VERSION "HNNBNNNYNNNNNNNNNNNNNNNNNNNNNNNNNNNNNNNNNN/4/%%%/4/'%**4NNN///"

NS_ :

BS_:

BU_: AEM BAP_Tester E_Sound FBK FLA Gateway Gateway_PAG ISE MRR_HL MRR_HR NightVision RDK SAK SAK2 SCR STH_MLBevo TopView

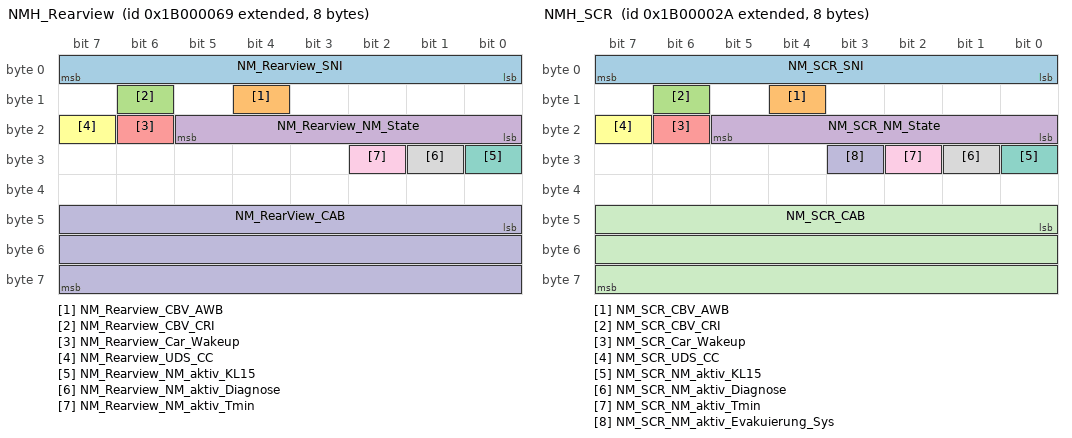
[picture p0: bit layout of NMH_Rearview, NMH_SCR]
BO_ 2600468585 NMH_Rearview: 8 TopView
 SG_ NM_Rearview_SNI : 0|8@1+ (1.0,0.0) [0.0|255] ""  Gateway,Gateway_PAG,MRR_HL,MRR_HR,NightVision,RDK,SCR,STH_MLBevo
 SG_ NM_Rearview_CBV_AWB : 12|1@1+ (1.0,0.0) [0.0|1] ""  Gateway,Gateway_PAG
 SG_ NM_Rearview_CBV_CRI : 14|1@1+ (1.0,0.0) [0.0|1] ""  Gateway,Gateway_PAG,MRR_HL,MRR_HR,NightVision,RDK,SCR,STH_MLBevo
 SG_ NM_Rearview_NM_State : 16|6@1+ (1.0,0.0) [0.0|63] ""  Vector__XXX
 SG_ NM_Rearview_Car_Wakeup : 22|1@1+ (1.0,0.0) [0.0|1] ""  Gateway
 SG_ NM_Rearview_UDS_CC : 23|1@1+ (1.0,0.0) [0.0|1] ""  Vector__XXX
 SG_ NM_Rearview_NM_aktiv_KL15 : 24|1@1+ (1.0,0.0) [0.0|1] ""  Vector__XXX
 SG_ NM_Rearview_NM_aktiv_Diagnose : 25|1@1+ (1.0,0.0) [0.0|1] ""  Vector__XXX
 SG_ NM_Rearview_NM_aktiv_Tmin : 26|1@1+ (1.0,0.0) [0.0|1] ""  Vector__XXX
 SG_ NM_RearView_CAB : 40|24@1+ (1.0,0.0) [0.0|16777215] ""  Gateway,Gateway_PAG,MRR_HL,MRR_HR,NightVision,RDK,SCR,STH_MLBevo

BO_ 2600468522 NMH_SCR: 8 SCR
 SG_ NM_SCR_SNI : 0|8@1+ (1.0,0.0) [0.0|255] ""  Gateway,Gateway_PAG,MRR_HL,MRR_HR,NightVision,RDK,STH_MLBevo,TopView
 SG_ NM_SCR_CBV_AWB : 12|1@1+ (1.0,0.0) [0.0|1] ""  Gateway,Gateway_PAG
 SG_ NM_SCR_CBV_CRI : 14|1@1+ (1.0,0.0) [0.0|1] ""  Gateway,Gateway_PAG,MRR_HL,MRR_HR,NightVision,RDK,STH_MLBevo,TopView
 SG_ NM_SCR_NM_State : 16|6@1+ (1.0,0.0) [0.0|63] ""  Vector__XXX
 SG_ NM_SCR_Car_Wakeup : 22|1@1+ (1.0,0.0) [0.0|1] ""  Gateway,Gateway_PAG
 SG_ NM_SCR_UDS_CC : 23|1@1+ (1.0,0.0) [0.0|1] ""  Vector__XXX
 SG_ NM_SCR_NM_aktiv_KL15 : 24|1@1+ (1.0,0.0) [0.0|1] ""  Vector__XXX
 SG_ NM_SCR_NM_aktiv_Diagnose : 25|1@1+ (1.0,0.0) [0.0|1] ""  Vector__XXX
 SG_ NM_SCR_NM_aktiv_Tmin : 26|1@1+ (1.0,0.0) [0.0|1] ""  Vector__XXX
 SG_ NM_SCR_NM_aktiv_Evakuierung_Sys : 27|1@1+ (1.0,0.0) [0.0|1] ""  Vector__XXX
 SG_ NM_SCR_CAB : 40|24@1+ (1.0,0.0) [0.0|16777215] ""  Gateway,Gateway_PAG,MRR_HL,MRR_HR,NightVision,RDK,STH_MLBevo,TopView

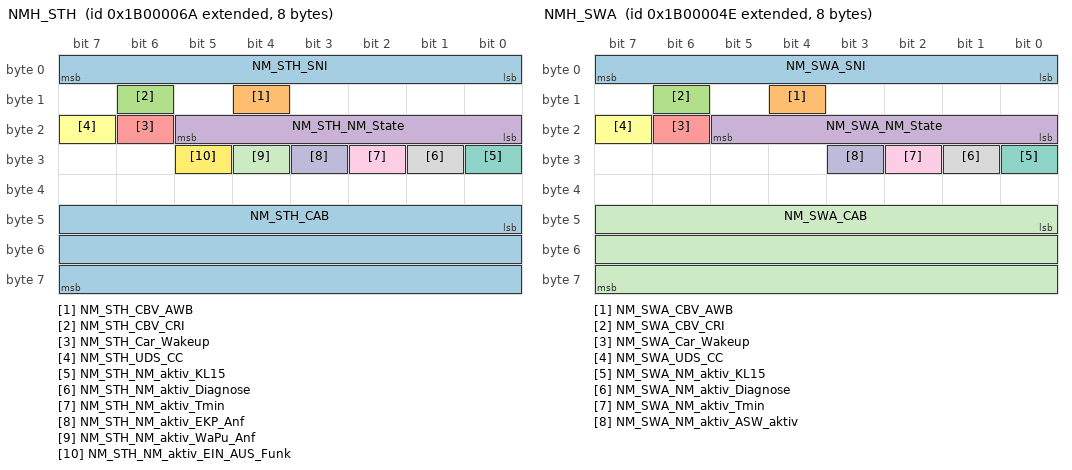
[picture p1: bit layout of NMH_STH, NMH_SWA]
BO_ 2600468586 NMH_STH: 8 STH_MLBevo
 SG_ NM_STH_SNI : 0|8@1+ (1.0,0.0) [0.0|255] ""  Gateway,Gateway_PAG,MRR_HL,MRR_HR,NightVision,RDK,SCR,TopView
 SG_ NM_STH_CBV_AWB : 12|1@1+ (1.0,0.0) [0.0|1] ""  Gateway,Gateway_PAG
 SG_ NM_STH_CBV_CRI : 14|1@1+ (1.0,0.0) [0.0|1] ""  Gateway,Gateway_PAG,MRR_HL,MRR_HR,NightVision,RDK,SCR,TopView
 SG_ NM_STH_NM_State : 16|6@1+ (1.0,0.0) [0.0|63] ""  Vector__XXX
 SG_ NM_STH_Car_Wakeup : 22|1@1+ (1.0,0.0) [0.0|1] ""  Gateway,Gateway_PAG
 SG_ NM_STH_UDS_CC : 23|1@1+ (1.0,0.0) [0.0|1] ""  Vector__XXX
 SG_ NM_STH_NM_aktiv_KL15 : 24|1@1+ (1.0,0.0) [0.0|1] ""  Vector__XXX
 SG_ NM_STH_NM_aktiv_Diagnose : 25|1@1+ (1.0,0.0) [0.0|1] ""  Vector__XXX
 SG_ NM_STH_NM_aktiv_Tmin : 26|1@1+ (1.0,0.0) [0.0|1] ""  Vector__XXX
 SG_ NM_STH_NM_aktiv_EKP_Anf : 27|1@1+ (1.0,0.0) [0.0|1] ""  Vector__XXX
 SG_ NM_STH_NM_aktiv_WaPu_Anf : 28|1@1+ (1.0,0.0) [0.0|1] ""  Vector__XXX
 SG_ NM_STH_NM_aktiv_EIN_AUS_Funk : 29|1@1+ (1.0,0.0) [0.0|1] ""  Vector__XXX
 SG_ NM_STH_CAB : 40|24@1+ (1.0,0.0) [0.0|16777215] ""  Gateway,Gateway_PAG,MRR_HL,MRR_HR,NightVision,RDK,SCR,TopView

BO_ 2600468558 NMH_SWA: 8 MRR_HR
 SG_ NM_SWA_SNI : 0|8@1+ (1.0,0.0) [0.0|255] ""  Gateway,Gateway_PAG,MRR_HL,NightVision,RDK,SCR,STH_MLBevo,TopView
 SG_ NM_SWA_CBV_AWB : 12|1@1+ (1.0,0.0) [0.0|1] ""  Gateway,Gateway_PAG
 SG_ NM_SWA_CBV_CRI : 14|1@1+ (1.0,0.0) [0.0|1] ""  Gateway,Gateway_PAG,MRR_HL,NightVision,RDK,SCR,STH_MLBevo,TopView
 SG_ NM_SWA_NM_State : 16|6@1+ (1.0,0.0) [0.0|63] ""  Vector__XXX
 SG_ NM_SWA_Car_Wakeup : 22|1@1+ (1.0,0.0) [0.0|1] ""  Gateway,Gateway_PAG
 SG_ NM_SWA_UDS_CC : 23|1@1+ (1.0,0.0) [0.0|1] ""  Vector__XXX
 SG_ NM_SWA_NM_aktiv_KL15 : 24|1@1+ (1.0,0.0) [0.0|1] ""  Vector__XXX
 SG_ NM_SWA_NM_aktiv_Diagnose : 25|1@1+ (1.0,0.0) [0.0|1] ""  Vector__XXX
 SG_ NM_SWA_NM_aktiv_Tmin : 26|1@1+ (1.0,0.0) [0.0|1] ""  Vector__XXX
 SG_ NM_SWA_NM_aktiv_ASW_aktiv : 27|1@1+ (1.0,0.0) [0.0|1] ""  Vector__XXX
 SG_ NM_SWA_CAB : 40|24@1+ (1.0,0.0) [0.0|16777215] ""  Gateway,Gateway_PAG,MRR_HL,NightVision,RDK,SCR,STH_MLBevo,TopView

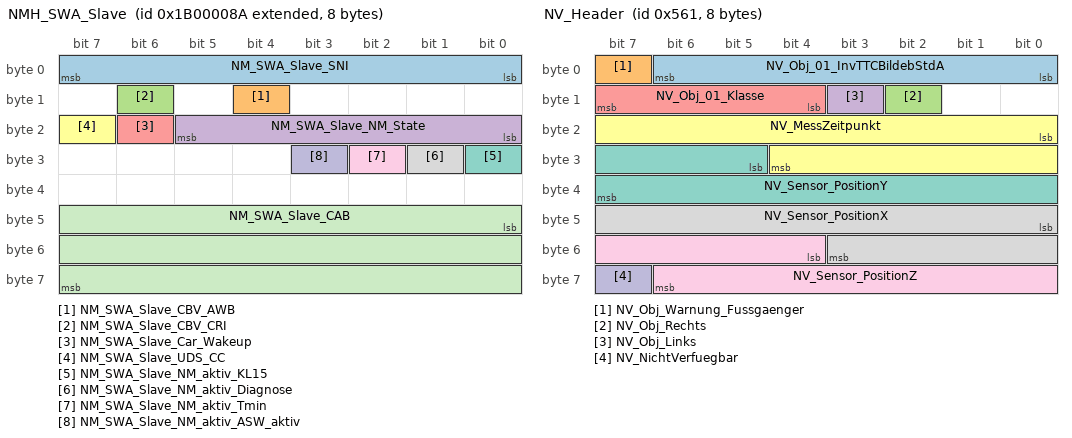
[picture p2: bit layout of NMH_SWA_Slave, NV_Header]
BO_ 2600468618 NMH_SWA_Slave: 8 MRR_HL
 SG_ NM_SWA_Slave_SNI : 0|8@1+ (1.0,0.0) [0.0|255] ""  Gateway,Gateway_PAG,MRR_HR,NightVision,RDK,SCR,STH_MLBevo,TopView
 SG_ NM_SWA_Slave_CBV_AWB : 12|1@1+ (1.0,0.0) [0.0|1] ""  Gateway,Gateway_PAG
 SG_ NM_SWA_Slave_CBV_CRI : 14|1@1+ (1.0,0.0) [0.0|1] ""  Gateway,Gateway_PAG,MRR_HR,NightVision,RDK,SCR,STH_MLBevo,TopView
 SG_ NM_SWA_Slave_NM_State : 16|6@1+ (1.0,0.0) [0.0|63] ""  Vector__XXX
 SG_ NM_SWA_Slave_Car_Wakeup : 22|1@1+ (1.0,0.0) [0.0|1] ""  Gateway
 SG_ NM_SWA_Slave_UDS_CC : 23|1@1+ (1.0,0.0) [0.0|1] ""  Vector__XXX
 SG_ NM_SWA_Slave_NM_aktiv_KL15 : 24|1@1+ (1.0,0.0) [0.0|1] ""  Vector__XXX
 SG_ NM_SWA_Slave_NM_aktiv_Diagnose : 25|1@1+ (1.0,0.0) [0.0|1] ""  Vector__XXX
 SG_ NM_SWA_Slave_NM_aktiv_Tmin : 26|1@1+ (1.0,0.0) [0.0|1] ""  Vector__XXX
 SG_ NM_SWA_Slave_NM_aktiv_ASW_aktiv : 27|1@1+ (1.0,0.0) [0.0|1] ""  Vector__XXX
 SG_ NM_SWA_Slave_CAB : 40|24@1+ (1.0,0.0) [0.0|16777215] ""  Gateway,Gateway_PAG,MRR_HR,NightVision,RDK,SCR,STH_MLBevo,TopView

BO_ 1377 NV_Header: 8 NightVision
 SG_ NV_Obj_01_InvTTCBildebStdA : 0|7@1+ (0.0625,0) [0.0000|7.8750] "Unit_Hertz"  Gateway,Gateway_PAG
 SG_ NV_Obj_Warnung_Fussgaenger : 7|1@1+ (1.0,0.0) [0.0|1] ""  Gateway,Gateway_PAG
 SG_ NV_Obj_Rechts : 10|1@1+ (1.0,0.0) [0.0|1] ""  Gateway,Gateway_PAG
 SG_ NV_Obj_Links : 11|1@1+ (1.0,0.0) [0.0|1] ""  Gateway,Gateway_PAG
 SG_ NV_Obj_01_Klasse : 12|4@1+ (1.0,0.0) [0.0|15] ""  Gateway,Gateway_PAG
 SG_ NV_MessZeitpunkt : 16|13@1+ (0.001,0) [0.000|8.190] "Unit_Secon"  Gateway,Gateway_PAG
 SG_ NV_Sensor_PositionY : 29|11@1+ (0.001,-1) [-1.000|1.046] "Unit_Meter"  Gateway,Gateway_PAG
 SG_ NV_Sensor_PositionX : 40|12@1+ (0.001,1) [1.000|5.094] "Unit_Meter"  Gateway,Gateway_PAG
 SG_ NV_Sensor_PositionZ : 52|11@1+ (0.001,0) [0.000|2.046] "Unit_Meter"  Gateway,Gateway_PAG
 SG_ NV_NichtVerfuegbar : 63|1@1+ (1.0,0.0) [0.0|1] ""  Gateway,Gateway_PAG

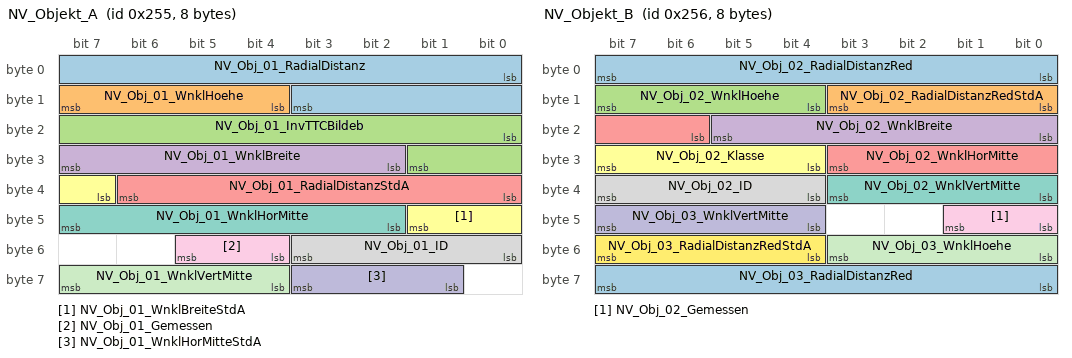
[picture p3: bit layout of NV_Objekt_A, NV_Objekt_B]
BO_ 597 NV_Objekt_A: 8 NightVision
 SG_ NV_Obj_01_RadialDistanz : 0|12@1+ (0.0625,0) [0.0000|255.8750] "Unit_Meter"  Gateway,Gateway_PAG
 SG_ NV_Obj_01_WnklHoehe : 12|4@1+ (0.03125,0) [0.00000|0.43750] "Unit_Radia"  Gateway,Gateway_PAG
 SG_ NV_Obj_01_InvTTCBildeb : 16|10@1+ (0.015625,-8) [-8.000000|7.968750] "Unit_Hertz"  Gateway,Gateway_PAG
 SG_ NV_Obj_01_WnklBreite : 26|6@1+ (0.0078125,0) [0E-7|0.4843750] "Unit_Radia"  Gateway,Gateway_PAG
 SG_ NV_Obj_01_RadialDistanzStdA : 32|7@1+ (0.25,0) [0.00|31.50] "Unit_Meter"  Gateway,Gateway_PAG
 SG_ NV_Obj_01_WnklBreiteStdA : 39|3@1+ (0.015625,0) [0.000000|0.093750] "Unit_Radia"  Gateway,Gateway_PAG
 SG_ NV_Obj_01_WnklHorMitte : 42|6@1+ (0.0078125,-0.2421875) [-0.2421875|0.2421875] "Unit_Radia"  Gateway,Gateway_PAG
 SG_ NV_Obj_01_ID : 48|4@1+ (1.0,0.0) [0.0|15] ""  Gateway,Gateway_PAG
 SG_ NV_Obj_01_Gemessen : 52|2@1+ (1.0,0.0) [0.0|3] ""  Gateway,Gateway_PAG
 SG_ NV_Obj_01_WnklHorMitteStdA : 57|3@1+ (0.015625,0) [0.000000|0.093750] "Unit_Radia"  Gateway,Gateway_PAG
 SG_ NV_Obj_01_WnklVertMitte : 60|4@1+ (0.03125,-0.21875) [-0.21875|0.21875] "Unit_Radia"  Gateway,Gateway_PAG

BO_ 598 NV_Objekt_B: 8 NightVision
 SG_ NV_Obj_02_RadialDistanzRed : 0|8@1+ (0.5,3) [3.0|130.0] "Unit_Meter"  Gateway,Gateway_PAG
 SG_ NV_Obj_02_RadialDistanzRedStdA : 8|4@1+ (1,0) [0|14] "Unit_Meter"  Gateway,Gateway_PAG
 SG_ NV_Obj_02_WnklHoehe : 12|4@1+ (0.03125,0) [0.00000|0.43750] "Unit_Radia"  Gateway,Gateway_PAG
 SG_ NV_Obj_02_WnklBreite : 16|6@1+ (0.0078125,0) [0E-7|0.4843750] "Unit_Radia"  Gateway,Gateway_PAG
 SG_ NV_Obj_02_WnklHorMitte : 22|6@1+ (0.0078125,-0.2421875) [-0.2421875|0.2421875] "Unit_Radia"  Gateway,Gateway_PAG
 SG_ NV_Obj_02_Klasse : 28|4@1+ (1.0,0.0) [0.0|15] ""  Gateway,Gateway_PAG
 SG_ NV_Obj_02_WnklVertMitte : 32|4@1+ (0.03125,-0.21875) [-0.21875|0.21875] "Unit_Radia"  Gateway,Gateway_PAG
 SG_ NV_Obj_02_ID : 36|4@1+ (1.0,0.0) [0.0|15] ""  Gateway,Gateway_PAG
 SG_ NV_Obj_02_Gemessen : 40|2@1+ (1.0,0.0) [0.0|3] ""  Gateway,Gateway_PAG
 SG_ NV_Obj_03_WnklVertMitte : 44|4@1+ (0.03125,-0.21875) [-0.21875|0.21875] "Unit_Radia"  Gateway,Gateway_PAG
 SG_ NV_Obj_03_WnklHoehe : 48|4@1+ (0.03125,0) [0.00000|0.43750] "Unit_Radia"  Gateway,Gateway_PAG
 SG_ NV_Obj_03_RadialDistanzRedStdA : 52|4@1+ (1,0) [0|14] "Unit_Meter"  Gateway,Gateway_PAG
 SG_ NV_Obj_03_RadialDistanzRed : 56|8@1+ (0.5,3) [3.0|130.0] "Unit_Meter"  Gateway,Gateway_PAG

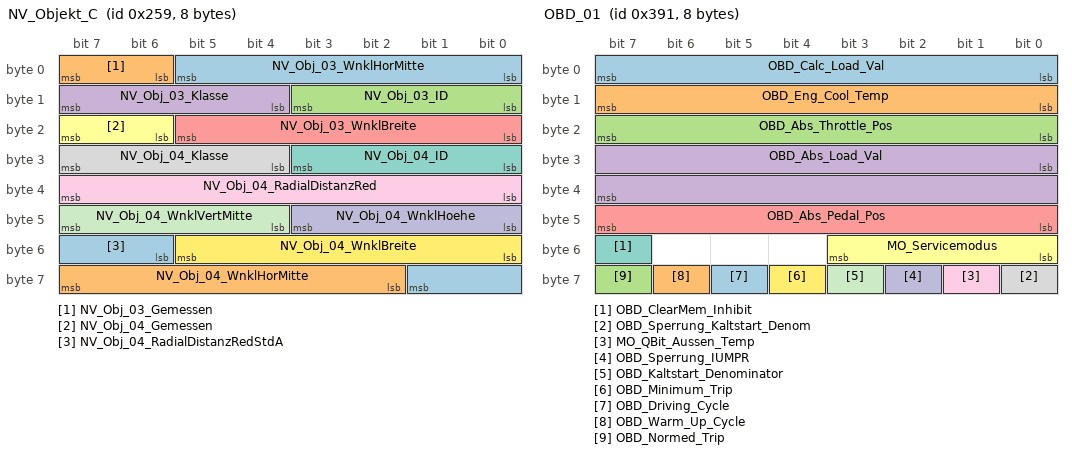
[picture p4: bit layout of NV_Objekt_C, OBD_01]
BO_ 601 NV_Objekt_C: 8 NightVision
 SG_ NV_Obj_03_WnklHorMitte : 0|6@1+ (0.0078125,-0.2421875) [-0.2421875|0.2421875] "Unit_Radia"  Gateway,Gateway_PAG
 SG_ NV_Obj_03_Gemessen : 6|2@1+ (1.0,0.0) [0.0|3] ""  Gateway,Gateway_PAG
 SG_ NV_Obj_03_ID : 8|4@1+ (1.0,0.0) [0.0|15] ""  Gateway,Gateway_PAG
 SG_ NV_Obj_03_Klasse : 12|4@1+ (1.0,0.0) [0.0|15] ""  Gateway,Gateway_PAG
 SG_ NV_Obj_03_WnklBreite : 16|6@1+ (0.0078125,0) [0E-7|0.4843750] "Unit_Radia"  Gateway,Gateway_PAG
 SG_ NV_Obj_04_Gemessen : 22|2@1+ (1.0,0.0) [0.0|3] ""  Gateway,Gateway_PAG
 SG_ NV_Obj_04_ID : 24|4@1+ (1.0,0.0) [0.0|15] ""  Gateway,Gateway_PAG
 SG_ NV_Obj_04_Klasse : 28|4@1+ (1.0,0.0) [0.0|15] ""  Gateway,Gateway_PAG
 SG_ NV_Obj_04_RadialDistanzRed : 32|8@1+ (0.5,3) [3.0|130.0] "Unit_Meter"  Gateway,Gateway_PAG
 SG_ NV_Obj_04_WnklHoehe : 40|4@1+ (0.03125,0) [0.00000|0.43750] "Unit_Radia"  Gateway,Gateway_PAG
 SG_ NV_Obj_04_WnklVertMitte : 44|4@1+ (0.03125,-0.21875) [-0.21875|0.21875] "Unit_Radia"  Gateway,Gateway_PAG
 SG_ NV_Obj_04_WnklBreite : 48|6@1+ (0.0078125,0) [0E-7|0.4843750] "Unit_Radia"  Gateway,Gateway_PAG
 SG_ NV_Obj_04_RadialDistanzRedStdA : 54|4@1+ (1,0) [0|14] "Unit_Meter"  Gateway,Gateway_PAG
 SG_ NV_Obj_04_WnklHorMitte : 58|6@1+ (0.0078125,-0.2421875) [-0.2421875|0.2421875] "Unit_Radia"  Gateway,Gateway_PAG

BO_ 1635 NVEM_02: 8 Gateway
 SG_ BEM_02_Abschaltstufen : 0|3@1+ (1.0,0.0) [0.0|7] ""  MRR_HL,MRR_HR,STH_MLBevo
 SG_ BEM_STH_Zielzeit : 3|4@1+ (5,0) [0|60] "Unit_Minut"  Vector__XXX
 SG_ BEM_MMI_Vorwarnung : 7|1@1+ (1.0,0.0) [0.0|1] ""  Vector__XXX
 SG_ NVEM_Anf_SD_schalten : 15|1@1+ (1.0,0.0) [0.0|1] ""  Vector__XXX
 SG_ BEM_Generatordiagnose : 16|2@1+ (1.0,0.0) [0.0|3] ""  Vector__XXX
 SG_ BEM_Red_Innengeblaese : 18|2@1+ (1.0,0.0) [0.0|3] ""  Vector__XXX
 SG_ BEM_STH_Einschaltverbot : 20|1@1+ (1.0,0.0) [0.0|1] ""  STH_MLBevo
 SG_ BEM_HL_Regelung_Status : 21|3@1+ (1.0,0.0) [0.0|7] ""  STH_MLBevo
 SG_ BEM_Ladezustand : 24|4@1+ (10,0) [0|100] "Unit_PerCent"  Vector__XXX
 SG_ BEM_Batteriediagnose : 28|3@1+ (1.0,0.0) [0.0|7] ""  Vector__XXX
 SG_ MIB_Stromsparmodus : 31|1@1+ (1.0,0.0) [0.0|1] ""  Vector__XXX
 SG_ BEM_REK_aktiv : 37|1@1+ (1.0,0.0) [0.0|1] ""  Vector__XXX
 SG_ NVEM_Last_Anf : 38|2@1+ (1.0,0.0) [0.0|3] ""  Vector__XXX
 SG_ BEM_UBDM : 40|8@1+ (0.05,5) [5.05|17.70] "Unit_Volt"  Vector__XXX
 SG_ BEM_UGenSoll : 48|6@1+ (0.1,10.6) [10.6|16.0] "Unit_Volt"  Vector__XXX
 SG_ BEM_Anf_KL15_schalten : 54|2@1+ (1.0,0.0) [0.0|3] ""  MRR_HL,MRR_HR
 SG_ NVEM_Batterie_Service : 56|2@1+ (1.0,0.0) [0.0|3] ""  Vector__XXX
 SG_ NVEM_Freigabe_OnlineUpdate : 58|1@1+ (1.0,0.0) [0.0|1] ""  Vector__XXX
 SG_ NVEM_Freigabe_ORU4 : 59|2@1+ (1.0,0.0) [0.0|3] ""  Vector__XXX

BO_ 913 OBD_01: 8 Gateway
 SG_ OBD_Calc_Load_Val : 0|8@1+ (0.39215686274509803,0) [0E-17|99.99999999999999765] "Unit_PerCent"  SCR
 SG_ OBD_Eng_Cool_Temp : 8|8@1+ (1,-40) [-40|215] "Unit_DegreCelsi"  SCR
 SG_ OBD_Abs_Throttle_Pos : 16|8@1+ (0.39215686274509803,0) [0E-17|99.99999999999999765] "Unit_PerCent"  SCR
 SG_ OBD_Abs_Load_Val : 24|16@1+ (0.39215686274509803,0) [0E-17|25699.99999999999939605] "Unit_PerCent"  SCR
 SG_ OBD_Abs_Pedal_Pos : 40|8@1+ (0.39215686274509803,0) [0E-17|99.99999999999999765] "Unit_PerCent"  SCR
 SG_ MO_Servicemodus : 48|4@1+ (1.0,0.0) [0.0|15] ""  Vector__XXX
 SG_ OBD_ClearMem_Inhibit : 55|1@1+ (1.0,0.0) [0.0|1] ""  Vector__XXX
 SG_ OBD_Sperrung_Kaltstart_Denom : 56|1@1+ (1.0,0.0) [0.0|1] ""  Vector__XXX
 SG_ MO_QBit_Aussen_Temp : 57|1@1+ (1.0,0.0) [0.0|1] ""  SCR
 SG_ OBD_Sperrung_IUMPR : 58|1@1+ (1.0,0.0) [0.0|1] ""  SCR
 SG_ OBD_Kaltstart_Denominator : 59|1@1+ (1.0,0.0) [0.0|1] ""  SCR
 SG_ OBD_Minimum_Trip : 60|1@1+ (1.0,0.0) [0.0|1] ""  SCR
 SG_ OBD_Driving_Cycle : 61|1@1+ (1.0,0.0) [0.0|1] ""  SCR
 SG_ OBD_Warm_Up_Cycle : 62|1@1+ (1.0,0.0) [0.0|1] ""  SCR
 SG_ OBD_Normed_Trip : 63|1@1+ (1.0,0.0) [0.0|1] ""  SCR

BO_ 2589283478 OBD_02: 8 Gateway
 SG_ OBD_Aussen_Temp_gef : 56|8@1+ (1,-40) [-40|213] "Unit_DegreCelsi"  SCR

BO_ 2549875246 OBDC_AEM_Req: 8 Gateway
 SG_ OBDC_AEM_Req_Data : 0|64@1+ (1.0,0.0) [0.0|18446744073709551615] ""  AEM

BO_ 2550006318 OBDC_AEM_Resp: 8 AEM
 SG_ OBDC_AEM_Resp_Data : 0|64@1+ (1.0,0.0) [0.0|18446744073709551615] ""  Gateway,Gateway_PAG

BO_ 2549875248 OBDC_FLA_Req: 8 Gateway
 SG_ OBDC_FLA_Req_Data : 0|64@1+ (1.0,0.0) [0.0|18446744073709551615] ""  FLA

BO_ 2550006320 OBDC_FLA_Resp: 8 FLA
 SG_ OBDC_FLA_Resp_Data : 0|64@1+ (1.0,0.0) [0.0|18446744073709551615] ""  Gateway,Gateway_PAG

BO_ 2549940736 OBDC_Funktionaler_Req_All: 8 Gateway
 SG_ OBDC_Funktionaler_Req_All_Data : 0|64@1+ (1.0,0.0) [0.0|18446744073709551615] ""  AEM,E_Sound,FLA,ISE,MRR_HL,MRR_HR,NightVision,RDK,SAK,SAK2,SCR,STH_MLBevo,TopView

BO_ 2549875239 OBDC_Nightvision_Req: 8 Gateway
 SG_ OBDC_Nightvision_Req_Data : 0|64@1+ (1.0,0.0) [0.0|18446744073709551615] ""  NightVision

BO_ 2550006311 OBDC_Nightvision_Resp: 8 NightVision
 SG_ OBDC_Nightvision_Resp_Data : 0|64@1+ (1.0,0.0) [0.0|18446744073709551615] ""  Gateway,Gateway_PAG

BO_ 2549875211 OBDC_RDK_Req: 8 Gateway
 SG_ OBDC_RDK_Req_Data : 0|64@1+ (1.0,0.0) [0.0|18446744073709551615] ""  RDK

BO_ 2550006283 OBDC_RDK_Resp: 8 RDK
 SG_ OBDC_RDK_Resp_Data : 0|64@1+ (1.0,0.0) [0.0|18446744073709551615] ""  Gateway,Gateway_PAG

BO_ 2549875305 OBDC_Rearview_Req: 8 Gateway
 SG_ OBDC_Rearview_Req_Data : 0|64@1+ (1.0,0.0) [0.0|18446744073709551615] ""  TopView

BO_ 2550006377 OBDC_Rearview_Resp: 8 TopView
 SG_ OBDC_Rearview_Resp_Data : 0|64@1+ (1.0,0.0) [0.0|18446744073709551615] ""  Gateway,Gateway_PAG

BO_ 2549875242 OBDC_SCR_Req: 8 Gateway
 SG_ OBDC_SCR_Req_Data : 0|64@1+ (1.0,0.0) [0.0|18446744073709551615] ""  SCR

BO_ 2550006314 OBDC_SCR_Resp: 8 SCR
 SG_ OBDC_SCR_Resp_Data : 0|64@1+ (1.0,0.0) [0.0|18446744073709551615] ""  Gateway,Gateway_PAG

BO_ 2549875300 OBDC_Soundaktor2_Req: 8 Gateway
 SG_ OBDC_Soundaktor2_Req_Data : 0|64@1+ (1.0,0.0) [0.0|18446744073709551615] ""  E_Sound,SAK2

BO_ 2550006372 OBDC_Soundaktor2_Resp: 8 E_Sound
 SG_ OBDC_Soundaktor2_Resp_Data : 0|64@1+ (1.0,0.0) [0.0|18446744073709551615] ""  Gateway,Gateway_PAG

BO_ 2549875228 OBDC_Soundaktor_Req: 8 Gateway
 SG_ OBDC_Soundaktor_Req_Data : 0|64@1+ (1.0,0.0) [0.0|18446744073709551615] ""  ISE,SAK

BO_ 2550006300 OBDC_Soundaktor_Resp: 8 ISE
 SG_ OBDC_Soundaktor_Resp_Data : 0|64@1+ (1.0,0.0) [0.0|18446744073709551615] ""  Gateway,Gateway_PAG

BO_ 2549875306 OBDC_STH_Req: 8 Gateway
 SG_ OBDC_STH_Req_Data : 0|64@1+ (1.0,0.0) [0.0|18446744073709551615] ""  STH_MLBevo

BO_ 2550006378 OBDC_STH_Resp: 8 STH_MLBevo
 SG_ OBDC_STH_Resp_Data : 0|64@1+ (1.0,0.0) [0.0|18446744073709551615] ""  Gateway,Gateway_PAG

BO_ 2549875338 OBDC_SWA_2_Req: 8 Gateway
 SG_ OBDC_SWA_2_Req_Data : 0|64@1+ (1.0,0.0) [0.0|18446744073709551615] ""  MRR_HL

BO_ 2550006410 OBDC_SWA_2_Resp: 8 MRR_HL
 SG_ OBDC_SWA_2_Resp_Data : 0|64@1+ (1.0,0.0) [0.0|18446744073709551615] ""  Gateway,Gateway_PAG

BO_ 2549875278 OBDC_SWA_Req: 8 Gateway
 SG_ OBDC_SWA_Req_Data : 0|64@1+ (1.0,0.0) [0.0|18446744073709551615] ""  MRR_HR

BO_ 2550006350 OBDC_SWA_Resp: 8 MRR_HR
 SG_ OBDC_SWA_Resp_Data : 0|64@1+ (1.0,0.0) [0.0|18446744073709551615] ""  Gateway,Gateway_PAG

BO_ 2589283656 ORU_01: 8 Gateway
 SG_ ORU_Warnung : 58|2@1+ (1.0,0.0) [0.0|3] ""  Vector__XXX
 SG_ ORU_Status : 61|3@1+ (1.0,0.0) [0.0|7] ""  E_Sound,ISE,RDK

BO_ 1175 Parkhilfe_01: 8 Gateway
 SG_ PH_Visualisierung : 0|3@1+ (1.0,0.0) [0.0|7] ""  TopView
 SG_ PDC_Tonausgabe_Front : 4|4@1+ (1.0,0.0) [0.0|15] ""  Vector__XXX
 SG_ PDC_Tonausgabe_Heck : 8|4@1+ (1.0,0.0) [0.0|15] ""  Vector__XXX
 SG_ PH_nachtr_Stopp_Anf : 12|1@1+ (1.0,0.0) [0.0|1] ""  Vector__XXX
 SG_ PH_Abschaltursache : 13|3@1+ (1.0,0.0) [0.0|7] ""  Vector__XXX
 SG_ PH_Opt_Anzeige_V_ein : 16|1@1+ (1.0,0.0) [0.0|1] ""  Vector__XXX
 SG_ PH_Opt_Anzeige_H_ein : 17|1@1+ (1.0,0.0) [0.0|1] ""  Vector__XXX
 SG_ PH_Opt_Anz_V_Hindernis : 18|1@1+ (1.0,0.0) [0.0|1] ""  Vector__XXX
 SG_ PH_Opt_Anz_H_Hindernis : 19|1@1+ (1.0,0.0) [0.0|1] ""  Vector__XXX
 SG_ PH_Tongeber_V_aktiv : 20|1@1+ (1.0,0.0) [0.0|1] ""  Vector__XXX
 SG_ PH_Tongeber_H_aktiv : 21|1@1+ (1.0,0.0) [0.0|1] ""  Vector__XXX
 SG_ PH_Tongeber_mute : 22|1@1+ (1.0,0.0) [0.0|1] ""  Vector__XXX
 SG_ PH_Anf_Audioabsenkung : 23|1@1+ (1.0,0.0) [0.0|1] ""  Vector__XXX
 SG_ PH_Tongeber_H_verfuegbar : 24|1@1+ (1.0,0.0) [0.0|1] ""  Vector__XXX
 SG_ PLA_Anf_Aufschaltung_RVC : 25|1@1+ (1.0,0.0) [0.0|1] ""  TopView
 SG_ PH_Taster : 28|2@1+ (1.0,0.0) [0.0|3] ""  TopView
 SG_ PH_Anf_Verdeck : 30|2@1+ (1.0,0.0) [0.0|3] ""  Vector__XXX
 SG_ PH_Frequenz_hinten : 32|4@1+ (1,0) [0|15] ""  Vector__XXX
 SG_ PH_Lautstaerke_hinten : 36|4@1+ (1,0) [0|15] ""  Vector__XXX
 SG_ PH_Frequenz_vorn : 40|4@1+ (1,0) [0|15] ""  Vector__XXX
 SG_ PH_Lautstaerke_vorn : 44|4@1+ (1,0) [0|15] ""  Vector__XXX
 SG_ PH_StartStopp_Info : 49|2@1+ (1.0,0.0) [0.0|3] ""  Vector__XXX
 SG_ PH_Stoermeldung : 52|4@1+ (1.0,0.0) [0.0|15] ""  Vector__XXX
 SG_ PH_defekt : 56|1@1+ (1.0,0.0) [0.0|1] ""  Vector__XXX
 SG_ PH_gestoert : 57|1@1+ (1.0,0.0) [0.0|1] ""  Vector__XXX
 SG_ PH_Systemzustand : 58|3@1+ (1.0,0.0) [0.0|7] ""  TopView
 SG_ PH_Display_Kundenwunsch : 61|2@1+ (1.0,0.0) [0.0|3] ""  Vector__XXX

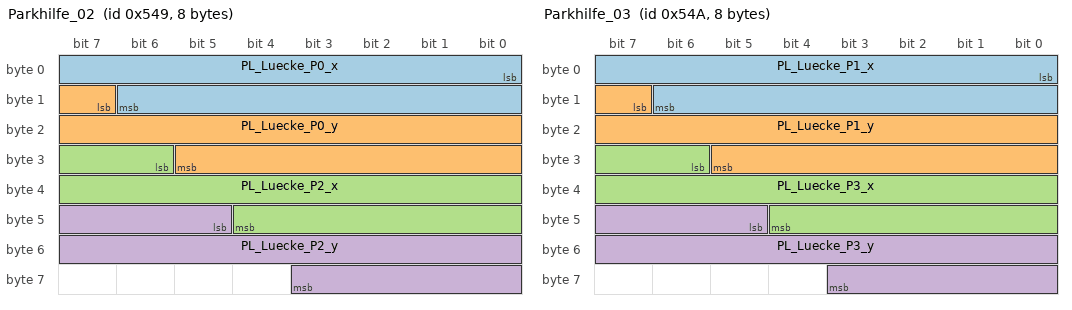
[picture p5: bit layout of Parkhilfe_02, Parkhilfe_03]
BO_ 1353 Parkhilfe_02: 8 Gateway
 SG_ PL_Luecke_P0_x : 0|15@1+ (2,-32767) [-32767|32767] "Unit_Centimeter"  TopView
 SG_ PL_Luecke_P0_y : 15|15@1+ (2,-32767) [-32767|32767] "Unit_Centimeter"  TopView
 SG_ PL_Luecke_P2_x : 30|15@1+ (2,-32767) [-32767|32767] "Unit_Centimeter"  TopView
 SG_ PL_Luecke_P2_y : 45|15@1+ (2,-32767) [-32767|32767] "Unit_Centimeter"  TopView

BO_ 1354 Parkhilfe_03: 8 Gateway
 SG_ PL_Luecke_P1_x : 0|15@1+ (2,-32767) [-32767|32767] "Unit_Centimeter"  TopView
 SG_ PL_Luecke_P1_y : 15|15@1+ (2,-32767) [-32767|32767] "Unit_Centimeter"  TopView
 SG_ PL_Luecke_P3_x : 30|15@1+ (2,-32767) [-32767|32767] "Unit_Centimeter"  TopView
 SG_ PL_Luecke_P3_y : 45|15@1+ (2,-32767) [-32767|32767] "Unit_Centimeter"  TopView

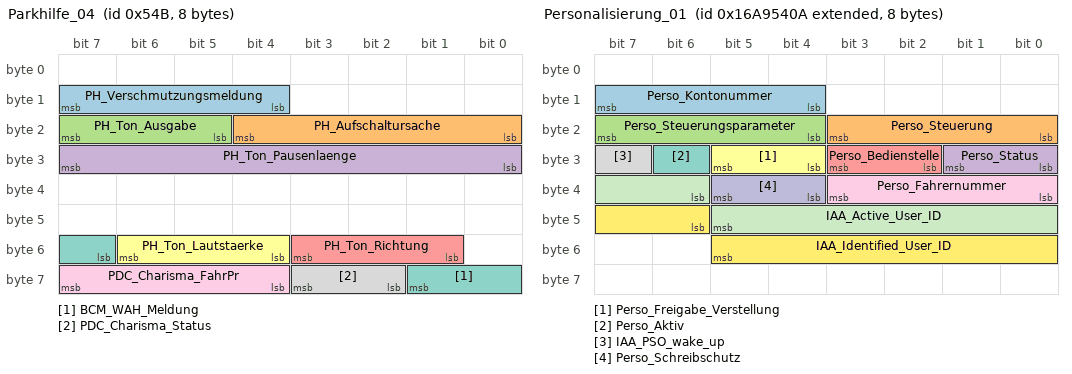
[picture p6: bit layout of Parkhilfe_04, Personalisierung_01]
BO_ 1355 Parkhilfe_04: 8 Gateway
 SG_ PH_Verschmutzungsmeldung : 12|4@1+ (1.0,0.0) [0.0|15] ""  Vector__XXX
 SG_ PH_Aufschaltursache : 16|5@1+ (1.0,0.0) [0.0|31] ""  TopView
 SG_ PH_Ton_Ausgabe : 21|3@1+ (1.0,0.0) [0.0|7] ""  Vector__XXX
 SG_ PH_Ton_Pausenlaenge : 24|8@1+ (1.0,0.0) [0.0|255] ""  Vector__XXX
 SG_ PH_Ton_Richtung : 49|3@1+ (1.0,0.0) [0.0|7] ""  Vector__XXX
 SG_ PH_Ton_Lautstaerke : 52|3@1+ (1.0,0.0) [0.0|7] ""  Vector__XXX
 SG_ BCM_WAH_Meldung : 55|3@1+ (1.0,0.0) [0.0|7] ""  Vector__XXX
 SG_ PDC_Charisma_Status : 58|2@1+ (1.0,0.0) [0.0|3] ""  Vector__XXX
 SG_ PDC_Charisma_FahrPr : 60|4@1+ (1.0,0.0) [0.0|15] ""  Vector__XXX

BO_ 2527679498 Personalisierung_01: 8 Gateway
 SG_ Perso_Kontonummer : 12|4@1+ (1.0,0.0) [0.0|15] ""  MRR_HR,NightVision
 SG_ Perso_Steuerung : 16|4@1+ (1.0,0.0) [0.0|15] ""  MRR_HR,NightVision
 SG_ Perso_Steuerungsparameter : 20|4@1+ (1.0,0.0) [0.0|15] ""  MRR_HR,NightVision
 SG_ Perso_Status : 24|2@1+ (1.0,0.0) [0.0|3] ""  MRR_HR,NightVision
 SG_ Perso_Bedienstelle : 26|2@1+ (1.0,0.0) [0.0|3] ""  Vector__XXX
 SG_ Perso_Freigabe_Verstellung : 28|2@1+ (1.0,0.0) [0.0|3] ""  Vector__XXX
 SG_ Perso_Aktiv : 30|1@1+ (1.0,0.0) [0.0|1] ""  Vector__XXX
 SG_ IAA_PSO_wake_up : 31|1@1+ (1.0,0.0) [0.0|1] ""  Vector__XXX
 SG_ Perso_Fahrernummer : 32|4@1+ (1.0,0.0) [0.0|15] ""  Vector__XXX
 SG_ Perso_Schreibschutz : 36|2@1+ (1.0,0.0) [0.0|3] ""  Vector__XXX
 SG_ IAA_Active_User_ID : 38|8@1+ (1,0) [0|255] "Unit_None"  Vector__XXX
 SG_ IAA_Identified_User_ID : 46|8@1+ (1,0) [0|255] "Unit_None"  Vector__XXX

BO_ 319 PreCrash_02: 8 Gateway
 SG_ PreCrash_02_CRC : 0|8@1+ (1,0) [0|255] ""  Vector__XXX
 SG_ PreCrash_02_BZ : 8|4@1+ (1,0) [0|15] ""  Vector__XXX
 SG_ PreCrash_Charisma_FahrPr : 12|4@1+ (1.0,0.0) [0.0|15] ""  Vector__XXX
 SG_ PreCrash_Charisma_Status : 16|2@1+ (1.0,0.0) [0.0|3] ""  Vector__XXX
 SG_ PreCrash_Schiebedach_schliessen : 18|1@1+ (1.0,0.0) [0.0|1] ""  Vector__XXX
 SG_ PreCrash_Fenster_schliessen : 19|1@1+ (1.0,0.0) [0.0|1] ""  Vector__XXX
 SG_ PreCrash_Blinken : 20|3@1+ (1.0,0.0) [0.0|7] ""  Vector__XXX
 SG_ SC_PreSense_FCWP : 23|1@1+ (1.0,0.0) [0.0|1] ""  NightVision
 SG_ PreCrash_Tueren_Verriegeln : 24|1@1+ (1.0,0.0) [0.0|1] ""  Vector__XXX
 SG_ PreCrash_Anforderung_AFR : 26|3@1+ (1.0,0.0) [0.0|7] ""  Vector__XXX
 SG_ SC_PreCrash_LED : 29|2@1+ (1.0,0.0) [0.0|3] ""  Vector__XXX
 SG_ PreCrash_FS_Pneumatik_ansteuern : 31|1@1+ (1.0,0.0) [0.0|1] ""  Vector__XXX
 SG_ PreCrash_BFS_Pneumatik_ansteuern : 32|1@1+ (1.0,0.0) [0.0|1] ""  Vector__XXX
 SG_ PreCrash_Fo_Pneumatik_ansteuern : 33|1@1+ (1.0,0.0) [0.0|1] ""  Vector__XXX
 SG_ PreCrash_FS_Sitzlehne_verfahren : 34|3@1+ (1.0,0.0) [0.0|7] ""  Vector__XXX
 SG_ PreCrash_BFS_Sitzlehne_verfahren : 37|3@1+ (1.0,0.0) [0.0|7] ""  Vector__XXX
 SG_ PreCrash_Fo_Sitzlehne_verfahren : 40|3@1+ (1.0,0.0) [0.0|7] ""  Vector__XXX
 SG_ PreCrash_FS_KSV_verfahren : 43|4@1+ (1.0,0.0) [0.0|15] ""  Vector__XXX
 SG_ PreCrash_BFS_KSV_verfahren : 47|4@1+ (1.0,0.0) [0.0|15] ""  Vector__XXX
 SG_ PreCrash_Fo_KSV_verfahren : 51|4@1+ (1.0,0.0) [0.0|15] ""  Vector__XXX
 SG_ SC_PreCrash_Warnung : 56|4@1+ (1.0,0.0) [0.0|15] ""  NightVision
 SG_ SC_PreCrash_Texte : 60|4@1+ (1.0,0.0) [0.0|15] ""  Vector__XXX

BO_ 1122 PSD_04: 8 Gateway
 SG_ PSD_Segment_ID : 0|6@1+ (1,0) [2|63] ""  FLA,NightVision
 SG_ PSD_Vorgaenger_Segment_ID : 6|6@1+ (1,0) [2|63] ""  FLA,NightVision
 SG_ PSD_Segmentlaenge : 12|7@1+ (2,0) [0|254] "Unit_Meter"  FLA,NightVision
 SG_ PSD_Strassenkategorie : 19|3@1+ (1.0,0.0) [0.0|7] ""  FLA,NightVision
 SG_ PSD_Endkruemmung : 22|8@1+ (1,0) [0|254] "Unit_None"  FLA,NightVision
 SG_ PSD_Endkruemmung_Vorz : 30|1@1+ (1.0,0.0) [0.0|1] ""  FLA,NightVision
 SG_ PSD_Idenditaets_ID : 31|6@1+ (1,0) [2|63] ""  FLA,NightVision
 SG_ PSD_ADAS_Qualitaet : 37|1@1+ (1.0,0.0) [0.0|1] ""  FLA,NightVision
 SG_ PSD_wahrscheinlichster_Pfad : 38|1@1+ (1.0,0.0) [0.0|1] ""  FLA,NightVision
 SG_ PSD_Geradester_Pfad : 39|1@1+ (1.0,0.0) [0.0|1] ""  FLA,NightVision
 SG_ PSD_Fahrspuren_Anzahl : 40|3@1+ (1.0,0.0) [0.0|7] ""  FLA,NightVision
 SG_ PSD_Bebauung : 43|1@1+ (1.0,0.0) [0.0|1] ""  FLA,NightVision
 SG_ PSD_Segment_Komplett : 44|1@1+ (1.0,0.0) [0.0|1] ""  FLA,NightVision
 SG_ PSD_Rampe : 45|2@1+ (1.0,0.0) [0.0|3] ""  FLA,NightVision
 SG_ PSD_Anfangskruemmung : 47|8@1+ (1,0) [0|254] ""  FLA,NightVision
 SG_ PSD_Anfangskruemmung_Vorz : 55|1@1+ (1.0,0.0) [0.0|1] ""  FLA,NightVision
 SG_ PSD_Abzweigerichtung : 56|1@1+ (1.0,0.0) [0.0|1] ""  FLA,NightVision
 SG_ PSD_Abzweigewinkel : 57|7@1+ (1.417323,0) [0.000000|180.000021] ""  FLA,NightVision

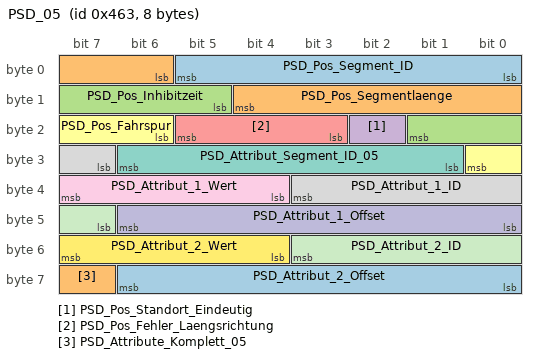
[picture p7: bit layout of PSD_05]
BO_ 1123 PSD_05: 8 Gateway
 SG_ PSD_Pos_Segment_ID : 0|6@1+ (1,0) [2|63] ""  FLA,NightVision
 SG_ PSD_Pos_Segmentlaenge : 6|7@1+ (2,0) [0|254] "Unit_Meter"  FLA,NightVision
 SG_ PSD_Pos_Inhibitzeit : 13|5@1+ (10,0) [0|310] "Unit_MilliSecon"  FLA,NightVision
 SG_ PSD_Pos_Standort_Eindeutig : 18|1@1+ (1.0,0.0) [0.0|1] ""  FLA,NightVision
 SG_ PSD_Pos_Fehler_Laengsrichtung : 19|3@1+ (1.0,0.0) [0.0|7] ""  FLA,NightVision
 SG_ PSD_Pos_Fahrspur : 22|3@1+ (1.0,0.0) [0.0|7] ""  FLA,NightVision
 SG_ PSD_Attribut_Segment_ID_05 : 25|6@1+ (1,0) [2|63] ""  FLA,NightVision
 SG_ PSD_Attribut_1_ID : 31|5@1+ (1,0) [1|31] ""  FLA,NightVision
 SG_ PSD_Attribut_1_Wert : 36|4@1+ (1.0,0.0) [0.0|15] ""  FLA,NightVision
 SG_ PSD_Attribut_1_Offset : 40|7@1+ (2,0) [0|254] "Unit_Meter"  FLA,NightVision
 SG_ PSD_Attribut_2_ID : 47|5@1+ (1,0) [1|31] ""  FLA,NightVision
 SG_ PSD_Attribut_2_Wert : 52|4@1+ (1.0,0.0) [0.0|15] ""  FLA,NightVision
 SG_ PSD_Attribut_2_Offset : 56|7@1+ (2,0) [0|254] "Unit_Meter"  FLA,NightVision
 SG_ PSD_Attribute_Komplett_05 : 63|1@1+ (1.0,0.0) [0.0|1] ""  FLA,NightVision

BO_ 1124 PSD_06: 8 Gateway
 SG_ PSD_06_Mux M  : 0|3@1+ (1.0,0.0) [0.0|7] ""  FLA,NightVision
 SG_ PSD_Sys_Segment_ID m0  : 3|6@1+ (1,0) [2|63] ""  FLA,NightVision
 SG_ PSD_Attribut_Segment_ID m1  : 3|6@1+ (1,0) [2|63] ""  FLA,NightVision
 SG_ PSD_Ges_Segment_ID m2  : 3|6@1+ (1,0) [2|63] ""  FLA,NightVision
 SG_ PSD_Baum_Laenge_VZ m3  : 3|1@1+ (1.0,0.0) [0.0|1] ""  FLA,NightVision
 SG_ PSD_Steigung_1_Segment_ID m4  : 3|6@1+ (1,0) [2|63] ""  FLA,NightVision
 SG_ PSD_Baum_Laenge m3  : 4|25@1+ (0.00001,0) [0.00000|180.00000] "Unit_DegreOfArc"  FLA,NightVision
 SG_ PSD_Sys_Laendercode m0  : 9|8@1+ (1.0,0.0) [0.0|255] ""  FLA,NightVision
 SG_ PSD_Attribut_3_ID m1  : 9|5@1+ (1,0) [1|31] ""  FLA,NightVision
 SG_ PSD_Ges_Offset m2  : 9|7@1+ (2,0) [0|254] "Unit_Meter"  FLA,NightVision
 SG_ PSD_Steigung_1_A_Steigung m4  : 9|7@1+ (0.12,0) [0.00|15.00] "Unit_PerCent"  FLA,NightVision
 SG_ PSD_Attribut_3_Offset m1  : 14|7@1+ (2,0) [0|254] "Unit_Meter"  FLA,NightVision
 SG_ PSD_Ges_Geschwindigkeit m2  : 16|5@1+ (1.0,0.0) [0.0|31] ""  FLA,NightVision
 SG_ PSD_Steigung_1_A_Vorz m4  : 16|1@1+ (1.0,0.0) [0.0|1] ""  FLA,NightVision
 SG_ PSD_Sys_Geschwindigkeit_Einheit m0  : 17|1@1+ (1.0,0.0) [0.0|1] ""  FLA,NightVision
 SG_ PSD_Steigung_1_A_Offset m4  : 17|7@1+ (2,0) [0|254] "Unit_Meter"  FLA,NightVision
 SG_ PSD_Sys_Verkehrsrichtung m0  : 18|1@1+ (1.0,0.0) [0.0|1] ""  FLA,NightVision
 SG_ PSD_Sys_Geometrieguete m0  : 19|2@1+ (1.0,0.0) [0.0|3] ""  FLA,NightVision
 SG_ PSD_Sys_Mapmatchingguete m0  : 21|2@1+ (1.0,0.0) [0.0|3] ""  FLA,NightVision
 SG_ PSD_Attribut_3_Wert m1  : 21|4@1+ (1.0,0.0) [0.0|15] ""  FLA,NightVision
 SG_ PSD_Ges_Typ m2  : 21|2@1+ (1.0,0.0) [0.0|3] ""  FLA,NightVision
 SG_ PSD_Sys_Alter_Karte m0  : 23|3@1+ (1.0,0.0) [0.0|7] ""  FLA,NightVision
 SG_ PSD_Ges_Spur_Geschw_Begrenzung m2  : 23|6@1+ (1.0,0.0) [0.0|63] ""  FLA,NightVision
 SG_ PSD_Steigung_1_B_Steigung m4  : 24|7@1+ (0.12,0) [0.00|15.00] "Unit_PerCent"  FLA,NightVision
 SG_ PSD_Attribut_4_ID m1  : 25|5@1+ (1,0) [1|31] ""  FLA,NightVision
 SG_ PSD_Sys_Zielfuehrung m0  : 26|1@1+ (1.0,0.0) [0.0|1] ""  FLA,NightVision
 SG_ PSD_Sys_US_State m0  : 27|6@1+ (1.0,0.0) [0.0|63] ""  FLA,NightVision
 SG_ PSD_Ges_Geschwindigkeit_Gespann m2  : 29|2@1+ (1.0,0.0) [0.0|3] ""  FLA,NightVision
 SG_ PSD_Baum_Breite_VZ m3  : 29|1@1+ (1.0,0.0) [0.0|1] ""  FLA,NightVision
 SG_ PSD_Attribut_4_Wert m1  : 30|4@1+ (1,0) [0|15] ""  FLA,NightVision
 SG_ PSD_Baum_Breite m3  : 30|24@1+ (0.00001,0) [0.00000|90.00000] "Unit_DegreOfArc"  FLA,NightVision
 SG_ PSD_Ges_Geschwindigkeit_Witter m2  : 31|2@1+ (1.0,0.0) [0.0|3] ""  FLA,NightVision
 SG_ PSD_Steigung_1_B_Vorz m4  : 31|1@1+ (1.0,0.0) [0.0|1] ""  FLA,NightVision
 SG_ PSD_Steigung_1_B_Offset m4  : 32|7@1+ (2,0) [0|254] "Unit_Meter"  FLA,NightVision
 SG_ PSD_Sys_Quali_Geometrien m0  : 33|3@1+ (1,0) [0|7] "Unit_None"  FLA,NightVision
 SG_ PSD_Ges_Geschwindigkeit_Tag_Anf m2  : 33|3@1+ (1.0,0.0) [0.0|7] ""  FLA,NightVision
 SG_ PSD_Attribut_4_Offset m1  : 34|7@1+ (2,0) [0|254] "Unit_Meter"  FLA,NightVision
 SG_ PSD_Sys_Quali_Ortsinfo m0  : 36|2@1+ (1,0) [0|3] "Unit_None"  FLA,NightVision
 SG_ PSD_Ges_Geschwindigkeit_Tag_Ende m2  : 36|3@1+ (1.0,0.0) [0.0|7] ""  FLA,NightVision
 SG_ PSD_Sys_Quali_verfuegbar m0  : 38|1@1+ (1.0,0.0) [0.0|1] ""  FLA,NightVision
 SG_ PSD_Sys_Zielfuehrung_geaendert m0  : 39|1@1+ (1.0,0.0) [0.0|1] ""  FLA,NightVision
 SG_ PSD_Ges_Geschwindigkeit_Std_Anf m2  : 39|5@1+ (1,0) [0|24] "Unit_Hours"  FLA,NightVision
 SG_ PSD_Steigung_1_Attribute_kompl m4  : 39|1@1+ (1.0,0.0) [0.0|1] ""  FLA,NightVision
 SG_ PSD_Sys_Geometrieguete_erweitert m0  : 40|8@1+ (1.0,0.0) [0.0|255] ""  FLA,NightVision
 SG_ PSD_Steigung_2_Segment_ID m4  : 40|6@1+ (1,0) [2|63] ""  FLA,NightVision
 SG_ PSD_Attribut_5_ID m1  : 41|5@1+ (1,0) [1|31] ""  FLA,NightVision
 SG_ PSD_Ges_Geschwindigkeit_Std_Ende m2  : 44|5@1+ (1,0) [0|24] "Unit_Hours"  FLA,NightVision
 SG_ PSD_Attribut_5_Offset m1  : 46|7@1+ (2,0) [0|254] "Unit_Meter"  FLA,NightVision
 SG_ PSD_Steigung_2_Steigung m4  : 46|7@1+ (0.12,0) [0.00|15.00] "Unit_PerCent"  FLA,NightVision
 SG_ PSD_Sys_Quali_sonstige_Attribute m0  : 48|3@1+ (1,0) [0|7] "Unit_None"  FLA,NightVision
 SG_ PSD_Ges_Ueberholverbot m2  : 49|2@1+ (1.0,0.0) [0.0|3] ""  FLA,NightVision
 SG_ PSD_Sys_Quali_Steigungen m0  : 51|3@1+ (1,0) [0|7] ""  FLA,NightVision
 SG_ PSD_Ges_Wechselverkehrszeichen m2  : 51|3@1+ (1.0,0.0) [0.0|7] ""  FLA,NightVision
 SG_ PSD_Attribut_5_Wert m1  : 53|4@1+ (1,0) [0|15] ""  FLA,NightVision
 SG_ PSD_Steigung_2_Vorz m4  : 53|1@1+ (1.0,0.0) [0.0|1] ""  FLA,NightVision
 SG_ PSD_Sys_Quali_Strassenkennz m0  : 54|3@1+ (1,0) [0|7] "Unit_None"  FLA,NightVision
 SG_ PSD_Wechselverkehrszeichen_Typ m2  : 54|2@1+ (1.0,0.0) [0.0|3] ""  FLA,NightVision
 SG_ PSD_Baum_Ausrichtung m3  : 54|10@1+ (0.3515625,0) [0E-7|359.6484375] "Unit_DegreOfArc"  FLA,NightVision
 SG_ PSD_Steigung_2_Offset m4  : 54|7@1+ (2,0) [0|254] "Unit_Meter"  FLA,NightVision
 SG_ PSD_Ges_Gesetzlich_Kategorie m2  : 56|3@1+ (1.0,0.0) [0.0|7] ""  FLA,NightVision
 SG_ PSD_Sys_Quali_Tempolimits m0  : 57|3@1+ (1,0) [0|7] "Unit_None"  FLA,NightVision
 SG_ PSD_Attribute_Komplett_06 m1  : 57|1@1+ (1.0,0.0) [0.0|1] ""  FLA,NightVision
 SG_ PSD_Ges_Gesetzlich_Zusatz m2  : 59|2@1+ (1.0,0.0) [0.0|3] ""  FLA,NightVision
 SG_ PSD_Sys_Quali_Vorfahrtsregelung m0  : 60|3@1+ (1,0) [0|7] "Unit_None"  FLA,NightVision
 SG_ PSD_Ges_Verkehrszeichen_Quelle m2  : 61|2@1+ (1.0,0.0) [0.0|3] ""  FLA,NightVision
 SG_ PSD_Steigung_2_Attribute_kompl m4  : 61|1@1+ (1.0,0.0) [0.0|1] ""  FLA,NightVision
 SG_ PSD_Ges_Attribute_Komplett m2  : 63|1@1+ (1.0,0.0) [0.0|1] ""  FLA,NightVision

BO_TX_BU_ 1635 :Gateway,Gateway_PAG;
BO_TX_BU_ 913 :Gateway,Gateway_PAG;
BO_TX_BU_ 2589283478 :Gateway,Gateway_PAG;
BO_TX_BU_ 2549875246 :Gateway,Gateway_PAG;
BO_TX_BU_ 2549875248 :Gateway,Gateway_PAG;
BO_TX_BU_ 2549940736 :Gateway,Gateway_PAG;
BO_TX_BU_ 2549875239 :Gateway,Gateway_PAG;
BO_TX_BU_ 2549875211 :Gateway,Gateway_PAG;
BO_TX_BU_ 2549875305 :Gateway,Gateway_PAG;
BO_TX_BU_ 2549875242 :Gateway,Gateway_PAG;
BO_TX_BU_ 2549875300 :Gateway,Gateway_PAG;
BO_TX_BU_ 2550006372 :E_Sound,SAK2;
BO_TX_BU_ 2549875228 :Gateway,Gateway_PAG;
BO_TX_BU_ 2550006300 :ISE,SAK;
BO_TX_BU_ 2549875306 :Gateway,Gateway_PAG;
BO_TX_BU_ 2549875338 :Gateway,Gateway_PAG;
BO_TX_BU_ 2549875278 :Gateway,Gateway_PAG;
BO_TX_BU_ 2589283656 :Gateway,Gateway_PAG;
BO_TX_BU_ 1175 :Gateway,Gateway_PAG;
BO_TX_BU_ 1353 :Gateway,Gateway_PAG;
BO_TX_BU_ 1354 :Gateway,Gateway_PAG;
BO_TX_BU_ 1355 :Gateway,Gateway_PAG;
BO_TX_BU_ 2527679498 :Gateway,Gateway_PAG;
BO_TX_BU_ 319 :Gateway,Gateway_PAG;
BO_TX_BU_ 1122 :Gateway,Gateway_PAG;
BO_TX_BU_ 1123 :Gateway,Gateway_PAG;
BO_TX_BU_ 1124 :Gateway,Gateway_PAG;
CM_ BO_ 2600468522 "CAN_NM_PDU MLBevo";
CM_ BO_ 2600468558 "CAN_NM_PDU MLBevo";
CM_ BO_ 1635 "DLC=8 ab D4 gültig";
CM_ BO_ 2549940736 "VDC funktionaler Request auf CANHS";
CM_ BO_ 1175 "neue Struktur ab MQB ohne KD-Fehler";
CM_ BO_ 1355 "neue Struktur ab MQB ohne KD-Fehler";

CM_ SG_ 2600468585 NM_RearView_CAB "CAB = Clusteraktivbits";
CM_ SG_ 2600468585 NM_Rearview_Car_Wakeup "Car Wakeup (Gateway wertet aus)
";
CM_ SG_ 2600468585 NM_Rearview_CBV_AWB "Das Signal ist zu setzen, wenn das SG aktiv den Bus geweckt hat
0 = Passiver_WakeUp = SG hat das Netzwerk nicht aktiv geweckt
1 = Akitiver_WakeUp = SG hat das Netzwerk aktiv geweckt";
CM_ SG_ 2600468585 NM_Rearview_CBV_CRI "Das Signal ist dauerhaft gesetzt, wenn das NM-Layout Cluster- Anforderungen enthält";
CM_ SG_ 2600468585 NM_Rearview_NM_aktiv_Diagnose "Diagnose befindet sich nach VW80124 in einer NonDefaultDiagnostic-Session, z.B. ExtendedDiagnostic-Session";
CM_ SG_ 2600468585 NM_Rearview_NM_aktiv_KL15 "Steuergerät hat KL15-EIN erkannt";
CM_ SG_ 2600468585 NM_Rearview_NM_aktiv_Tmin "Mindestaktivzeit ist noch nicht abgelaufen (bei jedem Weckereignis wird die Mindestaktivzeit neu gestartet)";
CM_ SG_ 2600468585 NM_Rearview_NM_State "1 = Zustand Repeat Message (<-- Bus-Sleep Mode)
2 = Zustand Repeat Message (<-- Prepare Bus-Sleep Mode)
4 = Zustand Normal Operation (<-- Repeat Message)
8 = Zustand Normal Operation (<-- Ready Sleep)";
CM_ SG_ 2600468585 NM_Rearview_SNI "Source Node-Identifier (SNI) identifiziert den Sender der NM-Botschaft (Knotenadresse) eindeutig im Fahrzeug";
CM_ SG_ 2600468585 NM_Rearview_UDS_CC "Funktionseinschränkung aufgrund aktivem UDS-Communication Control, siehe VW80124";

CM_ SG_ 2600468522 NM_SCR_CAB "CAB = Clusteraktivbits";
CM_ SG_ 2600468522 NM_SCR_Car_Wakeup "Car Wakeup (Gateway wertet aus)

MLBevo: Fehler bei Evakuierung des Systems";
CM_ SG_ 2600468522 NM_SCR_CBV_AWB "Das Signal ist zu setzen, wenn das SG aktiv den Bus geweckt hat
0 = Passiver_WakeUp = SG hat das Netzwerk nicht aktiv geweckt
1 = Akitiver_WakeUp = SG hat das Netzwerk aktiv geweckt";
CM_ SG_ 2600468522 NM_SCR_CBV_CRI "Das Signal ist dauerhaft gesetzt, wenn das NM-Layout Cluster- Anforderungen enthält";
CM_ SG_ 2600468522 NM_SCR_NM_aktiv_Diagnose "Diagnose befindet sich nach VW80124 in einer NonDefaultDiagnostic-Session, z.B. ExtendedDiagnostic-Session";
CM_ SG_ 2600468522 NM_SCR_NM_aktiv_KL15 "Steuergerät hat KL15-EIN erkannt";
CM_ SG_ 2600468522 NM_SCR_NM_aktiv_Tmin "Mindestaktivzeit ist noch nicht abgelaufen (bei jedem Weckereignis wird die Mindestaktivzeit neu gestartet)";
CM_ SG_ 2600468522 NM_SCR_NM_State "1 = Zustand Repeat Message (<-- Bus-Sleep Mode)
2 = Zustand Repeat Message (<-- Prepare Bus-Sleep Mode)
4 = Zustand Normal Operation (<-- Repeat Message)
8 = Zustand Normal Operation (<-- Ready Sleep)";
CM_ SG_ 2600468522 NM_SCR_SNI "Source Node-Identifier (SNI) identifiziert den Sender der NM-Botschaft (Knotenadresse) eindeutig im Fahrzeug";
CM_ SG_ 2600468522 NM_SCR_UDS_CC "Funktionseinschränkung aufgrund aktivem UDS-Communication Control, siehe VW80124";

CM_ SG_ 2600468586 NM_STH_CAB "CAB = Clusteraktivbits";
CM_ SG_ 2600468586 NM_STH_Car_Wakeup "Car Wakeup (Gateway wertet aus)

MQB: 
-Standheizung wurde per Funk ein oder ausgeschaltet
-Schwalltopf muß nachgefüllt werden
-Gebläse muß ein- oder ausgeschaltet werden
-neue Programmierung der Funkfernbedienung empfangen
-Standheizung abschalten";
CM_ SG_ 2600468586 NM_STH_CBV_AWB "Das Signal ist zu setzen, wenn das SG aktiv den Bus geweckt hat
0 = Passiver_WakeUp = SG hat das Netzwerk nicht aktiv geweckt
1 = Akitiver_WakeUp = SG hat das Netzwerk aktiv geweckt";
CM_ SG_ 2600468586 NM_STH_CBV_CRI "Das Signal ist dauerhaft gesetzt, wenn das NM-Layout Cluster- Anforderungen enthält";
CM_ SG_ 2600468586 NM_STH_NM_aktiv_Diagnose "Diagnose befindet sich nach VW80124 in einer NonDefaultDiagnostic-Session, z.B. ExtendedDiagnostic-Session";
CM_ SG_ 2600468586 NM_STH_NM_aktiv_EIN_AUS_Funk "Funkbefehl STH einschalten/ausschalten aktiv";
CM_ SG_ 2600468586 NM_STH_NM_aktiv_EKP_Anf "EKP-Anforderung (Schwalltopf füllen) setzen/zurücknehmen";
CM_ SG_ 2600468586 NM_STH_NM_aktiv_KL15 "Steuergerät hat KL15-EIN erkannt";
CM_ SG_ 2600468586 NM_STH_NM_aktiv_Tmin "Mindestaktivzeit ist noch nicht abgelaufen (bei jedem Weckereignis wird die Mindestaktivzeit neu gestartet)";
CM_ SG_ 2600468586 NM_STH_NM_aktiv_WaPu_Anf "Wasserpumpe-Anforderung  setzen/zurücknehmen";
CM_ SG_ 2600468586 NM_STH_NM_State "1 = Zustand Repeat Message (<-- Bus-Sleep Mode)
2 = Zustand Repeat Message (<-- Prepare Bus-Sleep Mode)
4 = Zustand Normal Operation (<-- Repeat Message)
8 = Zustand Normal Operation (<-- Ready Sleep)";
CM_ SG_ 2600468586 NM_STH_SNI "Source Node-Identifier (SNI) identifiziert den Sender der NM-Botschaft (Knotenadresse) eindeutig im Fahrzeug";
CM_ SG_ 2600468586 NM_STH_UDS_CC "Funktionseinschränkung aufgrund aktivem UDS-Communication Control, siehe VW80124";

CM_ SG_ 2600468558 NM_SWA_CAB "CAB = Clusteraktivbits";
CM_ SG_ 2600468558 NM_SWA_Car_Wakeup "Car Wakeup (Gateway wertet aus)

MQB:
ASW Kombimeldung";
CM_ SG_ 2600468558 NM_SWA_CBV_AWB "Das Signal ist zu setzen, wenn das SG aktiv den Bus geweckt hat";
CM_ SG_ 2600468558 NM_SWA_CBV_CRI "Das Signal ist dauerhaft gesetzt, wenn das NM-Layout dem neuen NM-Layout für Teilnetzbetrieb entspricht";
CM_ SG_ 2600468558 NM_SWA_NM_aktiv_ASW_aktiv "Austiegswarner aktiviert";
CM_ SG_ 2600468558 NM_SWA_NM_aktiv_Diagnose "Diagnose befindet sich nach VW80124 in einer NonDefaultDiagnostic-Session, z.B. ExtendedDiagnostic-Session";
CM_ SG_ 2600468558 NM_SWA_NM_aktiv_KL15 "Steuergerät hat KL15-EIN erkannt";
CM_ SG_ 2600468558 NM_SWA_NM_aktiv_Tmin "Mindestaktivzeit ist noch nicht abgelaufen (bei jedem Weckereignis wird die Mindestaktivzeit neu gestartet)";
CM_ SG_ 2600468558 NM_SWA_NM_State "1 = Zustand Repeat Message (<-- Bus-Sleep Mode)
2 = Zustand Repeat Message (<-- Prepare Bus-Sleep Mode)
4 = Zustand Normal Operation (<-- Repeat Message)
8 = Zustand Normal Operation (<-- Ready Sleep)
16 = Zustand Repeat Message (<-- Ready Sleep)
32 ";
CM_ SG_ 2600468558 NM_SWA_SNI "Source Node-Identifier (SNI) identifiziert den Sender der NM-Botschaft (Knotenadresse) eindeutig im Fahrzeug";
CM_ SG_ 2600468558 NM_SWA_UDS_CC "Funktionseinschränkung aufgrund aktivem UDS-Communication Control; siehe VW80124";

CM_ SG_ 2600468618 NM_SWA_Slave_CAB "CAB = Clusteraktivbits";
CM_ SG_ 2600468618 NM_SWA_Slave_Car_Wakeup "Car Wakeup (Gateway wertet aus)";
CM_ SG_ 2600468618 NM_SWA_Slave_CBV_AWB "Das Signal ist zu setzen, wenn das SG aktiv den Bus geweckt hat";
CM_ SG_ 2600468618 NM_SWA_Slave_CBV_CRI "Das Signal ist dauerhaft gesetzt, wenn das NM-Layout dem neuen NM-Layout für Teilnetzbetrieb entspricht";
CM_ SG_ 2600468618 NM_SWA_Slave_NM_aktiv_ASW_aktiv "Austiegswarner aktiviert";
CM_ SG_ 2600468618 NM_SWA_Slave_NM_aktiv_Diagnose "Diagnose befindet sich nach VW80124 in einer NonDefaultDiagnostic-Session, z.B. ExtendedDiagnostic-Session";
CM_ SG_ 2600468618 NM_SWA_Slave_NM_aktiv_KL15 "Steuergerät hat KL15-EIN erkannt";
CM_ SG_ 2600468618 NM_SWA_Slave_NM_aktiv_Tmin "Mindestaktivzeit ist noch nicht abgelaufen (bei jedem Weckereignis wird die Mindestaktivzeit neu gestartet)";
CM_ SG_ 2600468618 NM_SWA_Slave_NM_State "1 = Zustand Repeat Message (<-- Bus-Sleep Mode)
2 = Zustand Repeat Message (<-- Prepare Bus-Sleep Mode)
4 = Zustand Normal Operation (<-- Repeat Message)
8 = Zustand Normal Operation (<-- Ready Sleep)
16 = Zustand Repeat Message (<-- Ready Sleep)
32 ";
CM_ SG_ 2600468618 NM_SWA_Slave_SNI "Source Node-Identifier (SNI) identifiziert den Sender der NM-Botschaft (Knotenadresse) eindeutig im Fahrzeug";
CM_ SG_ 2600468618 NM_SWA_Slave_UDS_CC "Funktionseinschränkung aufgrund aktivem UDS-Communication Control; siehe VW80124";

CM_ SG_ 1377 NV_MessZeitpunkt "Messzeitpunkt der Objekte und der Ergebnisse anderer Wahrnehmungsmodule
Bei Nightvision: Aufnahmezeitpunkt des zugehörigen Bildes";
CM_ SG_ 1377 NV_NichtVerfuegbar "Verfuegbarkeit Nightvision";
CM_ SG_ 1377 NV_Obj_01_InvTTCBildebStdA "Standardabweichung zu NV_Obj_01_InvTTCBildeb";
CM_ SG_ 1377 NV_Obj_01_Klasse "Klasse des Objekts";
CM_ SG_ 1377 NV_Obj_Links "Objekt für Markierungslicht in Fahrtrichtung links";
CM_ SG_ 1377 NV_Obj_Rechts "Objekt für Markierungslicht in Fahrtrichtung rechts";
CM_ SG_ 1377 NV_Obj_Warnung_Fussgaenger "Warnung auf NV_Obj_01 im Fahrzeug signalisiert";
CM_ SG_ 1377 NV_Sensor_PositionX "Position der Kamera in USK-Koordinaten
x-Koordinate des Fokussierpunktes der Kamera-Optik";
CM_ SG_ 1377 NV_Sensor_PositionY "Position der Kamera in USK-Koordinaten
y-Koordinate des Fokussierpunktes der Kamera-Optik";
CM_ SG_ 1377 NV_Sensor_PositionZ "Position der Kamera in USK-Koordinaten
z-Koordinate des Fokussierpunktes der Kamera-Optik";

CM_ SG_ 597 NV_Obj_01_Gemessen "Status Objekt gemessen/getrackt

0 = Objekt nicht gemessen, nur per 3D Modell praediziert (auch BVS)
1 = Objekt wurde im aktuellen Zyklus gemessen
2 = Nur für Video: Objekt wurde nicht gemessen, sondern per Feature-Tracking wiedergefunden (Optischer F";
CM_ SG_ 597 NV_Obj_01_ID "ID des Objektes";
CM_ SG_ 597 NV_Obj_01_InvTTCBildeb "Kehrwert der Time-to-collision mit der Bildebene";
CM_ SG_ 597 NV_Obj_01_RadialDistanz "Radiale Distanz des Zielobjektes zum messenden Sensor
Koordinatensystem: verschobenes USK mit Ursprung im messenden Sensor";
CM_ SG_ 597 NV_Obj_01_RadialDistanzStdA "Standardabweichung zu NV_Obj_01_RadialDistanz";
CM_ SG_ 597 NV_Obj_01_WnklBreite "Horizontale Breite des Objektes

Wertebereich in Grad: 
0 bis 27,8
Auflösung in Grad: 0,45

Koordinatensystem: korrigiertes Kamerakoordinatensystem (kKKS): verschobenes USK mit Ursprung in der Kamera. Beachte NV_Sensor_Position_X,Y,Z ";
CM_ SG_ 597 NV_Obj_01_WnklBreiteStdA "Standardabweichung zur horizontalen Breite des Objektes

Wertebereich in Grad: 
0 bis 5
Auflösung in Grad: 0,9

Koordinatensystem: korrigiertes Kamerakoordinatensystem (kKKS): verschobenes USK mit Ursprung in der Kamera. Beachte NV_Sensor_Position_X";
CM_ SG_ 597 NV_Obj_01_WnklHoehe "Hoehe des Objektes

Wertebereich in Grad: 
0 bis 25
Auflösung in Grad: 1,79

Koordinatensystem: korrigiertes Kamerakoordinatensystem (kKKS): verschobenes USK mit Ursprung in der Kamera. Beachte NV_Sensor_Position_X,Y,Z ";
CM_ SG_ 597 NV_Obj_01_WnklHorMitte "Horizontaler Mittelpunkt des Objektes

Wertebereich in Grad: 
-13,9 bis 13,9
Auflösung in Grad: 0,45

Koordinatensystem: korrigiertes Kamerakoordinatensystem (kKKS): verschobenes USK mit Ursprung in der Kamera. Beachte NV_Sensor_Position_X,Y,Z ";
CM_ SG_ 597 NV_Obj_01_WnklHorMitteStdA "Standardabweichung zum horizontalen Mittelpunkt des Objektes

Wertebereich in Grad: 
0 bis 5
Auflösung in Grad: 0,9

Koordinatensystem: korrigiertes Kamerakoordinatensystem (kKKS): verschobenes USK mit Ursprung in der Kamera. Beachte NV_Sensor_Posit";
CM_ SG_ 597 NV_Obj_01_WnklVertMitte "Vertikaler Mittelpunkt des Objektes

Wertebereich in Grad: 
-12,5 bis 12,5
Auflösung in Grad: 1,79

Koordinatensystem: korrigiertes Kamerakoordinatensystem (kKKS): verschobenes USK mit Ursprung in der Kamera. Beachte NV_Sensor_Position_X,Y,Z  ";

CM_ SG_ 598 NV_Obj_02_Gemessen "Status Objekt gemessen/getrackt

0 = Objekt nicht gemessen, nur per 3D Modell praediziert (auch BVS)
1 = Objekt wurde im aktuellen Zyklus gemessen
2 = Nur für Video: Objekt wurde nicht gemessen, sondern per Feature-Tracking wiedergefunden (Optischer F";
CM_ SG_ 598 NV_Obj_02_ID "ID des Objektes";
CM_ SG_ 598 NV_Obj_02_Klasse "Klasse des Objekts";
CM_ SG_ 598 NV_Obj_02_RadialDistanzRed "Radiale Distanz des Zielobjektes 

Koordinatensystem: korrigiertes Kamerakoordinatensystem (kKKS): verschobenes USK mit Ursprung in der Kamera. Beachte NV_Sensor_Position_X,Y,Z";
CM_ SG_ 598 NV_Obj_02_RadialDistanzRedStdA "Standardabweichung zur radialen Distanz des Zielobjektes 

Koordinatensystem: korrigiertes Kamerakoordinatensystem (kKKS): verschobenes USK mit Ursprung in der Kamera. Beachte NV_Sensor_Position_X,Y,Z ";
CM_ SG_ 598 NV_Obj_02_WnklBreite "Horizontale Breite des Objektes

Wertebereich in Grad: 
0 bis 27,8
Auflösung in Grad: 0,45

Koordinatensystem: korrigiertes Kamerakoordinatensystem (kKKS): verschobenes USK mit Ursprung in der Kamera. Beachte NV_Sensor_Position_X,Y,Z ";
CM_ SG_ 598 NV_Obj_02_WnklHoehe "Hoehe des Objektes

Wertebereich in Grad: 
0 bis 25
Auflösung in Grad: 1,79

Koordinatensystem: korrigiertes Kamerakoordinatensystem (kKKS): verschobenes USK mit Ursprung in der Kamera. Beachte NV_Sensor_Position_X,Y,Z ";
CM_ SG_ 598 NV_Obj_02_WnklHorMitte "Horizontaler Mittelpunkt des Objektes

Wertebereich in Grad: 
-13,9 bis 13,9
Auflösung in Grad: 0,45

Koordinatensystem: korrigiertes Kamerakoordinatensystem (kKKS): verschobenes USK mit Ursprung in der Kamera. Beachte NV_Sensor_Position_X,Y,Z ";
CM_ SG_ 598 NV_Obj_02_WnklVertMitte "Vertikaler Mittelpunkt des Objektes

Wertebereich in Grad: 
-12,5 bis 12,5
Auflösung in Grad: 1,79

Koordinatensystem: korrigiertes Kamerakoordinatensystem (kKKS): verschobenes USK mit Ursprung in der Kamera. Beachte NV_Sensor_Position_X,Y,Z  ";
CM_ SG_ 598 NV_Obj_03_RadialDistanzRed "Radiale Distanz des Zielobjektes 

Koordinatensystem: korrigiertes Kamerakoordinatensystem (kKKS): verschobenes USK mit Ursprung in der Kamera. Beachte NV_Sensor_Position_X,Y,Z";
CM_ SG_ 598 NV_Obj_03_RadialDistanzRedStdA "Standardabweichung zur radialen Distanz des Zielobjektes 

Koordinatensystem: korrigiertes Kamerakoordinatensystem (kKKS): verschobenes USK mit Ursprung in der Kamera. Beachte NV_Sensor_Position_X,Y,Z ";
CM_ SG_ 598 NV_Obj_03_WnklHoehe "Hoehe des Objektes

Wertebereich in Grad: 
0 bis 25
Auflösung in Grad: 1,79

Koordinatensystem: korrigiertes Kamerakoordinatensystem (kKKS): verschobenes USK mit Ursprung in der Kamera. Beachte NV_Sensor_Position_X,Y,Z ";
CM_ SG_ 598 NV_Obj_03_WnklVertMitte "Vertikaler Mittelpunkt des Objektes

Wertebereich in Grad: 
-12,5 bis 12,5
Auflösung in Grad: 1,79

Koordinatensystem: korrigiertes Kamerakoordinatensystem (kKKS): verschobenes USK mit Ursprung in der Kamera. Beachte NV_Sensor_Position_X,Y,Z  ";

CM_ SG_ 601 NV_Obj_03_Gemessen "Status Objekt gemessen/getrackt

0 = Objekt nicht gemessen, nur per 3D Modell praediziert (auch BVS)
1 = Objekt wurde im aktuellen Zyklus gemessen
2 = Nur für Video: Objekt wurde nicht gemessen, sondern per Feature-Tracking wiedergefunden (Optischer F";
CM_ SG_ 601 NV_Obj_03_ID "ID des Objektes";
CM_ SG_ 601 NV_Obj_03_Klasse "Klasse des Objekts";
CM_ SG_ 601 NV_Obj_03_WnklBreite "Horizontale Breite des Objektes

Wertebereich in Grad: 
0 bis 27,8
Auflösung in Grad: 0,45

Koordinatensystem: korrigiertes Kamerakoordinatensystem (kKKS): verschobenes USK mit Ursprung in der Kamera. Beachte NV_Sensor_Position_X,Y,Z ";
CM_ SG_ 601 NV_Obj_03_WnklHorMitte "Horizontaler Mittelpunkt des Objektes

Wertebereich in Grad: 
-13,9 bis 13,9
Auflösung in Grad: 0,45

Koordinatensystem: korrigiertes Kamerakoordinatensystem (kKKS): verschobenes USK mit Ursprung in der Kamera. Beachte NV_Sensor_Position_X,Y,Z ";
CM_ SG_ 601 NV_Obj_04_Gemessen "Status Objekt gemessen/getrackt

0 = Objekt nicht gemessen, nur per 3D Modell praediziert (auch BVS)
1 = Objekt wurde im aktuellen Zyklus gemessen
2 = Nur für Video: Objekt wurde nicht gemessen, sondern per Feature-Tracking wiedergefunden (Optischer F";
CM_ SG_ 601 NV_Obj_04_ID "ID des Objektes";
CM_ SG_ 601 NV_Obj_04_Klasse "Klasse des Objekts";
CM_ SG_ 601 NV_Obj_04_RadialDistanzRed "Radiale Distanz des Zielobjektes 

Koordinatensystem: korrigiertes Kamerakoordinatensystem (kKKS): verschobenes USK mit Ursprung in der Kamera. Beachte NV_Sensor_Position_X,Y,Z";
CM_ SG_ 601 NV_Obj_04_RadialDistanzRedStdA "Standardabweichung zur radialen Distanz des Zielobjektes 

Koordinatensystem: korrigiertes Kamerakoordinatensystem (kKKS): verschobenes USK mit Ursprung in der Kamera. Beachte NV_Sensor_Position_X,Y,Z ";
CM_ SG_ 601 NV_Obj_04_WnklBreite "Horizontale Breite des Objektes

Wertebereich in Grad: 
0 bis 27,8
Auflösung in Grad: 0,45

Koordinatensystem: korrigiertes Kamerakoordinatensystem (kKKS): verschobenes USK mit Ursprung in der Kamera. Beachte NV_Sensor_Position_X,Y,Z ";
CM_ SG_ 601 NV_Obj_04_WnklHoehe "Hoehe des Objektes

Wertebereich in Grad: 
0 bis 25
Auflösung in Grad: 1,79

Koordinatensystem: korrigiertes Kamerakoordinatensystem (kKKS): verschobenes USK mit Ursprung in der Kamera. Beachte NV_Sensor_Position_X,Y,Z ";
CM_ SG_ 601 NV_Obj_04_WnklHorMitte "Horizontaler Mittelpunkt des Objektes

Wertebereich in Grad: 
-13,9 bis 13,9
Auflösung in Grad: 0,45

Koordinatensystem: korrigiertes Kamerakoordinatensystem (kKKS): verschobenes USK mit Ursprung in der Kamera. Beachte NV_Sensor_Position_X,Y,Z ";
CM_ SG_ 601 NV_Obj_04_WnklVertMitte "Vertikaler Mittelpunkt des Objektes

Wertebereich in Grad: 
-12,5 bis 12,5
Auflösung in Grad: 1,79

Koordinatensystem: korrigiertes Kamerakoordinatensystem (kKKS): verschobenes USK mit Ursprung in der Kamera. Beachte NV_Sensor_Position_X,Y,Z  ";

CM_ SG_ 1635 BEM_02_Abschaltstufen "Abschaltstufen des Ruhestrommanagements (Initialisierungswert aus EEprom)

Stufe 0 (keine Einschraenkungen)
Stufe 1 (Abschaltung Hochstromverbraucher)
Stufe 2 (Infotainmentabschaltung)
Stufe 3 (Wake-Up-Sperre)

Für den Transport- und Ruhestrommessm";
CM_ SG_ 1635 BEM_Anf_KL15_schalten "Abschaltempfehlung bzw. Verhinderung der automatischen Abschaltung Kl15 durch das BCM";
CM_ SG_ 1635 BEM_Batteriediagnose "Anzeige von Textwarnungen";
CM_ SG_ 1635 BEM_Generatordiagnose "Ansteuerung Generatorwarnleuchte im Kombi
";
CM_ SG_ 1635 BEM_HL_Regelung_Status "Status Regelung Heizleistung
";
CM_ SG_ 1635 BEM_Ladezustand "Ladezustand der Niedervoltbatterie
";
CM_ SG_ 1635 BEM_MMI_Vorwarnung "Anzeige Vorwarnung MMI-Abschaltung (Initialisierungswert aus EEprom)
";
CM_ SG_ 1635 BEM_Red_Innengeblaese "Reduzierung Innengebläse
";
CM_ SG_ 1635 BEM_REK_aktiv "Rekuperationsfreigabe vom Energiemanagement
0x0 = keine Rekuperationsfreigabe
0x1 = Rekuperationsfreigabe";
CM_ SG_ 1635 BEM_STH_Einschaltverbot "Einschränkung Standheizung/-lüftung durch BEM: Setzt der BEM das Bit, dann darf die Standheizung nicht mehr einschalten
(Die Standheizung muss aber nicht abschalten, sondern darf weiterbrennen)
(Initialisierungswert aus EEprom)
";
CM_ SG_ 1635 BEM_STH_Zielzeit "Maximal mögliche Zeit für den Standheizungsbetrieb, um die Startfähigkeit nicht zu gefährden";
CM_ SG_ 1635 BEM_UBDM "Batteriespannung, gemessen vom Batteriedatenmodul";
CM_ SG_ 1635 BEM_UGenSoll "Sollspannungsvorgabe an den Generator, beinhaltet temperaturoptimierte Batterieladung und Rekuperation";
CM_ SG_ 1635 MIB_Stromsparmodus "Signal beschreibt die Aktivierung für den Stromsparmodus beim MIB.
Bei AUS (= 0) gibt es keine weitere Anforderung an die MIB-Komponenten.
Bei EIN (= 1) werden alle MIB Komponenten in einen Stromsparmodus versetzt.";
CM_ SG_ 1635 NVEM_Anf_SD_schalten "Anforderung Nachlauf für den Steckdosenbetrieb
Initialisierungswert aus EEprom";
CM_ SG_ 1635 NVEM_Batterie_Service "Anforderung einer Batterie-Service - Anzeige / Anforderung an die Werkstatt über MOD";
CM_ SG_ 1635 NVEM_Freigabe_OnlineUpdate "Freigabe für Online-Update durch Energiemanagement";
CM_ SG_ 1635 NVEM_Freigabe_ORU4 "Bestätigung oder Ablehnung eines konkreten, angefragten Online Updates durch das Energiemanagements";
CM_ SG_ 1635 NVEM_Last_Anf "Das NVEM fordert für die Batteriediagnose einen Lastimpuls vom Fahrzeug an, der durch kontrollierte Verbraucherzuschaltungen (z. B. Aktivierung Heckscheibenheizung) generiert wird";

CM_ SG_ 913 MO_QBit_Aussen_Temp "QBit der Aussentemperatur. Gesetzt bei Ersatzwert, Init oder Fehler.";
CM_ SG_ 913 MO_Servicemodus "Ausgabe aktiver Service-Mode";
CM_ SG_ 913 OBD_Abs_Load_Val "Absolute Load Value

Übertragung von Meßgrößen an das Getriebesteuergerät für Freeze Frame Abspeicherung bei Getriebefehlern

PID $43 Absolute Load Value; 0 .. 25700%  mit 100/255 %/bit";
CM_ SG_ 913 OBD_Abs_Pedal_Pos "Absolute Pedal Position

Übertragung von Meßgrößen an das Getriebesteuergerät für Freeze Frame Abspeicherung bei Getriebefehlern

PID $49 Accelerator Pedal Position D; 0 .. 100% mit 100/255 %/bit";
CM_ SG_ 913 OBD_Abs_Throttle_Pos "Absolute Throttle Position

Übertragung von Meßgrößen an das Getriebesteuergerät für Freeze Frame Abspeicherung bei Getriebefehlern

PID $11 Absolute Throttle Position; 0 .. 100% mit 100/255 %/bit";
CM_ SG_ 913 OBD_Calc_Load_Val "Calculated Load Value

Übertragung von Meßgrößen an das Getriebesteuergerät für Freeze Frame Abspeicherung bei Getriebefehlern

PID $04 Calculated Load Value; 0 .. 100% mit 100/255 % per bit
";
CM_ SG_ 913 OBD_ClearMem_Inhibit "Bei FSP_Loeschen_zulässig müssen alle OBD-ECUs im Gesamtfahrzeug einen Service 04hex Request (Ereignisspeicher löschen) korrekt ausführen. 

In MLB-, MLBevo-, MQB-Fahrzeugkonzepten muss der MIL-Master/Motorsteuergerät bei Kl.15 ein, projektabhängig, kon";
CM_ SG_ 913 OBD_Driving_Cycle "Signalisierung Driving Cycle Qualifizierung - Trigger Ignition Cycle Counter";
CM_ SG_ 913 OBD_Eng_Cool_Temp "Engine Coolant Temperature

Übertragung von Meßgrößen an das Getriebesteuergerät für Freeze Frame Abspeicherung bei Getriebefehlern

PID $05 Engine Coolant Temperature; -40 .. +215°C mit 1°C/bit und 40°C Offset";
CM_ SG_ 913 OBD_Kaltstart_Denominator "Bestimmte Diagnosen werden nur unter Kaltstartbedingungen durchgeführt, der entsprechende Denominator bei IUMPR-pflichtigen Systemen wird anhand dieses vom MSG gebildeten Signals inkrementiert. (Entspricht EVAP-Denominator)";
CM_ SG_ 913 OBD_Minimum_Trip "Grundlage OBD-Gesetz CCR 1968.2 (d)(4.3) Denominator Specifications
Bildung des General Denominator 'Normed Trip':
 600 sec. (kumulativ) Zeit nach Motorstart
 300 sec. (kumulativ) mit Fahrzeuggeschwindigkeit > 25 mph (40 km/h)
 30 sec. (kontinuierlich";
CM_ SG_ 913 OBD_Normed_Trip "Gesetzlich definierte 'Normed Condition' erfüllt, 'General Denominator' darf erhöht werden";
CM_ SG_ 913 OBD_Sperrung_IUMPR "Wenn der General Denominator auf Grund eines Fehlers in den Eingangsgrößen gesperrt wird, wird diese Information über Bussystem als OBD-Statusinformation OBD_Sperrung_IUMPR für andere OBD-Steuergeräte bereitgestellt. 

Das MSG (MIL-Master) setzt dieses ";
CM_ SG_ 913 OBD_Sperrung_Kaltstart_Denom "Information vom MIL Master, dass die Bildung des EVAP Denominators  im Motor nicht möglich ist und damit der noECM-Denominator gesperrt werden darf.";
CM_ SG_ 913 OBD_Warm_Up_Cycle "Mit dem Warm-Up-Cycle wird der zentrale Verlernzähler vom Gateway inkrementiert";

CM_ SG_ 2589283478 OBD_Aussen_Temp_gef "Gefilterte Aussentemperatur vom Motor für OBD Funktionen.";

CM_ SG_ 2549940736 OBDC_Funktionaler_Req_All_Data "VDC funktionaler Request auf CANHS";

CM_ SG_ 2589283656 ORU_Status "Verteilung des internen ORU Zustandes";
CM_ SG_ 2589283656 ORU_Warnung "Wenn durch Störungen der Funktion Online Remote Update nicht sichergestellt ist, dass vor Kunde keine Funktionseinschränkungen auftreten, muss der Benutzer des Fahrzeugs entsprechend gewarnt werden.";

CM_ SG_ 1175 PDC_Tonausgabe_Front "In Abhängigkeit der Systemaktivitäten werden unterschiedliche Tonwarnungen ausgegeben. 
Kombi spielt entsprechende WAV.-Datei über internen Audiomaster ab.

0 = kein Ton
1 = Intervallton 1
2 = Intervallton 2
3 = Intervallton 3
4 = Intervallton 4
5";
CM_ SG_ 1175 PDC_Tonausgabe_Heck "In Abhängigkeit der Systemaktivitäten werden unterschiedliche Tonwarnungen ausgegeben. 
Kombi spielt entsprechende WAV.-Datei über internen Audiomaster ab.

0 = kein Ton
1 = Intervallton 1
2 = Intervallton 2
3 = Intervallton 3
4 = Intervallton 4
5";
CM_ SG_ 1175 PH_Abschaltursache "Abschaltursache bleibt bis zur nächsten Aktivierung bzw. bis KL15 aus gesetzt
Im Fehlerfall (blinkende LED) wird '7' gesendet obwohl das System noch aktiv ist, bei 'geheiltem' Fehler wird sofort wieder der Zustand '0' gesendet";
CM_ SG_ 1175 PH_Anf_Audioabsenkung "Es gibt zwei unterschiedliche Nachlauftimer für dieses Bit:
1. normale Funktion
2. Demotonausgabe";
CM_ SG_ 1175 PH_Anf_Verdeck "Anforderung an ein Verdeck-System, die vom Fahrer angeforderte Öffnung/Schließung zu verhindern";
CM_ SG_ 1175 PH_defekt "Zeigt an das sich die Parkhilfe im Fehlerzustand befindet. Signal bleibt bis zur nächsten 'Gut-Aktivierung' gesetzt.
Spezialfall: Sensordefekt hinten bei Anhängerbetrieb. Anhänger wird abgesteckt Fehler wird gesetzt. Fehlerfall bleibt bis Behebung des De";
CM_ SG_ 1175 PH_Display_Kundenwunsch "Anzeige der bei Aktivierung verwendeten Parameter bzgl. Kundenwunsch Displayanziege. Änderungen werden erst bei erneuter Aktivierung aktualisiert.";
CM_ SG_ 1175 PH_Frequenz_hinten "Uebertragung der aktuell im APS Steuergeraet gespeicherten Werte fuer Tongeber Frequenz hinten
Anzeige der aktuell verwendeten Parameter (nicht zwingend die abgespeicherten - da Werte erst 2s nach der letzten Änderung gespeichert werden!)";
CM_ SG_ 1175 PH_Frequenz_vorn "Uebertragung der aktuell im APS Steuergeraet gespeicherten Werte fuer Tongeber Frequenz vorne
Anzeige der aktuell verwendeten Parameter (nicht zwingend die abgespeicherten - da Werte erst 2s nach der letzten Änderung gespeichert werden!)";
CM_ SG_ 1175 PH_gestoert "Eine Störung ist aufgetreten, der die Parkhilfe in einen 'gestört-Zustand' versetzt, z.B. massiver Fremdultraschall, Vereisung, Schnee.Derzeit nur für Störschall benutzt, da keinerlei andere Erkennung implementiert.";
CM_ SG_ 1175 PH_Lautstaerke_hinten "Uebertragung der aktuell im APS Steuergeraet gespeicherten Werte fuer Tongeber Lautstaerke hinten
Anzeige der aktuell verwendeten Parameter (nicht zwingend die abgespeicherten - da Werte erst 2s nach der letzten Änderung gespeichert werden!)";
CM_ SG_ 1175 PH_Lautstaerke_vorn "Uebertragung der aktuell im APS Steuergeraet gespeicherten Werte fuer Tongeber Lautstaerke vorn.
Anzeige der aktuell verwendeten Parameter (nicht zwingend die abgespeicherten - da Werte erst 2s nach der letzten Änderung gespeichert werden!)";
CM_ SG_ 1175 PH_nachtr_Stopp_Anf "Dieses Signal dient dem Motor als Trigger, dass ein nachträglicher Motorstopp eingeleitet werden kann, wenn es die Bedingungen des StSt Koordinators dies zulassen. ";
CM_ SG_ 1175 PH_Opt_Anz_H_Hindernis "mindestens 1 Segment wird für den hinteren Detekionsbereich dargestellt, also ein Hindernis ist im Detektionsbereich. Funktion nur bei gesicherter Rückmeldung vom ASG gegeben.";
CM_ SG_ 1175 PH_Opt_Anz_V_Hindernis "mindestens 1 Segment wird für den vorderen Detekionsbereich dargestellt, also ein Hindernis ist im Detektionsbereich. Funktion nur bei gesicherter Rückmeldung vom ASG gegeben.";
CM_ SG_ 1175 PH_Opt_Anzeige_H_ein "OPS hinten ist im Display aktiv bzw. Anzeigemodule hinten sind eingeschaltet. Funktion nur bei gesicherter Rückmeldung vom ASG gegeben.";
CM_ SG_ 1175 PH_Opt_Anzeige_V_ein "OPS vorne ist im Display aktiv bzw. Anzeigemodule vorne sind eingeschaltet. Funktion nur bei gesicherter Rückmeldung vom ASG gegeben.";
CM_ SG_ 1175 PH_StartStopp_Info "Stopp-Freigabe und Start-Anforderung an den Start-Stopp-Koordinator";
CM_ SG_ 1175 PH_Stoermeldung "Meldung einer Störung der PDC an das Kombi";
CM_ SG_ 1175 PH_Systemzustand "Aktivierungsursache wird für die Dauer der Aktivierung gemeldet.
Im Fehlerfall bei atkviem System wechselt das Signal auf '7'
(siehe auch 'Abschaltursache')";
CM_ SG_ 1175 PH_Taster "Taster Status (für RVC/TopView)";
CM_ SG_ 1175 PH_Tongeber_H_aktiv "Rohsignal für 'Tongeber hinten wird angesteuert', verlängerbar mit Nachlauftimer.
Bit wird nicht während des Stellgliedtests angesteuert.";
CM_ SG_ 1175 PH_Tongeber_H_verfuegbar "Tongeber ist für die Tonausgabe für externe Funktionen verfügbar. PDC ist aktiv und Tongeber ist nicht gestört.";
CM_ SG_ 1175 PH_Tongeber_mute "Die Akustikausgabe des Systems wird unterdrückt, z.B. Wählhebel in 'P', Parlbremse geschlossen (8-Kanal-System)";
CM_ SG_ 1175 PH_Tongeber_V_aktiv "Rohsignal für 'Tongeber vorne wird angesteuert', verlängerbar mit Nachlauftimer.
Bit wird nicht während des Stellgliedtests angesteuert.";
CM_ SG_ 1175 PH_Visualisierung "Signal zeigt den Partnersteuergeräten RearView/TopView/ARA/... den aktuellen Status der Visualisierung des OPS. Die Partnersteuergeräte können dadurch auch ihre Aufschaltung an dieses Signal koppeln.";
CM_ SG_ 1175 PLA_Anf_Aufschaltung_RVC "Anforderung der Aufschaltung RVC durch PLA";

CM_ SG_ 1353 PL_Luecke_P0_x "x-Koordinate des Punktes P0
";
CM_ SG_ 1353 PL_Luecke_P0_y "y-Koordinate des Punktes P0";
CM_ SG_ 1353 PL_Luecke_P2_x "x-Koordinate des Punktes P2";
CM_ SG_ 1353 PL_Luecke_P2_y "y-Koordinate des Punktes P2";

CM_ SG_ 1354 PL_Luecke_P1_x "x-Koordinate des Punktes P1";
CM_ SG_ 1354 PL_Luecke_P1_y "y-Koordinate des Punktes P1";
CM_ SG_ 1354 PL_Luecke_P3_x "x-Koordinate des Punktes P3";
CM_ SG_ 1354 PL_Luecke_P3_y "y-Koordinate des Punktes P3";

CM_ SG_ 1355 BCM_WAH_Meldung "Steuert die HMI-Meldungen im Kombi für den Wiederanfahrhinweis";
CM_ SG_ 1355 PDC_Charisma_FahrPr "Istwert der Kennline (siehe System-LAH MQB FPA)";
CM_ SG_ 1355 PDC_Charisma_Status "Charisma Systemstatus des Charisma-Teilnehmers";
CM_ SG_ 1355 PH_Aufschaltursache "Der Grund für die Aufschaltung der Einparkhilfe wird angegeben, z.B. bei der Aktivierung der Einparkhilfe durch eine andere Funktion, wird diese Funktion als Aktivierungsursache für die Dauer der Aktivierung gemeldet.
Das Signal wird den PH_Systemzustand";
CM_ SG_ 1355 PH_Ton_Ausgabe "Anforderung einer Tonausgabe beim MIB3 durch die Parkhilfe";
CM_ SG_ 1355 PH_Ton_Lautstaerke "Wunschlautstärke der Tonanforderung beim MIB3 durch die Parkhilfe.";
CM_ SG_ 1355 PH_Ton_Pausenlaenge "Pause zwischen den angeforderten Tönen beim MIB3 durch die Parkhilfe. Nur für Intervalltöne, nicht relevant für Dauerton und Quittierungston.";
CM_ SG_ 1355 PH_Ton_Richtung "Abspielrichtung des angeforderten Ton beim MIB3 durch die Parkhilfe";
CM_ SG_ 1355 PH_Verschmutzungsmeldung "Meldung einer Verschmutzung/Vereisung der PDC an das Kombi";

CM_ SG_ 2527679498 IAA_Active_User_ID "Signal gibt die IAA Nutzer ID des aktiven IAA Nutzers an.";
CM_ SG_ 2527679498 IAA_Identified_User_ID "Signal gibt die IAA Nutzer ID des vom BCM identifizierten IAA Nutzers an";
CM_ SG_ 2527679498 IAA_PSO_wake_up "Signal zum Wake_up der IAA und PSO Komponenten im Kombi und in der OCU";
CM_ SG_ 2527679498 Perso_Aktiv "Status Personalisierung für den Fahrer aktiviert/ deaktiviert (via HMI)";
CM_ SG_ 2527679498 Perso_Bedienstelle "Signal zeigt an, über welche Bedienstelle die Umschaltung des Benutzerkontos gestartet wurden.";
CM_ SG_ 2527679498 Perso_Fahrernummer "Signal gibt die jewels aktuelle Nummer des Fahrers für die Personalisierung an.
Nicht für AU736 und AU48x.";
CM_ SG_ 2527679498 Perso_Freigabe_Verstellung "Signal zeigt an, ob die Ergonomiefunktionen nach Umschaltung des Benutzerkontos verfahren dürfen.";
CM_ SG_ 2527679498 Perso_Kontonummer "Signal gibt die jewels aktuelle Kontonummer für die Personalisierung an.
Nicht für AU736 und AU48x.";
CM_ SG_ 2527679498 Perso_Schreibschutz "Signal zeigt an, ob der Schreibschutz der Personalisierung aktiv ist.";
CM_ SG_ 2527679498 Perso_Status "Codierstatus der Personalisierung
Nicht für AU736 und AU49x.";
CM_ SG_ 2527679498 Perso_Steuerung "Signal gibt einen Steuerungsbefehl an die Funktionsteilnehmer der Personalisierung.
Nicht für AU736 und AU49x.";
CM_ SG_ 2527679498 Perso_Steuerungsparameter "Signal gibt einen Parameter zum Steuerungsbefehl (Signal Perso_Steuerung) für die Personalisierung an.
Nicht für AU736 und AU49x.";

CM_ SG_ 319 PreCrash_02_BZ "Botschaftszaehler
Botschaft asynchron geroutet. Zählerwert kann springen.";
CM_ SG_ 319 PreCrash_02_CRC "Ab MQB und MLBevo:
'Berechnung siehe Lastenheft 'End-to-End Kommunikationsabsicherung''

Endwerte siehe Begleitdokument 'S-PDU Kennungsfolgen'";
CM_ SG_ 319 PreCrash_Anforderung_AFR "Anforderungen der Funktion PrecrashSeite an Fahrwerksregelung";
CM_ SG_ 319 PreCrash_BFS_KSV_verfahren "Ansteuerung der Kopfstuetze Beifahrerseite durch die Funktion PreCrash

Signalwert 0x09 für vereinfachte Ansteuerung mit Logik im Sitz-SG (MQB37W)";
CM_ SG_ 319 PreCrash_BFS_Pneumatik_ansteuern "Ansteuerung des Beifahrersitzes durch die PreCrash-Funktionen";
CM_ SG_ 319 PreCrash_BFS_Sitzlehne_verfahren "Ansteuerung des Beifahrersitzes durch die PreCrash-Funktionen

Wert 0x06 und 0x07 für vereinfachte Ansteuerung Sitzlehne";
CM_ SG_ 319 PreCrash_Blinken "Safety Computer übermittelt Blinkverhalten bei einer PreCrash-Auslösung an den BCM2";
CM_ SG_ 319 PreCrash_Charisma_FahrPr "Aktuell eingestelltes Fahrprogramm der Funktion PreCrash";
CM_ SG_ 319 PreCrash_Charisma_Status "Verfügbarkeit der Funktion PreCrash für die Ansteuerung durch den Charisma_Koordinator";
CM_ SG_ 319 PreCrash_Fenster_schliessen "Anforderung Seitenscheiben schließen durch die Funktion PreCrash";
CM_ SG_ 319 PreCrash_Fo_KSV_verfahren "Ansteuerung der Kopfstuetzen im Fond durch die PreCrash-Funktionen";
CM_ SG_ 319 PreCrash_Fo_Pneumatik_ansteuern "Ansteuerung der Fondsitze durch die PreCrash-Funktionen";
CM_ SG_ 319 PreCrash_Fo_Sitzlehne_verfahren "Ansteuerung des Fondsitzes durch die PreCrash-Funktionen";
CM_ SG_ 319 PreCrash_FS_KSV_verfahren "Ansteuerung der Kopfstuetze Fahrerseite durch die PreCrash-Funktionen

Signalwert 0x09 für vereinfachte Ansteuerung mit Logik im Sitz-SG (MQB37W)";
CM_ SG_ 319 PreCrash_FS_Pneumatik_ansteuern "Ansteuerung des Fahrersitzes durch die PreCrash-Funktionen";
CM_ SG_ 319 PreCrash_FS_Sitzlehne_verfahren "Ansteuerung des Fahrersitzes durch die PreCrash-Funktionen

Wert 0x06 und 0x07 für vereinfachte Ansteuerung Sitzlehne";
CM_ SG_ 319 PreCrash_Schiebedach_schliessen "Anforderung Schiebedach schließen durch die Funktion PreCrash";
CM_ SG_ 319 PreCrash_Tueren_Verriegeln "Anforderung Türen Verriegeln durch die Funktion PreCrash";
CM_ SG_ 319 SC_PreCrash_LED "Ansteuerung LED-Leiste im Kombi durch SC";
CM_ SG_ 319 SC_PreCrash_Texte "Safety Computer übermittelt Systemstatus der PreCrash Funktionen an Kombi";
CM_ SG_ 319 SC_PreCrash_Warnung "Safety Computer übermittelt Warnung der PreCrash Funktionen an Kombi";
CM_ SG_ 319 SC_PreSense_FCWP "Mitteilung an das NightVision, auf welche Art von Objekt eine Warnung angefordert wird";

CM_ SG_ 1122 PSD_Abzweigerichtung "Richtung, in der die Abzweigung von der Hauptroute abzweigt
";
CM_ SG_ 1122 PSD_Abzweigewinkel "Winkel, unter dem die Abzweigung von der Hauptroute abzweigt.
";
CM_ SG_ 1122 PSD_ADAS_Qualitaet "ADAS Qualtität des Streckensegments.";
CM_ SG_ 1122 PSD_Anfangskruemmung "Startkrümmung der Klothoide des übermittelten abzweigenden Streckensegments. 
1/(1+0.155 * x^2) {1/m}'
";
CM_ SG_ 1122 PSD_Anfangskruemmung_Vorz "Vorzeichen für die Startkrümmung bei Abzweigungen
";
CM_ SG_ 1122 PSD_Bebauung "Segement befindet sich innerhalb bebauten Gebietes";
CM_ SG_ 1122 PSD_Endkruemmung "'Endkrümmung der Klotoide des übermittelten Streckensegments. Die Anfangskrümmung des folgenden Streckensegments entspricht der Endkrümmung dieses Segments. Krümmung = 1/(1+0.155 * x²) [1/m]

";
CM_ SG_ 1122 PSD_Fahrspuren_Anzahl "Anzahl der Fahrspuren in Fahrtrichtung
";
CM_ SG_ 1122 PSD_Geradester_Pfad "Segment ist Teil des geradesten Pfades";
CM_ SG_ 1122 PSD_Idenditaets_ID "Identifier auf ein Streckensegment, dass mit dem aktuell übertragenen geometrisch identisch ist.";
CM_ SG_ 1122 PSD_Segment_ID "Identifier des prädiktiven Streckensegments
";
CM_ SG_ 1122 PSD_Segment_Komplett "Zeigt, ob alle Attribute für das Segment übertragen worden sind
";
CM_ SG_ 1122 PSD_Segmentlaenge "Gesamtlänge des prädiktiven Streckensegments";
CM_ SG_ 1122 PSD_Strassenkategorie "Klassifizierung der Straße des beschriebenen Segments
";
CM_ SG_ 1122 PSD_Vorgaenger_Segment_ID "An dem Streckensegment mit diesem Identifier schließt sich das neue Segment mit der ID 'PSD_01_Segment_ID' an.
";
CM_ SG_ 1122 PSD_wahrscheinlichster_Pfad "Identifiziert den vom Navigationssystem berechneten wahrscheinlichsten Pfad des Fahrzeuges. ";

CM_ SG_ 1123 PSD_Attribut_1_ID "Identifier des ersten Attributes";
CM_ SG_ 1123 PSD_Attribut_1_Offset "Positionsoffset im Segment für die Position des Attributs";
CM_ SG_ 1123 PSD_Attribut_1_Wert "Wert des ersten Attributes";
CM_ SG_ 1123 PSD_Attribut_2_ID "Identifier des zweiten Attributes";
CM_ SG_ 1123 PSD_Attribut_2_Offset "Positionsoffset im Segment für die Position des Attributs";
CM_ SG_ 1123 PSD_Attribut_2_Wert "Wert des zweiten Attributes";
CM_ SG_ 1123 PSD_Attribut_Segment_ID_05 "Identifier des Streckensegments, für das die weiteren Attribute in der Botschaft gültig sind";
CM_ SG_ 1123 PSD_Attribute_Komplett_05 "Zeigt, ob alle Attribute für das Segment übertragen worden sind";
CM_ SG_ 1123 PSD_Pos_Fahrspur "Spur, auf der sich das Fahrzeug aktuell befindet";
CM_ SG_ 1123 PSD_Pos_Fehler_Laengsrichtung "Laengsfehler der Positionierung";
CM_ SG_ 1123 PSD_Pos_Inhibitzeit "Zeitspanne zwischen Generierung der PSD Daten im Navigationssystem und Versand der Daten auf den Most
";
CM_ SG_ 1123 PSD_Pos_Segment_ID "Identifier des Streckensegments, auf dem sich das Fahrzeug aktuell befindet
";
CM_ SG_ 1123 PSD_Pos_Segmentlaenge "Verbleibende Länge des Streckensegments, auf dem sich das Fahrzeug aktuell befindet
";
CM_ SG_ 1123 PSD_Pos_Standort_Eindeutig "Ist die Position des Fahrzeugs eindeutig dem aktuelle Segment zugeordnet, oder gibt es fahrbare alternative Segmente, die bei akteller GPS-Position ebenfalls als aktuelles Segment möglich wären.";

CM_ SG_ 1124 PSD_06_Mux "Multiplex Zähler für die PSD_06-Botschaft.
Die unterschiedlichen Muxe folgen keiner festen Reihenfolge. Je nach Inhalt des PSD-Protokolls an der aktuellen Position werden jeweils die notwendigen PSD6-Botschaften gesendet.";
CM_ SG_ 1124 PSD_Attribut_3_ID "Identifier des dritten Attributes";
CM_ SG_ 1124 PSD_Attribut_3_Offset "Positionsoffset im Segment für die Position des Attributs";
CM_ SG_ 1124 PSD_Attribut_3_Wert "Wert des dritten Attributes";
CM_ SG_ 1124 PSD_Attribut_4_ID "Typ von Attribut 4";
CM_ SG_ 1124 PSD_Attribut_4_Offset "Offset von Attribut 4";
CM_ SG_ 1124 PSD_Attribut_4_Wert "Wert von Attribut 4";
CM_ SG_ 1124 PSD_Attribut_5_ID "Typ von Attribut 5";
CM_ SG_ 1124 PSD_Attribut_5_Offset "Offset von Attribut 5";
CM_ SG_ 1124 PSD_Attribut_5_Wert "Wert von Attribut 5";
CM_ SG_ 1124 PSD_Attribut_Segment_ID "Identifier des Streckensegments,für das die weiteren Attribute in der Botschaft gültig sind";
CM_ SG_ 1124 PSD_Attribute_Komplett_06 "Zeigt, ob alle Attribute für das Segment übertragen worden sind
";
CM_ SG_ 1124 PSD_Baum_Ausrichtung "Ausrichtung des Fahrzeugsegments zu Nord";
CM_ SG_ 1124 PSD_Baum_Breite "WGS84 Breite des Fahrzeugsegments";
CM_ SG_ 1124 PSD_Baum_Breite_VZ "Vorzeichen WGS84 Breite des Fahrzeugsegments";
CM_ SG_ 1124 PSD_Baum_Laenge "WGS84 Laenge des Fahrzeugsegments";
CM_ SG_ 1124 PSD_Baum_Laenge_VZ "Vorzeichen WGS84 Laenge des Fahrzeugsegments";
CM_ SG_ 1124 PSD_Ges_Attribute_Komplett "Zeigt, ob alle Attribute für das Segment übertragen worden sind";
CM_ SG_ 1124 PSD_Ges_Geschwindigkeit_Gespann "Gilt diese Einschränkung der Geschwindigkeit für alle Fahrzeuge oder ausschließlich für PKW mit Gespann oder für LKW, Buss, etc.";
CM_ SG_ 1124 PSD_Ges_Geschwindigkeit_Std_Anf "Stunde, zu der die stündliche Geschwindigkeitsbegrenzung beginnt
0h.. 24h";
CM_ SG_ 1124 PSD_Ges_Geschwindigkeit_Std_Ende "Stunde, an der die stündliche Geschwindigkeitsbegrenzung endet
0h.. 24h";
CM_ SG_ 1124 PSD_Ges_Geschwindigkeit_Tag_Anf "Wochentag, an dem die tägliche Geschwindigkeitsbegrenzung beginnt";
CM_ SG_ 1124 PSD_Ges_Geschwindigkeit_Tag_Ende "Wochentag, an dem die tägliche Geschwindigkeitsbegrenzung endet";
CM_ SG_ 1124 PSD_Ges_Geschwindigkeit_Witter "Witterungsabhängigkeit der Geschwindigkeitsbegrenzung";
CM_ SG_ 1124 PSD_Ges_Gesetzlich_Kategorie "Kategorie für das legale Gebot";
CM_ SG_ 1124 PSD_Ges_Gesetzlich_Zusatz "Zusatz für das legale Gebot";
CM_ SG_ 1124 PSD_Ges_Offset "Positionsoffset im Segment für die Position des Attributs";
CM_ SG_ 1124 PSD_Ges_Segment_ID "Identifier des prädiktiven Streckensegments ab dem die Geschwindigkeitsbegrenzungen und mögliche Einschränkungen gelten.
";
CM_ SG_ 1124 PSD_Ges_Spur_Geschw_Begrenzung "Definition der Spuren, für die das übertragene Gebot gilt";
CM_ SG_ 1124 PSD_Ges_Typ "Typ der Geschwindigkeitsbegrenzung
";
CM_ SG_ 1124 PSD_Ges_Verkehrszeichen_Quelle "Quelle der Verkehrszeicheninformation";
CM_ SG_ 1124 PSD_Ges_Wechselverkehrszeichen "Am Beginn des Segments ist ein Wechselverkehrszeichen angebracht.";
CM_ SG_ 1124 PSD_Steigung_1_A_Offset "Positionsoffset im Segment für die Position der Steigung 1 A";
CM_ SG_ 1124 PSD_Steigung_1_A_Steigung "Steigung des Segments ab Offset 1A";
CM_ SG_ 1124 PSD_Steigung_1_A_Vorz "Vorzeichen für Steigung 1 A";
CM_ SG_ 1124 PSD_Steigung_1_Attribute_kompl "Alle Steigungsdaten für dieses Segment gesendet";
CM_ SG_ 1124 PSD_Steigung_1_B_Offset "Positionsoffset im Segment für die Position der Steigung 1 B";
CM_ SG_ 1124 PSD_Steigung_1_B_Steigung "Steigung des Segments ab Offset 1B";
CM_ SG_ 1124 PSD_Steigung_1_B_Vorz "Vorzeichen für Steigung 1 B";
CM_ SG_ 1124 PSD_Steigung_1_Segment_ID "Identifier des prädiktiven Streckensegments, zu dem die  ersten beiden Steigungswerte dieser Botschaft gehören";
CM_ SG_ 1124 PSD_Steigung_2_Attribute_kompl "Alle Steigungsdaten für dieses Segment gesendet";
CM_ SG_ 1124 PSD_Steigung_2_Offset "Positionsoffset im Segment für die Position der Steigung 2";
CM_ SG_ 1124 PSD_Steigung_2_Segment_ID "Identifier des prädiktiven Streckensegments, zu dem der dritte Steigungswert dieser Botschaft gehört";
CM_ SG_ 1124 PSD_Steigung_2_Steigung "Steigung des Segments ab Offset 2";
CM_ SG_ 1124 PSD_Steigung_2_Vorz "Vorzeichen für Steigung 2";
CM_ SG_ 1124 PSD_Sys_Alter_Karte "Alter der Karte";
CM_ SG_ 1124 PSD_Sys_Geometrieguete "Maß für die Güte der Klothoidengeometrie.";
CM_ SG_ 1124 PSD_Sys_Geometrieguete_erweitert "Güte der Kurvenrepräsentation der Klothoiden";
CM_ SG_ 1124 PSD_Sys_Geschwindigkeit_Einheit "Unterscheidung zwischen km/h und miles/h";
CM_ SG_ 1124 PSD_Sys_Laendercode "Ländercode
";
CM_ SG_ 1124 PSD_Sys_Mapmatchingguete "Güte des Mapmatchings";
CM_ SG_ 1124 PSD_Sys_Quali_Geometrien "Qualität der Geometrien in dieser Region";
CM_ SG_ 1124 PSD_Sys_Quali_Ortsinfo "Qualität Ortsinformationen (Bebauung, Ortsschild) dieser Region";
CM_ SG_ 1124 PSD_Sys_Quali_sonstige_Attribute "Qualität sonstiger Attribute dieser Region";
CM_ SG_ 1124 PSD_Sys_Quali_Steigungen "Qualität der Steigungen dieser Region";
CM_ SG_ 1124 PSD_Sys_Quali_Strassenkennz "Qualität Straßenkennzeichnungen dieser Region";
CM_ SG_ 1124 PSD_Sys_Quali_Tempolimits "Qualität Tempolimits dieser Region";
CM_ SG_ 1124 PSD_Sys_Quali_verfuegbar "Karte enthält gültige Qualitätskriterien";
CM_ SG_ 1124 PSD_Sys_Quali_Vorfahrtsregelung "Qualität Vorfahrtsregelungen dieser Region";
CM_ SG_ 1124 PSD_Sys_Segment_ID "Identifier des prädiktiven Streckensegments ab dem die Systeminformationen gültig sind.
";
CM_ SG_ 1124 PSD_Sys_US_State "Name des USA-State";
CM_ SG_ 1124 PSD_Sys_Verkehrsrichtung "Unterscheidung zwischen Linksverkehr und Rechtsverkehr";
CM_ SG_ 1124 PSD_Sys_Zielfuehrung "Zielfuehrung im Navigationssystem. Damit lässt sich der wahrscheinlichste Pfad des Fahrzeuges zuverlässig angeben.";
CM_ SG_ 1124 PSD_Sys_Zielfuehrung_geaendert "Die Zielführung (Route) hat sich geändert hat ohne dass der Fahrer eine neue Zielführung gestartet hat";
CM_ SG_ 1124 PSD_Wechselverkehrszeichen_Typ "Typ des Wechselverkehrszeichen";
BA_DEF_REL_ BU_SG_REL_  "GenSigTimeoutTime" INT 0 65535;
BA_DEF_ BO_  "DiagRequest" ENUM "No", "Yes";
BA_DEF_ BO_  "DiagResponse" ENUM "No", "Yes";
BA_DEF_ BO_  "DiagState" ENUM "No", "Yes";
BA_DEF_ BO_  "GenMsgChkConstant" HEX 0 4095;
BA_DEF_ BO_  "GenMsgCycleTime" INT 0 65535;
BA_DEF_ BO_  "GenMsgCycleTimeFast" INT 0 65535;
BA_DEF_ BO_  "GenMsgDelayTime" INT 0 100000;
BA_DEF_ BO_  "GenMsgILSupport" ENUM "No", "Yes";
BA_DEF_ BO_  "GenMsgNrOfRepetition" INT 0 100;
BA_DEF_ BO_  "GenMsgPDUConstants" STRING;
BA_DEF_ BO_  "GenMsgSendType" ENUM "Cyclic", "not_used", "not_used", "not_used", "not_used", "not_used", "not_used", "IfActive", "NoMsgSendType";
BA_DEF_ BO_  "GenMsgStartDelayTime" INT 0 100000;
BA_DEF_ BO_  "NmMessage" ENUM "No", "Yes";
BA_DEF_ BO_  "NmhMessage" ENUM "No", "Yes";
BA_DEF_ BO_  "MsgType" ENUM "Application", "NM ", "NMH", "TP2.0", "ISO-TP ", "BAP", "EID", "KS", "XCP_PRE_CONFIGURED", "XCP_RUNTIME_CONFIGURED";
BA_DEF_ BO_  "VAGTP20_API" HEX 0 255;
BA_DEF_ BO_  "VAGTP20_DynConnection" ENUM "No", "Yes";
BA_DEF_ BO_  "VAGTP20_DynSetup" ENUM "No", "Yes";
BA_DEF_ BO_  "VAGTP20_StatConnection" ENUM "No", "Yes";
BA_DEF_ SG_  "GenSigActiveRepetitions" INT -2147483648 2147483647;
BA_DEF_ SG_  "GenSigInactiveValue" INT -2147483648 2147483647;
BA_DEF_ SG_  "GenSigSendType" ENUM "Cyclic", "OnWrite", "OnWriteWithRepetition", "OnChange", "OnChangeWithRepetition", "IfActive", "IfActiveWithRepetition", "NoSigSendType", "OnChangeAndIfActive", "OnChangeAndIfActiveWithRepetition";
BA_DEF_ SG_  "GenSigStartValue" INT -2147483648 2147483647;
BA_DEF_ SG_  "NWM-WakeupAllowed" ENUM "No", "Yes";
BA_DEF_ SG_  "GenSigFuncType" ENUM "NoFunction", "MsgCounter", "CRC-8", "XOR", "XOR-2", "DatedBit", "SW-Kl15", "CHK", "Constant", "Protocol", "CRC-8-SAE_J1850", "CRC-32", "DataLength", "DataID", "MsgCounter16", "SOK-Signatur", "Cluster";
BA_DEF_ SG_  "GenSigSwitchedByIgnition" ENUM "No", "Yes";
BA_DEF_ SG_  "Fehlerwert" HEX 0 2147483647;
BA_DEF_ SG_  "GenSigMissingSourceValue" HEX 0 2147483647;
BA_DEF_DEF_REL_  "GenSigTimeoutTime" 0;
BA_DEF_DEF_  "DiagRequest" "No";
BA_DEF_DEF_  "DiagResponse" "No";
BA_DEF_DEF_  "DiagState" "No";
BA_DEF_DEF_  "GenMsgChkConstant" 0;
BA_DEF_DEF_  "GenMsgCycleTime" 0;
BA_DEF_DEF_  "GenMsgCycleTimeFast" 0;
BA_DEF_DEF_  "GenMsgDelayTime" 0;
BA_DEF_DEF_  "GenMsgILSupport" "No";
BA_DEF_DEF_  "GenMsgNrOfRepetition" 0;
BA_DEF_DEF_  "GenMsgPDUConstants" "";
BA_DEF_DEF_  "GenMsgSendType" "NoMsgSendType";
BA_DEF_DEF_  "GenMsgStartDelayTime" 0;
BA_DEF_DEF_  "NmMessage" "No";
BA_DEF_DEF_  "NmhMessage" "No";
BA_DEF_DEF_  "MsgType" "Application";
BA_DEF_DEF_  "VAGTP20_API" 0;
BA_DEF_DEF_  "VAGTP20_DynConnection" "No";
BA_DEF_DEF_  "VAGTP20_DynSetup" "No";
BA_DEF_DEF_  "VAGTP20_StatConnection" "No";
BA_DEF_DEF_  "GenSigActiveRepetitions" 0;
BA_DEF_DEF_  "GenSigInactiveValue" 0;
BA_DEF_DEF_  "GenSigSendType" "NoSigSendType";
BA_DEF_DEF_  "GenSigStartValue" 0;
BA_DEF_DEF_  "NWM-WakeupAllowed" "No";
BA_DEF_DEF_  "GenSigFuncType" "NoFunction";
BA_DEF_DEF_  "GenSigSwitchedByIgnition" "Yes";
BA_DEF_DEF_  "Fehlerwert" 0;
BA_DEF_DEF_  "GenSigMissingSourceValue" 0;
BA_ "GenMsgCycleTime" BO_ 2600468585 200;
BA_ "GenMsgCycleTimeFast" BO_ 2600468585 10;
BA_ "GenMsgNrOfRepetition" BO_ 2600468585 3;
BA_ "GenMsgSendType" BO_ 2600468585 7;
BA_ "NmhMessage" BO_ 2600468585 1;
BA_ "MsgType" BO_ 2600468585 2;
BA_ "GenMsgCycleTime" BO_ 2600468522 200;
BA_ "GenMsgCycleTimeFast" BO_ 2600468522 10;
BA_ "GenMsgNrOfRepetition" BO_ 2600468522 3;
BA_ "GenMsgSendType" BO_ 2600468522 7;
BA_ "NmhMessage" BO_ 2600468522 1;
BA_ "MsgType" BO_ 2600468522 2;
BA_ "GenMsgCycleTime" BO_ 2600468586 200;
BA_ "GenMsgCycleTimeFast" BO_ 2600468586 10;
BA_ "GenMsgNrOfRepetition" BO_ 2600468586 3;
BA_ "GenMsgSendType" BO_ 2600468586 7;
BA_ "NmhMessage" BO_ 2600468586 1;
BA_ "MsgType" BO_ 2600468586 2;
BA_ "GenMsgCycleTime" BO_ 2600468558 200;
BA_ "GenMsgCycleTimeFast" BO_ 2600468558 10;
BA_ "GenMsgNrOfRepetition" BO_ 2600468558 3;
BA_ "GenMsgSendType" BO_ 2600468558 7;
BA_ "NmhMessage" BO_ 2600468558 1;
BA_ "MsgType" BO_ 2600468558 2;
BA_ "GenMsgCycleTime" BO_ 2600468618 200;
BA_ "GenMsgCycleTimeFast" BO_ 2600468618 10;
BA_ "GenMsgNrOfRepetition" BO_ 2600468618 3;
BA_ "GenMsgSendType" BO_ 2600468618 7;
BA_ "NmhMessage" BO_ 2600468618 1;
BA_ "MsgType" BO_ 2600468618 2;
BA_ "GenMsgCycleTime" BO_ 1377 40;
BA_ "GenMsgILSupport" BO_ 1377 1;
BA_ "GenMsgSendType" BO_ 1377 0;
BA_ "GenMsgCycleTime" BO_ 597 40;
BA_ "GenMsgILSupport" BO_ 597 1;
BA_ "GenMsgSendType" BO_ 597 0;
BA_ "GenMsgCycleTime" BO_ 598 40;
BA_ "GenMsgILSupport" BO_ 598 1;
BA_ "GenMsgSendType" BO_ 598 0;
BA_ "GenMsgCycleTime" BO_ 601 40;
BA_ "GenMsgILSupport" BO_ 601 1;
BA_ "GenMsgSendType" BO_ 601 0;
BA_ "GenMsgCycleTime" BO_ 1635 100;
BA_ "GenMsgILSupport" BO_ 1635 1;
BA_ "GenMsgPDUConstants" BO_ 1635 "0x7d,0xba,0x97,0x94,0x5a,0x4a,0xeb,0xd4,0x6c,0x28,0x54,0x81,0xc7,0x1c,0x25,0x2a";
BA_ "GenMsgSendType" BO_ 1635 0;
BA_ "GenMsgStartDelayTime" BO_ 1635 10;
BA_ "GenMsgCycleTime" BO_ 913 200;
BA_ "GenMsgILSupport" BO_ 913 1;
BA_ "GenMsgSendType" BO_ 913 0;
BA_ "GenMsgCycleTime" BO_ 2589283478 320;
BA_ "GenMsgILSupport" BO_ 2589283478 1;
BA_ "GenMsgSendType" BO_ 2589283478 0;
BA_ "DiagRequest" BO_ 2549875246 1;
BA_ "MsgType" BO_ 2549875246 4;
BA_ "DiagResponse" BO_ 2550006318 1;
BA_ "MsgType" BO_ 2550006318 4;
BA_ "DiagRequest" BO_ 2549875248 1;
BA_ "MsgType" BO_ 2549875248 4;
BA_ "DiagResponse" BO_ 2550006320 1;
BA_ "MsgType" BO_ 2550006320 4;
BA_ "DiagState" BO_ 2549940736 1;
BA_ "MsgType" BO_ 2549940736 4;
BA_ "DiagRequest" BO_ 2549875239 1;
BA_ "MsgType" BO_ 2549875239 4;
BA_ "DiagResponse" BO_ 2550006311 1;
BA_ "MsgType" BO_ 2550006311 4;
BA_ "DiagRequest" BO_ 2549875211 1;
BA_ "MsgType" BO_ 2549875211 4;
BA_ "DiagResponse" BO_ 2550006283 1;
BA_ "MsgType" BO_ 2550006283 4;
BA_ "DiagRequest" BO_ 2549875305 1;
BA_ "MsgType" BO_ 2549875305 4;
BA_ "DiagResponse" BO_ 2550006377 1;
BA_ "MsgType" BO_ 2550006377 4;
BA_ "DiagRequest" BO_ 2549875242 1;
BA_ "MsgType" BO_ 2549875242 4;
BA_ "DiagResponse" BO_ 2550006314 1;
BA_ "MsgType" BO_ 2550006314 4;
BA_ "DiagRequest" BO_ 2549875300 1;
BA_ "MsgType" BO_ 2549875300 4;
BA_ "DiagResponse" BO_ 2550006372 1;
BA_ "MsgType" BO_ 2550006372 4;
BA_ "DiagRequest" BO_ 2549875228 1;
BA_ "MsgType" BO_ 2549875228 4;
BA_ "DiagResponse" BO_ 2550006300 1;
BA_ "MsgType" BO_ 2550006300 4;
BA_ "DiagRequest" BO_ 2549875306 1;
BA_ "MsgType" BO_ 2549875306 4;
BA_ "DiagResponse" BO_ 2550006378 1;
BA_ "MsgType" BO_ 2550006378 4;
BA_ "DiagRequest" BO_ 2549875338 1;
BA_ "MsgType" BO_ 2549875338 4;
BA_ "DiagResponse" BO_ 2550006410 1;
BA_ "MsgType" BO_ 2550006410 4;
BA_ "DiagRequest" BO_ 2549875278 1;
BA_ "MsgType" BO_ 2549875278 4;
BA_ "DiagResponse" BO_ 2550006350 1;
BA_ "MsgType" BO_ 2550006350 4;
BA_ "GenMsgCycleTime" BO_ 2589283656 960;
BA_ "GenMsgDelayTime" BO_ 2589283656 160;
BA_ "GenMsgILSupport" BO_ 2589283656 1;
BA_ "GenMsgPDUConstants" BO_ 2589283656 "0xee,0xcc,0x2f,0x27,0x93,0x0c,0x45,0x97,0x87,0x2e,0xec,0x3b,0xd3,0x35,0xcb,0x4a";
BA_ "GenMsgSendType" BO_ 2589283656 0;
BA_ "GenMsgStartDelayTime" BO_ 2589283656 160;
BA_ "GenMsgCycleTime" BO_ 1175 100;
BA_ "GenMsgDelayTime" BO_ 1175 50;
BA_ "GenMsgILSupport" BO_ 1175 1;
BA_ "GenMsgSendType" BO_ 1175 0;
BA_ "GenMsgCycleTimeFast" BO_ 1353 100;
BA_ "GenMsgILSupport" BO_ 1353 1;
BA_ "GenMsgSendType" BO_ 1353 7;
BA_ "GenMsgCycleTimeFast" BO_ 1354 100;
BA_ "GenMsgILSupport" BO_ 1354 1;
BA_ "GenMsgSendType" BO_ 1354 7;
BA_ "GenMsgCycleTime" BO_ 1355 500;
BA_ "GenMsgDelayTime" BO_ 1355 20;
BA_ "GenMsgILSupport" BO_ 1355 1;
BA_ "GenMsgSendType" BO_ 1355 0;
BA_ "GenMsgCycleTime" BO_ 2527679498 1000;
BA_ "GenMsgCycleTimeFast" BO_ 2527679498 200;
BA_ "GenMsgDelayTime" BO_ 2527679498 50;
BA_ "GenMsgILSupport" BO_ 2527679498 1;
BA_ "GenMsgNrOfRepetition" BO_ 2527679498 3;
BA_ "GenMsgSendType" BO_ 2527679498 0;
BA_ "GenMsgCycleTime" BO_ 319 200;
BA_ "GenMsgDelayTime" BO_ 319 20;
BA_ "GenMsgILSupport" BO_ 319 1;
BA_ "GenMsgPDUConstants" BO_ 319 "0x28,0x6e,0x5a,0xc6,0x52,0x65,0x85,0xa1,0xb8,0xe6,0x38,0x88,0xf8,0xb9,0x2b,0xb0";
BA_ "GenMsgSendType" BO_ 319 0;
BA_ "GenMsgCycleTime" BO_ 1122 150;
BA_ "GenMsgILSupport" BO_ 1122 1;
BA_ "GenMsgSendType" BO_ 1122 0;
BA_ "GenMsgCycleTime" BO_ 1123 150;
BA_ "GenMsgILSupport" BO_ 1123 1;
BA_ "GenMsgSendType" BO_ 1123 0;
BA_ "GenMsgCycleTime" BO_ 1124 150;
BA_ "GenMsgILSupport" BO_ 1124 1;
BA_ "GenMsgSendType" BO_ 1124 0;
BA_ "GenSigActiveRepetitions" SG_ 2600468585 NM_RearView_CAB 3;
BA_ "GenSigSendType" SG_ 2600468585 NM_RearView_CAB 4;
BA_ "GenSigSwitchedByIgnition" SG_ 2600468585 NM_RearView_CAB 0;
BA_ "GenSigSendType" SG_ 2600468585 NM_Rearview_Car_Wakeup 3;
BA_ "GenSigSwitchedByIgnition" SG_ 2600468585 NM_Rearview_Car_Wakeup 0;
BA_ "GenSigSwitchedByIgnition" SG_ 2600468585 NM_Rearview_CBV_AWB 0;
BA_ "GenSigSwitchedByIgnition" SG_ 2600468585 NM_Rearview_CBV_CRI 0;
BA_ "GenSigSwitchedByIgnition" SG_ 2600468585 NM_Rearview_NM_aktiv_Diagnose 0;
BA_ "GenSigSwitchedByIgnition" SG_ 2600468585 NM_Rearview_NM_aktiv_KL15 0;
BA_ "GenSigSwitchedByIgnition" SG_ 2600468585 NM_Rearview_NM_aktiv_Tmin 0;
BA_ "GenSigSwitchedByIgnition" SG_ 2600468585 NM_Rearview_NM_State 0;
BA_ "GenSigStartValue" SG_ 2600468585 NM_Rearview_SNI 105;
BA_ "GenSigSwitchedByIgnition" SG_ 2600468585 NM_Rearview_SNI 0;
BA_ "GenSigSwitchedByIgnition" SG_ 2600468585 NM_Rearview_UDS_CC 0;
BA_ "GenSigActiveRepetitions" SG_ 2600468522 NM_SCR_CAB 3;
BA_ "GenSigSendType" SG_ 2600468522 NM_SCR_CAB 4;
BA_ "GenSigSwitchedByIgnition" SG_ 2600468522 NM_SCR_CAB 0;
BA_ "GenSigSendType" SG_ 2600468522 NM_SCR_Car_Wakeup 3;
BA_ "GenSigSwitchedByIgnition" SG_ 2600468522 NM_SCR_Car_Wakeup 0;
BA_ "GenSigSwitchedByIgnition" SG_ 2600468522 NM_SCR_CBV_AWB 0;
BA_ "GenSigSwitchedByIgnition" SG_ 2600468522 NM_SCR_CBV_CRI 0;
BA_ "GenSigSwitchedByIgnition" SG_ 2600468522 NM_SCR_NM_aktiv_Diagnose 0;
BA_ "GenSigSwitchedByIgnition" SG_ 2600468522 NM_SCR_NM_aktiv_Evakuierung_Sys 0;
BA_ "GenSigSwitchedByIgnition" SG_ 2600468522 NM_SCR_NM_aktiv_KL15 0;
BA_ "GenSigSwitchedByIgnition" SG_ 2600468522 NM_SCR_NM_aktiv_Tmin 0;
BA_ "GenSigSwitchedByIgnition" SG_ 2600468522 NM_SCR_NM_State 0;
BA_ "GenSigStartValue" SG_ 2600468522 NM_SCR_SNI 42;
BA_ "GenSigSwitchedByIgnition" SG_ 2600468522 NM_SCR_SNI 0;
BA_ "GenSigSwitchedByIgnition" SG_ 2600468522 NM_SCR_UDS_CC 0;
BA_ "GenSigActiveRepetitions" SG_ 2600468586 NM_STH_CAB 3;
BA_ "GenSigSendType" SG_ 2600468586 NM_STH_CAB 4;
BA_ "GenSigSwitchedByIgnition" SG_ 2600468586 NM_STH_CAB 0;
BA_ "GenSigSendType" SG_ 2600468586 NM_STH_Car_Wakeup 3;
BA_ "GenSigSwitchedByIgnition" SG_ 2600468586 NM_STH_Car_Wakeup 0;
BA_ "GenSigSwitchedByIgnition" SG_ 2600468586 NM_STH_CBV_AWB 0;
BA_ "GenSigSwitchedByIgnition" SG_ 2600468586 NM_STH_CBV_CRI 0;
BA_ "GenSigSwitchedByIgnition" SG_ 2600468586 NM_STH_NM_aktiv_Diagnose 0;
BA_ "GenSigSwitchedByIgnition" SG_ 2600468586 NM_STH_NM_aktiv_EIN_AUS_Funk 0;
BA_ "GenSigSwitchedByIgnition" SG_ 2600468586 NM_STH_NM_aktiv_EKP_Anf 0;
BA_ "GenSigSwitchedByIgnition" SG_ 2600468586 NM_STH_NM_aktiv_KL15 0;
BA_ "GenSigSwitchedByIgnition" SG_ 2600468586 NM_STH_NM_aktiv_Tmin 0;
BA_ "GenSigSwitchedByIgnition" SG_ 2600468586 NM_STH_NM_aktiv_WaPu_Anf 0;
BA_ "GenSigSwitchedByIgnition" SG_ 2600468586 NM_STH_NM_State 0;
BA_ "GenSigStartValue" SG_ 2600468586 NM_STH_SNI 106;
BA_ "GenSigSwitchedByIgnition" SG_ 2600468586 NM_STH_SNI 0;
BA_ "GenSigSwitchedByIgnition" SG_ 2600468586 NM_STH_UDS_CC 0;
BA_ "GenSigActiveRepetitions" SG_ 2600468558 NM_SWA_CAB 3;
BA_ "GenSigSendType" SG_ 2600468558 NM_SWA_CAB 4;
BA_ "GenSigSwitchedByIgnition" SG_ 2600468558 NM_SWA_CAB 0;
BA_ "GenSigSendType" SG_ 2600468558 NM_SWA_Car_Wakeup 3;
BA_ "GenSigSwitchedByIgnition" SG_ 2600468558 NM_SWA_Car_Wakeup 0;
BA_ "GenSigSwitchedByIgnition" SG_ 2600468558 NM_SWA_CBV_AWB 0;
BA_ "GenSigFuncType" SG_ 2600468558 NM_SWA_CBV_CRI 8;
BA_ "GenSigSwitchedByIgnition" SG_ 2600468558 NM_SWA_CBV_CRI 0;
BA_ "GenSigSwitchedByIgnition" SG_ 2600468558 NM_SWA_NM_aktiv_ASW_aktiv 0;
BA_ "GenSigSwitchedByIgnition" SG_ 2600468558 NM_SWA_NM_aktiv_Diagnose 0;
BA_ "GenSigSwitchedByIgnition" SG_ 2600468558 NM_SWA_NM_aktiv_KL15 0;
BA_ "GenSigSwitchedByIgnition" SG_ 2600468558 NM_SWA_NM_aktiv_Tmin 0;
BA_ "GenSigSwitchedByIgnition" SG_ 2600468558 NM_SWA_NM_State 0;
BA_ "GenSigStartValue" SG_ 2600468558 NM_SWA_SNI 78;
BA_ "GenSigSwitchedByIgnition" SG_ 2600468558 NM_SWA_SNI 0;
BA_ "GenSigSwitchedByIgnition" SG_ 2600468558 NM_SWA_UDS_CC 0;
BA_ "GenSigActiveRepetitions" SG_ 2600468618 NM_SWA_Slave_CAB 3;
BA_ "GenSigSendType" SG_ 2600468618 NM_SWA_Slave_CAB 4;
BA_ "GenSigSwitchedByIgnition" SG_ 2600468618 NM_SWA_Slave_CAB 0;
BA_ "GenSigSendType" SG_ 2600468618 NM_SWA_Slave_Car_Wakeup 3;
BA_ "GenSigSwitchedByIgnition" SG_ 2600468618 NM_SWA_Slave_Car_Wakeup 0;
BA_ "GenSigSwitchedByIgnition" SG_ 2600468618 NM_SWA_Slave_CBV_AWB 0;
BA_ "GenSigFuncType" SG_ 2600468618 NM_SWA_Slave_CBV_CRI 8;
BA_ "GenSigSwitchedByIgnition" SG_ 2600468618 NM_SWA_Slave_CBV_CRI 0;
BA_ "GenSigSwitchedByIgnition" SG_ 2600468618 NM_SWA_Slave_NM_aktiv_ASW_aktiv 0;
BA_ "GenSigSwitchedByIgnition" SG_ 2600468618 NM_SWA_Slave_NM_aktiv_Diagnose 0;
BA_ "GenSigSwitchedByIgnition" SG_ 2600468618 NM_SWA_Slave_NM_aktiv_KL15 0;
BA_ "GenSigSwitchedByIgnition" SG_ 2600468618 NM_SWA_Slave_NM_aktiv_Tmin 0;
BA_ "GenSigSwitchedByIgnition" SG_ 2600468618 NM_SWA_Slave_NM_State 0;
BA_ "GenSigStartValue" SG_ 2600468618 NM_SWA_Slave_SNI 138;
BA_ "GenSigSwitchedByIgnition" SG_ 2600468618 NM_SWA_Slave_SNI 0;
BA_ "GenSigSwitchedByIgnition" SG_ 2600468618 NM_SWA_Slave_UDS_CC 0;
BA_ "GenSigSendType" SG_ 1377 NV_MessZeitpunkt 0;
BA_ "GenSigStartValue" SG_ 1377 NV_MessZeitpunkt 8191;
BA_ "GenSigSendType" SG_ 1377 NV_NichtVerfuegbar 0;
BA_ "GenSigStartValue" SG_ 1377 NV_NichtVerfuegbar 1;
BA_ "GenSigSendType" SG_ 1377 NV_Obj_01_InvTTCBildebStdA 0;
BA_ "GenSigStartValue" SG_ 1377 NV_Obj_01_InvTTCBildebStdA 127;
BA_ "GenSigSendType" SG_ 1377 NV_Obj_01_Klasse 0;
BA_ "GenSigStartValue" SG_ 1377 NV_Obj_01_Klasse 15;
BA_ "GenSigSendType" SG_ 1377 NV_Obj_Links 0;
BA_ "GenSigSendType" SG_ 1377 NV_Obj_Rechts 0;
BA_ "GenSigSendType" SG_ 1377 NV_Obj_Warnung_Fussgaenger 0;
BA_ "GenSigSendType" SG_ 1377 NV_Sensor_PositionX 0;
BA_ "GenSigStartValue" SG_ 1377 NV_Sensor_PositionX 4095;
BA_ "GenSigSendType" SG_ 1377 NV_Sensor_PositionY 0;
BA_ "GenSigStartValue" SG_ 1377 NV_Sensor_PositionY 2047;
BA_ "GenSigSendType" SG_ 1377 NV_Sensor_PositionZ 0;
BA_ "GenSigStartValue" SG_ 1377 NV_Sensor_PositionZ 2047;
BA_ "GenSigSendType" SG_ 597 NV_Obj_01_Gemessen 0;
BA_ "GenSigSendType" SG_ 597 NV_Obj_01_ID 0;
BA_ "GenSigStartValue" SG_ 597 NV_Obj_01_ID 15;
BA_ "GenSigSendType" SG_ 597 NV_Obj_01_InvTTCBildeb 0;
BA_ "GenSigStartValue" SG_ 597 NV_Obj_01_InvTTCBildeb 1023;
BA_ "GenSigSendType" SG_ 597 NV_Obj_01_RadialDistanz 0;
BA_ "GenSigStartValue" SG_ 597 NV_Obj_01_RadialDistanz 4095;
BA_ "GenSigSendType" SG_ 597 NV_Obj_01_RadialDistanzStdA 0;
BA_ "GenSigStartValue" SG_ 597 NV_Obj_01_RadialDistanzStdA 127;
BA_ "GenSigSendType" SG_ 597 NV_Obj_01_WnklBreite 0;
BA_ "GenSigStartValue" SG_ 597 NV_Obj_01_WnklBreite 63;
BA_ "GenSigSendType" SG_ 597 NV_Obj_01_WnklBreiteStdA 0;
BA_ "GenSigStartValue" SG_ 597 NV_Obj_01_WnklBreiteStdA 7;
BA_ "GenSigSendType" SG_ 597 NV_Obj_01_WnklHoehe 0;
BA_ "GenSigStartValue" SG_ 597 NV_Obj_01_WnklHoehe 15;
BA_ "GenSigSendType" SG_ 597 NV_Obj_01_WnklHorMitte 0;
BA_ "GenSigStartValue" SG_ 597 NV_Obj_01_WnklHorMitte 63;
BA_ "GenSigSendType" SG_ 597 NV_Obj_01_WnklHorMitteStdA 0;
BA_ "GenSigStartValue" SG_ 597 NV_Obj_01_WnklHorMitteStdA 7;
BA_ "GenSigSendType" SG_ 597 NV_Obj_01_WnklVertMitte 0;
BA_ "GenSigStartValue" SG_ 597 NV_Obj_01_WnklVertMitte 15;
BA_ "GenSigSendType" SG_ 598 NV_Obj_02_Gemessen 0;
BA_ "GenSigSendType" SG_ 598 NV_Obj_02_ID 0;
BA_ "GenSigStartValue" SG_ 598 NV_Obj_02_ID 15;
BA_ "GenSigSendType" SG_ 598 NV_Obj_02_Klasse 0;
BA_ "GenSigStartValue" SG_ 598 NV_Obj_02_Klasse 15;
BA_ "GenSigSendType" SG_ 598 NV_Obj_02_RadialDistanzRed 0;
BA_ "GenSigStartValue" SG_ 598 NV_Obj_02_RadialDistanzRed 255;
BA_ "GenSigSendType" SG_ 598 NV_Obj_02_RadialDistanzRedStdA 0;
BA_ "GenSigStartValue" SG_ 598 NV_Obj_02_RadialDistanzRedStdA 15;
BA_ "GenSigSendType" SG_ 598 NV_Obj_02_WnklBreite 0;
BA_ "GenSigStartValue" SG_ 598 NV_Obj_02_WnklBreite 63;
BA_ "GenSigSendType" SG_ 598 NV_Obj_02_WnklHoehe 0;
BA_ "GenSigStartValue" SG_ 598 NV_Obj_02_WnklHoehe 15;
BA_ "GenSigSendType" SG_ 598 NV_Obj_02_WnklHorMitte 0;
BA_ "GenSigStartValue" SG_ 598 NV_Obj_02_WnklHorMitte 63;
BA_ "GenSigSendType" SG_ 598 NV_Obj_02_WnklVertMitte 0;
BA_ "GenSigStartValue" SG_ 598 NV_Obj_02_WnklVertMitte 15;
BA_ "GenSigSendType" SG_ 598 NV_Obj_03_RadialDistanzRed 0;
BA_ "GenSigStartValue" SG_ 598 NV_Obj_03_RadialDistanzRed 255;
BA_ "GenSigSendType" SG_ 598 NV_Obj_03_RadialDistanzRedStdA 0;
BA_ "GenSigStartValue" SG_ 598 NV_Obj_03_RadialDistanzRedStdA 15;
BA_ "GenSigSendType" SG_ 598 NV_Obj_03_WnklHoehe 0;
BA_ "GenSigStartValue" SG_ 598 NV_Obj_03_WnklHoehe 15;
BA_ "GenSigSendType" SG_ 598 NV_Obj_03_WnklVertMitte 0;
BA_ "GenSigStartValue" SG_ 598 NV_Obj_03_WnklVertMitte 15;
BA_ "GenSigSendType" SG_ 601 NV_Obj_03_Gemessen 0;
BA_ "GenSigSendType" SG_ 601 NV_Obj_03_ID 0;
BA_ "GenSigStartValue" SG_ 601 NV_Obj_03_ID 15;
BA_ "GenSigSendType" SG_ 601 NV_Obj_03_Klasse 0;
BA_ "GenSigStartValue" SG_ 601 NV_Obj_03_Klasse 15;
BA_ "GenSigSendType" SG_ 601 NV_Obj_03_WnklBreite 0;
BA_ "GenSigStartValue" SG_ 601 NV_Obj_03_WnklBreite 63;
BA_ "GenSigSendType" SG_ 601 NV_Obj_03_WnklHorMitte 0;
BA_ "GenSigStartValue" SG_ 601 NV_Obj_03_WnklHorMitte 63;
BA_ "GenSigSendType" SG_ 601 NV_Obj_04_Gemessen 0;
BA_ "GenSigSendType" SG_ 601 NV_Obj_04_ID 0;
BA_ "GenSigStartValue" SG_ 601 NV_Obj_04_ID 15;
BA_ "GenSigSendType" SG_ 601 NV_Obj_04_Klasse 0;
BA_ "GenSigStartValue" SG_ 601 NV_Obj_04_Klasse 15;
BA_ "GenSigSendType" SG_ 601 NV_Obj_04_RadialDistanzRed 0;
BA_ "GenSigStartValue" SG_ 601 NV_Obj_04_RadialDistanzRed 255;
BA_ "GenSigSendType" SG_ 601 NV_Obj_04_RadialDistanzRedStdA 0;
BA_ "GenSigStartValue" SG_ 601 NV_Obj_04_RadialDistanzRedStdA 15;
BA_ "GenSigSendType" SG_ 601 NV_Obj_04_WnklBreite 0;
BA_ "GenSigStartValue" SG_ 601 NV_Obj_04_WnklBreite 63;
BA_ "GenSigSendType" SG_ 601 NV_Obj_04_WnklHoehe 0;
BA_ "GenSigStartValue" SG_ 601 NV_Obj_04_WnklHoehe 15;
BA_ "GenSigSendType" SG_ 601 NV_Obj_04_WnklHorMitte 0;
BA_ "GenSigStartValue" SG_ 601 NV_Obj_04_WnklHorMitte 63;
BA_ "GenSigSendType" SG_ 601 NV_Obj_04_WnklVertMitte 0;
BA_ "GenSigStartValue" SG_ 601 NV_Obj_04_WnklVertMitte 15;
BA_ "GenSigSendType" SG_ 1635 BEM_02_Abschaltstufen 0;
BA_ "GenSigSwitchedByIgnition" SG_ 1635 BEM_02_Abschaltstufen 0;
BA_ "GenSigSendType" SG_ 1635 BEM_Anf_KL15_schalten 0;
BA_ "GenSigSwitchedByIgnition" SG_ 1635 BEM_Anf_KL15_schalten 0;
BA_ "GenSigSendType" SG_ 1635 BEM_Batteriediagnose 0;
BA_ "GenSigSwitchedByIgnition" SG_ 1635 BEM_Batteriediagnose 0;
BA_ "Fehlerwert" SG_ 1635 BEM_Batteriediagnose 7;
BA_ "GenSigSendType" SG_ 1635 BEM_Generatordiagnose 0;
BA_ "GenSigSwitchedByIgnition" SG_ 1635 BEM_Generatordiagnose 0;
BA_ "GenSigSendType" SG_ 1635 BEM_HL_Regelung_Status 0;
BA_ "GenSigSwitchedByIgnition" SG_ 1635 BEM_HL_Regelung_Status 0;
BA_ "GenSigSendType" SG_ 1635 BEM_Ladezustand 0;
BA_ "GenSigStartValue" SG_ 1635 BEM_Ladezustand 14;
BA_ "GenSigSwitchedByIgnition" SG_ 1635 BEM_Ladezustand 0;
BA_ "Fehlerwert" SG_ 1635 BEM_Ladezustand 15;
BA_ "GenSigSendType" SG_ 1635 BEM_MMI_Vorwarnung 0;
BA_ "GenSigSwitchedByIgnition" SG_ 1635 BEM_MMI_Vorwarnung 0;
BA_ "GenSigSendType" SG_ 1635 BEM_Red_Innengeblaese 0;
BA_ "GenSigSwitchedByIgnition" SG_ 1635 BEM_Red_Innengeblaese 0;
BA_ "GenSigSendType" SG_ 1635 BEM_REK_aktiv 0;
BA_ "GenSigSwitchedByIgnition" SG_ 1635 BEM_REK_aktiv 0;
BA_ "GenSigSendType" SG_ 1635 BEM_STH_Einschaltverbot 0;
BA_ "GenSigSwitchedByIgnition" SG_ 1635 BEM_STH_Einschaltverbot 0;
BA_ "GenSigSendType" SG_ 1635 BEM_STH_Zielzeit 0;
BA_ "GenSigStartValue" SG_ 1635 BEM_STH_Zielzeit 14;
BA_ "GenSigSwitchedByIgnition" SG_ 1635 BEM_STH_Zielzeit 0;
BA_ "Fehlerwert" SG_ 1635 BEM_STH_Zielzeit 15;
BA_ "GenSigSendType" SG_ 1635 BEM_UBDM 0;
BA_ "GenSigSwitchedByIgnition" SG_ 1635 BEM_UBDM 0;
BA_ "Fehlerwert" SG_ 1635 BEM_UBDM 255;
BA_ "GenSigSendType" SG_ 1635 BEM_UGenSoll 0;
BA_ "GenSigSwitchedByIgnition" SG_ 1635 BEM_UGenSoll 0;
BA_ "GenSigSendType" SG_ 1635 MIB_Stromsparmodus 0;
BA_ "GenSigSwitchedByIgnition" SG_ 1635 MIB_Stromsparmodus 0;
BA_ "GenSigSendType" SG_ 1635 NVEM_Anf_SD_schalten 0;
BA_ "GenSigSwitchedByIgnition" SG_ 1635 NVEM_Anf_SD_schalten 0;
BA_ "GenSigSendType" SG_ 1635 NVEM_Batterie_Service 0;
BA_ "GenSigSwitchedByIgnition" SG_ 1635 NVEM_Batterie_Service 0;
BA_ "GenSigSendType" SG_ 1635 NVEM_Freigabe_OnlineUpdate 0;
BA_ "GenSigSwitchedByIgnition" SG_ 1635 NVEM_Freigabe_OnlineUpdate 0;
BA_ "GenSigSendType" SG_ 1635 NVEM_Freigabe_ORU4 0;
BA_ "GenSigSwitchedByIgnition" SG_ 1635 NVEM_Freigabe_ORU4 0;
BA_ "GenSigSendType" SG_ 1635 NVEM_Last_Anf 0;
BA_ "GenSigSwitchedByIgnition" SG_ 1635 NVEM_Last_Anf 0;
BA_ "GenSigSendType" SG_ 913 MO_QBit_Aussen_Temp 0;
BA_ "GenSigStartValue" SG_ 913 MO_QBit_Aussen_Temp 1;
BA_ "GenSigSwitchedByIgnition" SG_ 913 MO_QBit_Aussen_Temp 0;
BA_ "GenSigSendType" SG_ 913 MO_Servicemodus 0;
BA_ "GenSigSwitchedByIgnition" SG_ 913 MO_Servicemodus 0;
BA_ "GenSigSendType" SG_ 913 OBD_Abs_Load_Val 0;
BA_ "GenSigStartValue" SG_ 913 OBD_Abs_Load_Val 65535;
BA_ "GenSigSwitchedByIgnition" SG_ 913 OBD_Abs_Load_Val 0;
BA_ "GenSigSendType" SG_ 913 OBD_Abs_Pedal_Pos 0;
BA_ "GenSigStartValue" SG_ 913 OBD_Abs_Pedal_Pos 255;
BA_ "GenSigSwitchedByIgnition" SG_ 913 OBD_Abs_Pedal_Pos 0;
BA_ "GenSigSendType" SG_ 913 OBD_Abs_Throttle_Pos 0;
BA_ "GenSigStartValue" SG_ 913 OBD_Abs_Throttle_Pos 255;
BA_ "GenSigSwitchedByIgnition" SG_ 913 OBD_Abs_Throttle_Pos 0;
BA_ "GenSigSendType" SG_ 913 OBD_Calc_Load_Val 0;
BA_ "GenSigStartValue" SG_ 913 OBD_Calc_Load_Val 255;
BA_ "GenSigSwitchedByIgnition" SG_ 913 OBD_Calc_Load_Val 0;
BA_ "GenSigSendType" SG_ 913 OBD_ClearMem_Inhibit 0;
BA_ "GenSigSwitchedByIgnition" SG_ 913 OBD_ClearMem_Inhibit 0;
BA_ "GenSigSendType" SG_ 913 OBD_Driving_Cycle 0;
BA_ "GenSigSwitchedByIgnition" SG_ 913 OBD_Driving_Cycle 0;
BA_ "GenSigSendType" SG_ 913 OBD_Eng_Cool_Temp 0;
BA_ "GenSigStartValue" SG_ 913 OBD_Eng_Cool_Temp 255;
BA_ "GenSigSwitchedByIgnition" SG_ 913 OBD_Eng_Cool_Temp 0;
BA_ "GenSigSendType" SG_ 913 OBD_Kaltstart_Denominator 0;
BA_ "GenSigSwitchedByIgnition" SG_ 913 OBD_Kaltstart_Denominator 0;
BA_ "GenSigSendType" SG_ 913 OBD_Minimum_Trip 0;
BA_ "GenSigSwitchedByIgnition" SG_ 913 OBD_Minimum_Trip 0;
BA_ "GenSigSendType" SG_ 913 OBD_Normed_Trip 0;
BA_ "GenSigSwitchedByIgnition" SG_ 913 OBD_Normed_Trip 0;
BA_ "GenSigSendType" SG_ 913 OBD_Sperrung_IUMPR 0;
BA_ "GenSigSwitchedByIgnition" SG_ 913 OBD_Sperrung_IUMPR 0;
BA_ "GenSigSendType" SG_ 913 OBD_Sperrung_Kaltstart_Denom 0;
BA_ "GenSigSwitchedByIgnition" SG_ 913 OBD_Sperrung_Kaltstart_Denom 0;
BA_ "GenSigSendType" SG_ 913 OBD_Warm_Up_Cycle 0;
BA_ "GenSigSwitchedByIgnition" SG_ 913 OBD_Warm_Up_Cycle 0;
BA_ "GenSigSendType" SG_ 2589283478 OBD_Aussen_Temp_gef 0;
BA_ "GenSigStartValue" SG_ 2589283478 OBD_Aussen_Temp_gef 254;
BA_ "GenSigSwitchedByIgnition" SG_ 2589283478 OBD_Aussen_Temp_gef 0;
BA_ "Fehlerwert" SG_ 2589283478 OBD_Aussen_Temp_gef 255;
BA_ "GenSigSendType" SG_ 2549875246 OBDC_AEM_Req_Data 3;
BA_ "GenSigFuncType" SG_ 2549875246 OBDC_AEM_Req_Data 9;
BA_ "GenSigSwitchedByIgnition" SG_ 2549875246 OBDC_AEM_Req_Data 0;
BA_ "GenSigSendType" SG_ 2550006318 OBDC_AEM_Resp_Data 3;
BA_ "GenSigFuncType" SG_ 2550006318 OBDC_AEM_Resp_Data 9;
BA_ "GenSigSendType" SG_ 2549875248 OBDC_FLA_Req_Data 3;
BA_ "GenSigFuncType" SG_ 2549875248 OBDC_FLA_Req_Data 9;
BA_ "GenSigSwitchedByIgnition" SG_ 2549875248 OBDC_FLA_Req_Data 0;
BA_ "GenSigSendType" SG_ 2550006320 OBDC_FLA_Resp_Data 3;
BA_ "GenSigFuncType" SG_ 2550006320 OBDC_FLA_Resp_Data 9;
BA_ "GenSigSendType" SG_ 2549940736 OBDC_Funktionaler_Req_All_Data 3;
BA_ "GenSigFuncType" SG_ 2549940736 OBDC_Funktionaler_Req_All_Data 9;
BA_ "GenSigSwitchedByIgnition" SG_ 2549940736 OBDC_Funktionaler_Req_All_Data 0;
BA_ "GenSigSendType" SG_ 2549875239 OBDC_Nightvision_Req_Data 3;
BA_ "GenSigFuncType" SG_ 2549875239 OBDC_Nightvision_Req_Data 9;
BA_ "GenSigSwitchedByIgnition" SG_ 2549875239 OBDC_Nightvision_Req_Data 0;
BA_ "GenSigSendType" SG_ 2550006311 OBDC_Nightvision_Resp_Data 3;
BA_ "GenSigFuncType" SG_ 2550006311 OBDC_Nightvision_Resp_Data 9;
BA_ "GenSigSendType" SG_ 2549875211 OBDC_RDK_Req_Data 3;
BA_ "GenSigFuncType" SG_ 2549875211 OBDC_RDK_Req_Data 9;
BA_ "GenSigSwitchedByIgnition" SG_ 2549875211 OBDC_RDK_Req_Data 0;
BA_ "GenSigSendType" SG_ 2550006283 OBDC_RDK_Resp_Data 3;
BA_ "GenSigFuncType" SG_ 2550006283 OBDC_RDK_Resp_Data 9;
BA_ "GenSigSwitchedByIgnition" SG_ 2550006283 OBDC_RDK_Resp_Data 0;
BA_ "GenSigSendType" SG_ 2549875305 OBDC_Rearview_Req_Data 3;
BA_ "GenSigFuncType" SG_ 2549875305 OBDC_Rearview_Req_Data 9;
BA_ "GenSigSwitchedByIgnition" SG_ 2549875305 OBDC_Rearview_Req_Data 0;
BA_ "GenSigSendType" SG_ 2550006377 OBDC_Rearview_Resp_Data 3;
BA_ "GenSigFuncType" SG_ 2550006377 OBDC_Rearview_Resp_Data 9;
BA_ "GenSigSwitchedByIgnition" SG_ 2550006377 OBDC_Rearview_Resp_Data 0;
BA_ "GenSigSendType" SG_ 2549875242 OBDC_SCR_Req_Data 3;
BA_ "GenSigFuncType" SG_ 2549875242 OBDC_SCR_Req_Data 9;
BA_ "GenSigSwitchedByIgnition" SG_ 2549875242 OBDC_SCR_Req_Data 0;
BA_ "GenSigSendType" SG_ 2550006314 OBDC_SCR_Resp_Data 3;
BA_ "GenSigFuncType" SG_ 2550006314 OBDC_SCR_Resp_Data 9;
BA_ "GenSigSwitchedByIgnition" SG_ 2550006314 OBDC_SCR_Resp_Data 0;
BA_ "GenSigSendType" SG_ 2549875300 OBDC_Soundaktor2_Req_Data 3;
BA_ "GenSigFuncType" SG_ 2549875300 OBDC_Soundaktor2_Req_Data 9;
BA_ "GenSigSwitchedByIgnition" SG_ 2549875300 OBDC_Soundaktor2_Req_Data 0;
BA_ "GenSigSendType" SG_ 2550006372 OBDC_Soundaktor2_Resp_Data 3;
BA_ "GenSigFuncType" SG_ 2550006372 OBDC_Soundaktor2_Resp_Data 9;
BA_ "GenSigSendType" SG_ 2549875228 OBDC_Soundaktor_Req_Data 3;
BA_ "GenSigFuncType" SG_ 2549875228 OBDC_Soundaktor_Req_Data 9;
BA_ "GenSigSwitchedByIgnition" SG_ 2549875228 OBDC_Soundaktor_Req_Data 0;
BA_ "GenSigSendType" SG_ 2550006300 OBDC_Soundaktor_Resp_Data 3;
BA_ "GenSigFuncType" SG_ 2550006300 OBDC_Soundaktor_Resp_Data 9;
BA_ "GenSigSendType" SG_ 2549875306 OBDC_STH_Req_Data 3;
BA_ "GenSigFuncType" SG_ 2549875306 OBDC_STH_Req_Data 9;
BA_ "GenSigSwitchedByIgnition" SG_ 2549875306 OBDC_STH_Req_Data 0;
BA_ "GenSigSendType" SG_ 2550006378 OBDC_STH_Resp_Data 3;
BA_ "GenSigFuncType" SG_ 2550006378 OBDC_STH_Resp_Data 9;
BA_ "GenSigSwitchedByIgnition" SG_ 2550006378 OBDC_STH_Resp_Data 0;
BA_ "GenSigSendType" SG_ 2549875338 OBDC_SWA_2_Req_Data 3;
BA_ "GenSigFuncType" SG_ 2549875338 OBDC_SWA_2_Req_Data 9;
BA_ "GenSigSwitchedByIgnition" SG_ 2549875338 OBDC_SWA_2_Req_Data 0;
BA_ "GenSigSendType" SG_ 2550006410 OBDC_SWA_2_Resp_Data 3;
BA_ "GenSigFuncType" SG_ 2550006410 OBDC_SWA_2_Resp_Data 9;
BA_ "GenSigSwitchedByIgnition" SG_ 2550006410 OBDC_SWA_2_Resp_Data 0;
BA_ "GenSigSendType" SG_ 2549875278 OBDC_SWA_Req_Data 3;
BA_ "GenSigFuncType" SG_ 2549875278 OBDC_SWA_Req_Data 9;
BA_ "GenSigSwitchedByIgnition" SG_ 2549875278 OBDC_SWA_Req_Data 0;
BA_ "GenSigSendType" SG_ 2550006350 OBDC_SWA_Resp_Data 3;
BA_ "GenSigFuncType" SG_ 2550006350 OBDC_SWA_Resp_Data 9;
BA_ "GenSigSwitchedByIgnition" SG_ 2550006350 OBDC_SWA_Resp_Data 0;
BA_ "GenSigSendType" SG_ 2589283656 ORU_Status 3;
BA_ "GenSigSwitchedByIgnition" SG_ 2589283656 ORU_Status 0;
BA_ "GenSigSendType" SG_ 2589283656 ORU_Warnung 3;
BA_ "GenSigSwitchedByIgnition" SG_ 2589283656 ORU_Warnung 0;
BA_ "GenSigSendType" SG_ 1175 PDC_Tonausgabe_Front 3;
BA_ "GenSigSendType" SG_ 1175 PDC_Tonausgabe_Heck 3;
BA_ "GenSigSendType" SG_ 1175 PH_Abschaltursache 3;
BA_ "GenSigSendType" SG_ 1175 PH_Anf_Audioabsenkung 3;
BA_ "GenSigSendType" SG_ 1175 PH_Anf_Verdeck 3;
BA_ "GenSigSendType" SG_ 1175 PH_defekt 3;
BA_ "GenSigSendType" SG_ 1175 PH_Display_Kundenwunsch 3;
BA_ "GenSigSendType" SG_ 1175 PH_Frequenz_hinten 3;
BA_ "GenSigSendType" SG_ 1175 PH_Frequenz_vorn 3;
BA_ "GenSigSendType" SG_ 1175 PH_gestoert 3;
BA_ "GenSigSendType" SG_ 1175 PH_Lautstaerke_hinten 3;
BA_ "GenSigSendType" SG_ 1175 PH_Lautstaerke_vorn 3;
BA_ "GenSigSendType" SG_ 1175 PH_nachtr_Stopp_Anf 3;
BA_ "GenSigSendType" SG_ 1175 PH_Opt_Anz_H_Hindernis 3;
BA_ "GenSigSendType" SG_ 1175 PH_Opt_Anz_V_Hindernis 3;
BA_ "GenSigSendType" SG_ 1175 PH_Opt_Anzeige_H_ein 3;
BA_ "GenSigSendType" SG_ 1175 PH_Opt_Anzeige_V_ein 3;
BA_ "GenSigSendType" SG_ 1175 PH_StartStopp_Info 3;
BA_ "GenSigSendType" SG_ 1175 PH_Stoermeldung 3;
BA_ "GenSigSendType" SG_ 1175 PH_Systemzustand 3;
BA_ "GenSigSendType" SG_ 1175 PH_Taster 3;
BA_ "Fehlerwert" SG_ 1175 PH_Taster 3;
BA_ "GenSigSendType" SG_ 1175 PH_Tongeber_H_aktiv 3;
BA_ "GenSigSendType" SG_ 1175 PH_Tongeber_H_verfuegbar 3;
BA_ "GenSigSendType" SG_ 1175 PH_Tongeber_mute 3;
BA_ "GenSigSendType" SG_ 1175 PH_Tongeber_V_aktiv 3;
BA_ "GenSigSendType" SG_ 1175 PH_Visualisierung 3;
BA_ "GenSigStartValue" SG_ 1175 PH_Visualisierung 6;
BA_ "Fehlerwert" SG_ 1175 PH_Visualisierung 7;
BA_ "GenSigSendType" SG_ 1175 PLA_Anf_Aufschaltung_RVC 3;
BA_ "GenSigSwitchedByIgnition" SG_ 1353 PL_Luecke_P0_x 0;
BA_ "GenSigSwitchedByIgnition" SG_ 1353 PL_Luecke_P0_y 0;
BA_ "GenSigSwitchedByIgnition" SG_ 1353 PL_Luecke_P2_x 0;
BA_ "GenSigSwitchedByIgnition" SG_ 1353 PL_Luecke_P2_y 0;
BA_ "GenSigSwitchedByIgnition" SG_ 1354 PL_Luecke_P1_x 0;
BA_ "GenSigSwitchedByIgnition" SG_ 1354 PL_Luecke_P1_y 0;
BA_ "GenSigSwitchedByIgnition" SG_ 1354 PL_Luecke_P3_x 0;
BA_ "GenSigSwitchedByIgnition" SG_ 1354 PL_Luecke_P3_y 0;
BA_ "GenSigSendType" SG_ 1355 BCM_WAH_Meldung 3;
BA_ "GenSigSendType" SG_ 1355 PDC_Charisma_FahrPr 3;
BA_ "GenSigSendType" SG_ 1355 PDC_Charisma_Status 3;
BA_ "GenSigSendType" SG_ 1355 PH_Aufschaltursache 3;
BA_ "GenSigSendType" SG_ 1355 PH_Ton_Ausgabe 3;
BA_ "Fehlerwert" SG_ 1355 PH_Ton_Ausgabe 7;
BA_ "GenSigSendType" SG_ 1355 PH_Ton_Lautstaerke 3;
BA_ "GenSigSendType" SG_ 1355 PH_Ton_Pausenlaenge 3;
BA_ "Fehlerwert" SG_ 1355 PH_Ton_Pausenlaenge 127;
BA_ "GenSigSendType" SG_ 1355 PH_Ton_Richtung 3;
BA_ "GenSigSendType" SG_ 1355 PH_Verschmutzungsmeldung 3;
BA_ "GenSigSendType" SG_ 2527679498 IAA_Active_User_ID 0;
BA_ "GenSigSwitchedByIgnition" SG_ 2527679498 IAA_Active_User_ID 0;
BA_ "GenSigSendType" SG_ 2527679498 IAA_Identified_User_ID 0;
BA_ "GenSigSwitchedByIgnition" SG_ 2527679498 IAA_Identified_User_ID 0;
BA_ "GenSigSendType" SG_ 2527679498 IAA_PSO_wake_up 0;
BA_ "GenSigSwitchedByIgnition" SG_ 2527679498 IAA_PSO_wake_up 0;
BA_ "GenSigActiveRepetitions" SG_ 2527679498 Perso_Aktiv 3;
BA_ "GenSigSendType" SG_ 2527679498 Perso_Aktiv 4;
BA_ "GenSigSwitchedByIgnition" SG_ 2527679498 Perso_Aktiv 0;
BA_ "GenSigActiveRepetitions" SG_ 2527679498 Perso_Bedienstelle 3;
BA_ "GenSigSendType" SG_ 2527679498 Perso_Bedienstelle 4;
BA_ "GenSigSwitchedByIgnition" SG_ 2527679498 Perso_Bedienstelle 0;
BA_ "GenSigActiveRepetitions" SG_ 2527679498 Perso_Fahrernummer 3;
BA_ "GenSigSendType" SG_ 2527679498 Perso_Fahrernummer 4;
BA_ "GenSigSwitchedByIgnition" SG_ 2527679498 Perso_Fahrernummer 0;
BA_ "GenSigActiveRepetitions" SG_ 2527679498 Perso_Freigabe_Verstellung 3;
BA_ "GenSigSendType" SG_ 2527679498 Perso_Freigabe_Verstellung 4;
BA_ "GenSigSwitchedByIgnition" SG_ 2527679498 Perso_Freigabe_Verstellung 0;
BA_ "GenSigActiveRepetitions" SG_ 2527679498 Perso_Kontonummer 3;
BA_ "GenSigSendType" SG_ 2527679498 Perso_Kontonummer 4;
BA_ "GenSigSwitchedByIgnition" SG_ 2527679498 Perso_Kontonummer 0;
BA_ "GenSigActiveRepetitions" SG_ 2527679498 Perso_Schreibschutz 3;
BA_ "GenSigSendType" SG_ 2527679498 Perso_Schreibschutz 4;
BA_ "GenSigSwitchedByIgnition" SG_ 2527679498 Perso_Schreibschutz 0;
BA_ "GenSigSendType" SG_ 2527679498 Perso_Status 1;
BA_ "GenSigSwitchedByIgnition" SG_ 2527679498 Perso_Status 0;
BA_ "GenSigActiveRepetitions" SG_ 2527679498 Perso_Steuerung 3;
BA_ "GenSigSendType" SG_ 2527679498 Perso_Steuerung 4;
BA_ "GenSigSwitchedByIgnition" SG_ 2527679498 Perso_Steuerung 0;
BA_ "GenSigActiveRepetitions" SG_ 2527679498 Perso_Steuerungsparameter 3;
BA_ "GenSigSendType" SG_ 2527679498 Perso_Steuerungsparameter 4;
BA_ "GenSigSwitchedByIgnition" SG_ 2527679498 Perso_Steuerungsparameter 0;
BA_ "GenSigSendType" SG_ 319 PreCrash_02_BZ 0;
BA_ "GenSigFuncType" SG_ 319 PreCrash_02_BZ 1;
BA_ "GenSigSendType" SG_ 319 PreCrash_02_CRC 0;
BA_ "GenSigFuncType" SG_ 319 PreCrash_02_CRC 2;
BA_ "GenSigSendType" SG_ 319 PreCrash_Anforderung_AFR 3;
BA_ "GenSigStartValue" SG_ 319 PreCrash_Anforderung_AFR 7;
BA_ "GenSigSwitchedByIgnition" SG_ 319 PreCrash_Anforderung_AFR 0;
BA_ "GenSigSendType" SG_ 319 PreCrash_BFS_KSV_verfahren 3;
BA_ "GenSigSwitchedByIgnition" SG_ 319 PreCrash_BFS_KSV_verfahren 0;
BA_ "GenSigSendType" SG_ 319 PreCrash_BFS_Pneumatik_ansteuern 3;
BA_ "GenSigSwitchedByIgnition" SG_ 319 PreCrash_BFS_Pneumatik_ansteuern 0;
BA_ "GenSigSendType" SG_ 319 PreCrash_BFS_Sitzlehne_verfahren 3;
BA_ "GenSigSwitchedByIgnition" SG_ 319 PreCrash_BFS_Sitzlehne_verfahren 0;
BA_ "GenSigSendType" SG_ 319 PreCrash_Blinken 3;
BA_ "GenSigSendType" SG_ 319 PreCrash_Charisma_FahrPr 0;
BA_ "GenSigSendType" SG_ 319 PreCrash_Charisma_Status 0;
BA_ "GenSigSendType" SG_ 319 PreCrash_Fenster_schliessen 3;
BA_ "GenSigSendType" SG_ 319 PreCrash_Fo_KSV_verfahren 3;
BA_ "GenSigSwitchedByIgnition" SG_ 319 PreCrash_Fo_KSV_verfahren 0;
BA_ "GenSigSendType" SG_ 319 PreCrash_Fo_Pneumatik_ansteuern 3;
BA_ "GenSigSwitchedByIgnition" SG_ 319 PreCrash_Fo_Pneumatik_ansteuern 0;
BA_ "GenSigSendType" SG_ 319 PreCrash_Fo_Sitzlehne_verfahren 3;
BA_ "GenSigSwitchedByIgnition" SG_ 319 PreCrash_Fo_Sitzlehne_verfahren 0;
BA_ "GenSigSendType" SG_ 319 PreCrash_FS_KSV_verfahren 3;
BA_ "GenSigSwitchedByIgnition" SG_ 319 PreCrash_FS_KSV_verfahren 0;
BA_ "GenSigSendType" SG_ 319 PreCrash_FS_Pneumatik_ansteuern 3;
BA_ "GenSigSwitchedByIgnition" SG_ 319 PreCrash_FS_Pneumatik_ansteuern 0;
BA_ "GenSigSendType" SG_ 319 PreCrash_FS_Sitzlehne_verfahren 3;
BA_ "GenSigSwitchedByIgnition" SG_ 319 PreCrash_FS_Sitzlehne_verfahren 0;
BA_ "GenSigSendType" SG_ 319 PreCrash_Schiebedach_schliessen 3;
BA_ "GenSigSendType" SG_ 319 PreCrash_Tueren_Verriegeln 3;
BA_ "GenSigSwitchedByIgnition" SG_ 319 PreCrash_Tueren_Verriegeln 0;
BA_ "GenSigSendType" SG_ 319 SC_PreCrash_LED 3;
BA_ "GenSigSwitchedByIgnition" SG_ 319 SC_PreCrash_LED 0;
BA_ "GenSigSendType" SG_ 319 SC_PreCrash_Texte 3;
BA_ "GenSigSwitchedByIgnition" SG_ 319 SC_PreCrash_Texte 0;
BA_ "GenSigSendType" SG_ 319 SC_PreCrash_Warnung 3;
BA_ "GenSigSwitchedByIgnition" SG_ 319 SC_PreCrash_Warnung 0;
BA_ "GenSigSendType" SG_ 319 SC_PreSense_FCWP 3;
BA_ "GenSigSwitchedByIgnition" SG_ 319 SC_PreSense_FCWP 0;
BA_ "GenSigSendType" SG_ 1122 PSD_Abzweigerichtung 0;
BA_ "GenSigSwitchedByIgnition" SG_ 1122 PSD_Abzweigerichtung 0;
BA_ "GenSigSendType" SG_ 1122 PSD_Abzweigewinkel 0;
BA_ "GenSigSwitchedByIgnition" SG_ 1122 PSD_Abzweigewinkel 0;
BA_ "GenSigSendType" SG_ 1122 PSD_ADAS_Qualitaet 0;
BA_ "GenSigSendType" SG_ 1122 PSD_Anfangskruemmung 0;
BA_ "GenSigSwitchedByIgnition" SG_ 1122 PSD_Anfangskruemmung 0;
BA_ "GenSigSendType" SG_ 1122 PSD_Anfangskruemmung_Vorz 0;
BA_ "GenSigSwitchedByIgnition" SG_ 1122 PSD_Anfangskruemmung_Vorz 0;
BA_ "GenSigSendType" SG_ 1122 PSD_Bebauung 0;
BA_ "GenSigSendType" SG_ 1122 PSD_Endkruemmung 0;
BA_ "GenSigSendType" SG_ 1122 PSD_Endkruemmung_Vorz 0;
BA_ "GenSigSendType" SG_ 1122 PSD_Fahrspuren_Anzahl 0;
BA_ "GenSigStartValue" SG_ 1122 PSD_Fahrspuren_Anzahl 1;
BA_ "GenSigSwitchedByIgnition" SG_ 1122 PSD_Fahrspuren_Anzahl 0;
BA_ "GenSigSendType" SG_ 1122 PSD_Geradester_Pfad 0;
BA_ "GenSigSendType" SG_ 1122 PSD_Idenditaets_ID 0;
BA_ "Fehlerwert" SG_ 1122 PSD_Idenditaets_ID 1;
BA_ "GenSigSendType" SG_ 1122 PSD_Rampe 0;
BA_ "GenSigSendType" SG_ 1122 PSD_Segment_ID 0;
BA_ "GenSigSendType" SG_ 1122 PSD_Segment_Komplett 0;
BA_ "GenSigSwitchedByIgnition" SG_ 1122 PSD_Segment_Komplett 0;
BA_ "GenSigSendType" SG_ 1122 PSD_Segmentlaenge 0;
BA_ "GenSigSendType" SG_ 1122 PSD_Strassenkategorie 0;
BA_ "GenSigStartValue" SG_ 1122 PSD_Strassenkategorie 7;
BA_ "GenSigSwitchedByIgnition" SG_ 1122 PSD_Strassenkategorie 0;
BA_ "GenSigSendType" SG_ 1122 PSD_Vorgaenger_Segment_ID 0;
BA_ "GenSigSendType" SG_ 1122 PSD_wahrscheinlichster_Pfad 0;
BA_ "GenSigSendType" SG_ 1123 PSD_Attribut_1_ID 0;
BA_ "GenSigSendType" SG_ 1123 PSD_Attribut_1_Offset 0;
BA_ "GenSigSendType" SG_ 1123 PSD_Attribut_1_Wert 0;
BA_ "GenSigSendType" SG_ 1123 PSD_Attribut_2_ID 0;
BA_ "GenSigSendType" SG_ 1123 PSD_Attribut_2_Offset 0;
BA_ "GenSigSendType" SG_ 1123 PSD_Attribut_2_Wert 0;
BA_ "GenSigSendType" SG_ 1123 PSD_Attribut_Segment_ID_05 0;
BA_ "Fehlerwert" SG_ 1123 PSD_Attribut_Segment_ID_05 1;
BA_ "GenSigSendType" SG_ 1123 PSD_Attribute_Komplett_05 0;
BA_ "GenSigSendType" SG_ 1123 PSD_Pos_Fahrspur 0;
BA_ "GenSigSendType" SG_ 1123 PSD_Pos_Fehler_Laengsrichtung 0;
BA_ "GenSigSendType" SG_ 1123 PSD_Pos_Inhibitzeit 0;
BA_ "GenSigSendType" SG_ 1123 PSD_Pos_Segment_ID 0;
BA_ "GenSigSendType" SG_ 1123 PSD_Pos_Segmentlaenge 0;
BA_ "GenSigSendType" SG_ 1123 PSD_Pos_Standort_Eindeutig 0;
BA_ "GenSigSwitchedByIgnition" SG_ 1123 PSD_Pos_Standort_Eindeutig 0;
BA_ "GenSigSendType" SG_ 1124 PSD_06_Mux 0;
BA_ "NWM-WakeupAllowed" SG_ 1124 PSD_06_Mux 1;
BA_ "GenSigSwitchedByIgnition" SG_ 1124 PSD_06_Mux 0;
BA_ "Fehlerwert" SG_ 1124 PSD_Attribut_Segment_ID 1;
BA_ "GenSigSwitchedByIgnition" SG_ 1124 PSD_Attribute_Komplett_06 0;
BA_ "GenSigStartValue" SG_ 1124 PSD_Ges_Typ 3;
BA_ "GenSigSwitchedByIgnition" SG_ 1124 PSD_Ges_Typ 0;
BA_ "GenSigSwitchedByIgnition" SG_ 1124 PSD_Steigung_1_Attribute_kompl 0;
BA_ "Fehlerwert" SG_ 1124 PSD_Steigung_1_Segment_ID 1;
BA_ "GenSigSwitchedByIgnition" SG_ 1124 PSD_Steigung_2_Attribute_kompl 0;
BA_ "Fehlerwert" SG_ 1124 PSD_Steigung_2_Segment_ID 1;
BA_REL_ "GenSigTimeoutTime" BU_SG_REL_ E_Sound SG_ 2589283656 ORU_Status 5000;
BA_REL_ "GenSigTimeoutTime" BU_SG_REL_ FLA SG_ 1122 PSD_Segment_ID 1500;
BA_REL_ "GenSigTimeoutTime" BU_SG_REL_ FLA SG_ 1122 PSD_Vorgaenger_Segment_ID 1500;
BA_REL_ "GenSigTimeoutTime" BU_SG_REL_ FLA SG_ 1122 PSD_Segmentlaenge 1500;
BA_REL_ "GenSigTimeoutTime" BU_SG_REL_ FLA SG_ 1122 PSD_Strassenkategorie 1500;
BA_REL_ "GenSigTimeoutTime" BU_SG_REL_ FLA SG_ 1122 PSD_Endkruemmung 1500;
BA_REL_ "GenSigTimeoutTime" BU_SG_REL_ FLA SG_ 1122 PSD_Endkruemmung_Vorz 1500;
BA_REL_ "GenSigTimeoutTime" BU_SG_REL_ FLA SG_ 1122 PSD_Idenditaets_ID 1500;
BA_REL_ "GenSigTimeoutTime" BU_SG_REL_ FLA SG_ 1122 PSD_ADAS_Qualitaet 1500;
BA_REL_ "GenSigTimeoutTime" BU_SG_REL_ FLA SG_ 1122 PSD_wahrscheinlichster_Pfad 1500;
BA_REL_ "GenSigTimeoutTime" BU_SG_REL_ FLA SG_ 1122 PSD_Geradester_Pfad 1500;
BA_REL_ "GenSigTimeoutTime" BU_SG_REL_ FLA SG_ 1122 PSD_Fahrspuren_Anzahl 1500;
BA_REL_ "GenSigTimeoutTime" BU_SG_REL_ FLA SG_ 1122 PSD_Bebauung 1500;
BA_REL_ "GenSigTimeoutTime" BU_SG_REL_ FLA SG_ 1122 PSD_Segment_Komplett 1500;
BA_REL_ "GenSigTimeoutTime" BU_SG_REL_ FLA SG_ 1122 PSD_Rampe 1500;
BA_REL_ "GenSigTimeoutTime" BU_SG_REL_ FLA SG_ 1122 PSD_Anfangskruemmung 1500;
BA_REL_ "GenSigTimeoutTime" BU_SG_REL_ FLA SG_ 1122 PSD_Anfangskruemmung_Vorz 1500;
BA_REL_ "GenSigTimeoutTime" BU_SG_REL_ FLA SG_ 1122 PSD_Abzweigewinkel 1500;
BA_REL_ "GenSigTimeoutTime" BU_SG_REL_ FLA SG_ 1123 PSD_Pos_Segment_ID 1500;
BA_REL_ "GenSigTimeoutTime" BU_SG_REL_ FLA SG_ 1123 PSD_Pos_Segmentlaenge 1500;
BA_REL_ "GenSigTimeoutTime" BU_SG_REL_ FLA SG_ 1123 PSD_Pos_Inhibitzeit 1500;
BA_REL_ "GenSigTimeoutTime" BU_SG_REL_ FLA SG_ 1123 PSD_Pos_Standort_Eindeutig 1500;
BA_REL_ "GenSigTimeoutTime" BU_SG_REL_ FLA SG_ 1123 PSD_Pos_Fehler_Laengsrichtung 1500;
BA_REL_ "GenSigTimeoutTime" BU_SG_REL_ FLA SG_ 1123 PSD_Pos_Fahrspur 1500;
BA_REL_ "GenSigTimeoutTime" BU_SG_REL_ FLA SG_ 1123 PSD_Attribut_Segment_ID_05 1500;
BA_REL_ "GenSigTimeoutTime" BU_SG_REL_ FLA SG_ 1123 PSD_Attribut_1_Wert 1500;
BA_REL_ "GenSigTimeoutTime" BU_SG_REL_ FLA SG_ 1123 PSD_Attribut_1_Offset 1500;
BA_REL_ "GenSigTimeoutTime" BU_SG_REL_ FLA SG_ 1123 PSD_Attribut_2_ID 1500;
BA_REL_ "GenSigTimeoutTime" BU_SG_REL_ FLA SG_ 1123 PSD_Attribut_2_Wert 1500;
BA_REL_ "GenSigTimeoutTime" BU_SG_REL_ FLA SG_ 1123 PSD_Attribut_2_Offset 1500;
BA_REL_ "GenSigTimeoutTime" BU_SG_REL_ FLA SG_ 1123 PSD_Attribute_Komplett_05 1500;
BA_REL_ "GenSigTimeoutTime" BU_SG_REL_ FLA SG_ 1124 PSD_Sys_Segment_ID 1500;
BA_REL_ "GenSigTimeoutTime" BU_SG_REL_ FLA SG_ 1124 PSD_Attribut_Segment_ID 1500;
BA_REL_ "GenSigTimeoutTime" BU_SG_REL_ FLA SG_ 1124 PSD_Ges_Segment_ID 1500;
BA_REL_ "GenSigTimeoutTime" BU_SG_REL_ FLA SG_ 1124 PSD_Baum_Laenge_VZ 1500;
BA_REL_ "GenSigTimeoutTime" BU_SG_REL_ FLA SG_ 1124 PSD_Steigung_1_Segment_ID 1500;
BA_REL_ "GenSigTimeoutTime" BU_SG_REL_ FLA SG_ 1124 PSD_Baum_Laenge 1500;
BA_REL_ "GenSigTimeoutTime" BU_SG_REL_ FLA SG_ 1124 PSD_Sys_Laendercode 1500;
BA_REL_ "GenSigTimeoutTime" BU_SG_REL_ FLA SG_ 1124 PSD_Attribut_3_ID 1500;
BA_REL_ "GenSigTimeoutTime" BU_SG_REL_ FLA SG_ 1124 PSD_Ges_Offset 1500;
BA_REL_ "GenSigTimeoutTime" BU_SG_REL_ FLA SG_ 1124 PSD_Steigung_1_A_Steigung 1500;
BA_REL_ "GenSigTimeoutTime" BU_SG_REL_ FLA SG_ 1124 PSD_Attribut_3_Offset 1500;
BA_REL_ "GenSigTimeoutTime" BU_SG_REL_ FLA SG_ 1124 PSD_Ges_Geschwindigkeit 1500;
BA_REL_ "GenSigTimeoutTime" BU_SG_REL_ FLA SG_ 1124 PSD_Steigung_1_A_Vorz 1500;
BA_REL_ "GenSigTimeoutTime" BU_SG_REL_ FLA SG_ 1124 PSD_Sys_Geschwindigkeit_Einheit 1500;
BA_REL_ "GenSigTimeoutTime" BU_SG_REL_ FLA SG_ 1124 PSD_Steigung_1_A_Offset 1500;
BA_REL_ "GenSigTimeoutTime" BU_SG_REL_ FLA SG_ 1124 PSD_Sys_Verkehrsrichtung 1500;
BA_REL_ "GenSigTimeoutTime" BU_SG_REL_ FLA SG_ 1124 PSD_Sys_Geometrieguete 1500;
BA_REL_ "GenSigTimeoutTime" BU_SG_REL_ FLA SG_ 1124 PSD_Sys_Mapmatchingguete 1500;
BA_REL_ "GenSigTimeoutTime" BU_SG_REL_ FLA SG_ 1124 PSD_Attribut_3_Wert 1500;
BA_REL_ "GenSigTimeoutTime" BU_SG_REL_ FLA SG_ 1124 PSD_Ges_Typ 1500;
BA_REL_ "GenSigTimeoutTime" BU_SG_REL_ FLA SG_ 1124 PSD_Sys_Alter_Karte 1500;
BA_REL_ "GenSigTimeoutTime" BU_SG_REL_ FLA SG_ 1124 PSD_Ges_Spur_Geschw_Begrenzung 1500;
BA_REL_ "GenSigTimeoutTime" BU_SG_REL_ FLA SG_ 1124 PSD_Steigung_1_B_Steigung 1500;
BA_REL_ "GenSigTimeoutTime" BU_SG_REL_ FLA SG_ 1124 PSD_Attribut_4_ID 1500;
BA_REL_ "GenSigTimeoutTime" BU_SG_REL_ FLA SG_ 1124 PSD_Sys_Zielfuehrung 1500;
BA_REL_ "GenSigTimeoutTime" BU_SG_REL_ FLA SG_ 1124 PSD_Sys_US_State 1500;
BA_REL_ "GenSigTimeoutTime" BU_SG_REL_ FLA SG_ 1124 PSD_Ges_Geschwindigkeit_Gespann 1500;
BA_REL_ "GenSigTimeoutTime" BU_SG_REL_ FLA SG_ 1124 PSD_Baum_Breite_VZ 1500;
BA_REL_ "GenSigTimeoutTime" BU_SG_REL_ FLA SG_ 1124 PSD_Attribut_4_Wert 1500;
BA_REL_ "GenSigTimeoutTime" BU_SG_REL_ FLA SG_ 1124 PSD_Baum_Breite 1500;
BA_REL_ "GenSigTimeoutTime" BU_SG_REL_ FLA SG_ 1124 PSD_Ges_Geschwindigkeit_Witter 1500;
BA_REL_ "GenSigTimeoutTime" BU_SG_REL_ FLA SG_ 1124 PSD_Steigung_1_B_Vorz 1500;
BA_REL_ "GenSigTimeoutTime" BU_SG_REL_ FLA SG_ 1124 PSD_Steigung_1_B_Offset 1500;
BA_REL_ "GenSigTimeoutTime" BU_SG_REL_ FLA SG_ 1124 PSD_Sys_Quali_Geometrien 1500;
BA_REL_ "GenSigTimeoutTime" BU_SG_REL_ FLA SG_ 1124 PSD_Ges_Geschwindigkeit_Tag_Anf 1500;
BA_REL_ "GenSigTimeoutTime" BU_SG_REL_ FLA SG_ 1124 PSD_Attribut_4_Offset 1500;
BA_REL_ "GenSigTimeoutTime" BU_SG_REL_ FLA SG_ 1124 PSD_Sys_Quali_Ortsinfo 1500;
BA_REL_ "GenSigTimeoutTime" BU_SG_REL_ FLA SG_ 1124 PSD_Ges_Geschwindigkeit_Tag_Ende 1500;
BA_REL_ "GenSigTimeoutTime" BU_SG_REL_ FLA SG_ 1124 PSD_Sys_Quali_verfuegbar 1500;
BA_REL_ "GenSigTimeoutTime" BU_SG_REL_ FLA SG_ 1124 PSD_Sys_Zielfuehrung_geaendert 1500;
BA_REL_ "GenSigTimeoutTime" BU_SG_REL_ FLA SG_ 1124 PSD_Ges_Geschwindigkeit_Std_Anf 1500;
BA_REL_ "GenSigTimeoutTime" BU_SG_REL_ FLA SG_ 1124 PSD_Steigung_1_Attribute_kompl 1500;
BA_REL_ "GenSigTimeoutTime" BU_SG_REL_ FLA SG_ 1124 PSD_Sys_Geometrieguete_erweitert 1500;
BA_REL_ "GenSigTimeoutTime" BU_SG_REL_ FLA SG_ 1124 PSD_Steigung_2_Segment_ID 1500;
BA_REL_ "GenSigTimeoutTime" BU_SG_REL_ FLA SG_ 1124 PSD_Attribut_5_ID 1500;
BA_REL_ "GenSigTimeoutTime" BU_SG_REL_ FLA SG_ 1124 PSD_Ges_Geschwindigkeit_Std_Ende 1500;
BA_REL_ "GenSigTimeoutTime" BU_SG_REL_ FLA SG_ 1124 PSD_Attribut_5_Offset 1500;
BA_REL_ "GenSigTimeoutTime" BU_SG_REL_ FLA SG_ 1124 PSD_Steigung_2_Steigung 1500;
BA_REL_ "GenSigTimeoutTime" BU_SG_REL_ FLA SG_ 1124 PSD_Sys_Quali_sonstige_Attribute 1500;
BA_REL_ "GenSigTimeoutTime" BU_SG_REL_ FLA SG_ 1124 PSD_Ges_Ueberholverbot 1500;
BA_REL_ "GenSigTimeoutTime" BU_SG_REL_ FLA SG_ 1124 PSD_Sys_Quali_Steigungen 1500;
BA_REL_ "GenSigTimeoutTime" BU_SG_REL_ FLA SG_ 1124 PSD_Ges_Wechselverkehrszeichen 1500;
BA_REL_ "GenSigTimeoutTime" BU_SG_REL_ FLA SG_ 1124 PSD_Attribut_5_Wert 1500;
BA_REL_ "GenSigTimeoutTime" BU_SG_REL_ FLA SG_ 1124 PSD_Steigung_2_Vorz 1500;
BA_REL_ "GenSigTimeoutTime" BU_SG_REL_ FLA SG_ 1124 PSD_Sys_Quali_Strassenkennz 1500;
BA_REL_ "GenSigTimeoutTime" BU_SG_REL_ FLA SG_ 1124 PSD_Wechselverkehrszeichen_Typ 1500;
BA_REL_ "GenSigTimeoutTime" BU_SG_REL_ FLA SG_ 1124 PSD_Baum_Ausrichtung 1500;
BA_REL_ "GenSigTimeoutTime" BU_SG_REL_ FLA SG_ 1124 PSD_Steigung_2_Offset 1500;
BA_REL_ "GenSigTimeoutTime" BU_SG_REL_ FLA SG_ 1124 PSD_Ges_Gesetzlich_Kategorie 1500;
BA_REL_ "GenSigTimeoutTime" BU_SG_REL_ FLA SG_ 1124 PSD_Sys_Quali_Tempolimits 1500;
BA_REL_ "GenSigTimeoutTime" BU_SG_REL_ FLA SG_ 1124 PSD_Attribute_Komplett_06 1500;
BA_REL_ "GenSigTimeoutTime" BU_SG_REL_ FLA SG_ 1124 PSD_Ges_Gesetzlich_Zusatz 1500;
BA_REL_ "GenSigTimeoutTime" BU_SG_REL_ FLA SG_ 1124 PSD_Sys_Quali_Vorfahrtsregelung 1500;
BA_REL_ "GenSigTimeoutTime" BU_SG_REL_ FLA SG_ 1124 PSD_Ges_Verkehrszeichen_Quelle 1500;
BA_REL_ "GenSigTimeoutTime" BU_SG_REL_ FLA SG_ 1124 PSD_Steigung_2_Attribute_kompl 1500;
BA_REL_ "GenSigTimeoutTime" BU_SG_REL_ FLA SG_ 1124 PSD_Ges_Attribute_Komplett 1500;
BA_REL_ "GenSigTimeoutTime" BU_SG_REL_ Gateway SG_ 2600468585 NM_Rearview_SNI 2000;
BA_REL_ "GenSigTimeoutTime" BU_SG_REL_ Gateway SG_ 2600468585 NM_Rearview_CBV_AWB 2000;
BA_REL_ "GenSigTimeoutTime" BU_SG_REL_ Gateway SG_ 2600468585 NM_Rearview_CBV_CRI 2000;
BA_REL_ "GenSigTimeoutTime" BU_SG_REL_ Gateway SG_ 2600468585 NM_Rearview_Car_Wakeup 2000;
BA_REL_ "GenSigTimeoutTime" BU_SG_REL_ Gateway SG_ 2600468585 NM_RearView_CAB 2000;
BA_REL_ "GenSigTimeoutTime" BU_SG_REL_ Gateway SG_ 2600468522 NM_SCR_SNI 2000;
BA_REL_ "GenSigTimeoutTime" BU_SG_REL_ Gateway SG_ 2600468522 NM_SCR_CBV_AWB 2000;
BA_REL_ "GenSigTimeoutTime" BU_SG_REL_ Gateway SG_ 2600468522 NM_SCR_CBV_CRI 2000;
BA_REL_ "GenSigTimeoutTime" BU_SG_REL_ Gateway SG_ 2600468522 NM_SCR_Car_Wakeup 2000;
BA_REL_ "GenSigTimeoutTime" BU_SG_REL_ Gateway SG_ 2600468522 NM_SCR_CAB 2000;
BA_REL_ "GenSigTimeoutTime" BU_SG_REL_ Gateway SG_ 2600468586 NM_STH_SNI 2000;
BA_REL_ "GenSigTimeoutTime" BU_SG_REL_ Gateway SG_ 2600468586 NM_STH_CBV_AWB 2000;
BA_REL_ "GenSigTimeoutTime" BU_SG_REL_ Gateway SG_ 2600468586 NM_STH_CBV_CRI 2000;
BA_REL_ "GenSigTimeoutTime" BU_SG_REL_ Gateway SG_ 2600468586 NM_STH_Car_Wakeup 2000;
BA_REL_ "GenSigTimeoutTime" BU_SG_REL_ Gateway SG_ 2600468586 NM_STH_CAB 2000;
BA_REL_ "GenSigTimeoutTime" BU_SG_REL_ Gateway SG_ 2600468558 NM_SWA_SNI 2000;
BA_REL_ "GenSigTimeoutTime" BU_SG_REL_ Gateway SG_ 2600468558 NM_SWA_CBV_AWB 2000;
BA_REL_ "GenSigTimeoutTime" BU_SG_REL_ Gateway SG_ 2600468558 NM_SWA_CBV_CRI 2000;
BA_REL_ "GenSigTimeoutTime" BU_SG_REL_ Gateway SG_ 2600468558 NM_SWA_Car_Wakeup 2000;
BA_REL_ "GenSigTimeoutTime" BU_SG_REL_ Gateway SG_ 2600468558 NM_SWA_CAB 2000;
BA_REL_ "GenSigTimeoutTime" BU_SG_REL_ Gateway SG_ 2600468618 NM_SWA_Slave_SNI 2000;
BA_REL_ "GenSigTimeoutTime" BU_SG_REL_ Gateway SG_ 2600468618 NM_SWA_Slave_CBV_AWB 2000;
BA_REL_ "GenSigTimeoutTime" BU_SG_REL_ Gateway SG_ 2600468618 NM_SWA_Slave_CBV_CRI 2000;
BA_REL_ "GenSigTimeoutTime" BU_SG_REL_ Gateway SG_ 2600468618 NM_SWA_Slave_Car_Wakeup 2000;
BA_REL_ "GenSigTimeoutTime" BU_SG_REL_ Gateway SG_ 2600468618 NM_SWA_Slave_CAB 2000;
BA_REL_ "GenSigTimeoutTime" BU_SG_REL_ Gateway_PAG SG_ 2600468585 NM_Rearview_SNI 2000;
BA_REL_ "GenSigTimeoutTime" BU_SG_REL_ Gateway_PAG SG_ 2600468585 NM_Rearview_CBV_AWB 2000;
BA_REL_ "GenSigTimeoutTime" BU_SG_REL_ Gateway_PAG SG_ 2600468585 NM_Rearview_CBV_CRI 2000;
BA_REL_ "GenSigTimeoutTime" BU_SG_REL_ Gateway_PAG SG_ 2600468585 NM_RearView_CAB 2000;
BA_REL_ "GenSigTimeoutTime" BU_SG_REL_ Gateway_PAG SG_ 2600468522 NM_SCR_SNI 2000;
BA_REL_ "GenSigTimeoutTime" BU_SG_REL_ Gateway_PAG SG_ 2600468522 NM_SCR_CBV_AWB 2000;
BA_REL_ "GenSigTimeoutTime" BU_SG_REL_ Gateway_PAG SG_ 2600468522 NM_SCR_CBV_CRI 2000;
BA_REL_ "GenSigTimeoutTime" BU_SG_REL_ Gateway_PAG SG_ 2600468522 NM_SCR_Car_Wakeup 2000;
BA_REL_ "GenSigTimeoutTime" BU_SG_REL_ Gateway_PAG SG_ 2600468522 NM_SCR_CAB 2000;
BA_REL_ "GenSigTimeoutTime" BU_SG_REL_ Gateway_PAG SG_ 2600468586 NM_STH_SNI 2000;
BA_REL_ "GenSigTimeoutTime" BU_SG_REL_ Gateway_PAG SG_ 2600468586 NM_STH_CBV_AWB 2000;
BA_REL_ "GenSigTimeoutTime" BU_SG_REL_ Gateway_PAG SG_ 2600468586 NM_STH_CBV_CRI 2000;
BA_REL_ "GenSigTimeoutTime" BU_SG_REL_ Gateway_PAG SG_ 2600468586 NM_STH_Car_Wakeup 2000;
BA_REL_ "GenSigTimeoutTime" BU_SG_REL_ Gateway_PAG SG_ 2600468586 NM_STH_CAB 2000;
BA_REL_ "GenSigTimeoutTime" BU_SG_REL_ Gateway_PAG SG_ 2600468558 NM_SWA_SNI 2000;
BA_REL_ "GenSigTimeoutTime" BU_SG_REL_ Gateway_PAG SG_ 2600468558 NM_SWA_CBV_AWB 2000;
BA_REL_ "GenSigTimeoutTime" BU_SG_REL_ Gateway_PAG SG_ 2600468558 NM_SWA_CBV_CRI 2000;
BA_REL_ "GenSigTimeoutTime" BU_SG_REL_ Gateway_PAG SG_ 2600468558 NM_SWA_Car_Wakeup 2000;
BA_REL_ "GenSigTimeoutTime" BU_SG_REL_ Gateway_PAG SG_ 2600468558 NM_SWA_CAB 2000;
BA_REL_ "GenSigTimeoutTime" BU_SG_REL_ Gateway_PAG SG_ 2600468618 NM_SWA_Slave_SNI 2000;
BA_REL_ "GenSigTimeoutTime" BU_SG_REL_ Gateway_PAG SG_ 2600468618 NM_SWA_Slave_CBV_AWB 2000;
BA_REL_ "GenSigTimeoutTime" BU_SG_REL_ Gateway_PAG SG_ 2600468618 NM_SWA_Slave_CBV_CRI 2000;
BA_REL_ "GenSigTimeoutTime" BU_SG_REL_ Gateway_PAG SG_ 2600468618 NM_SWA_Slave_CAB 2000;
BA_REL_ "GenSigTimeoutTime" BU_SG_REL_ ISE SG_ 2589283656 ORU_Status 5000;
BA_REL_ "GenSigTimeoutTime" BU_SG_REL_ NightVision SG_ 2600468585 NM_Rearview_SNI 2000;
BA_REL_ "GenSigTimeoutTime" BU_SG_REL_ NightVision SG_ 2600468585 NM_Rearview_CBV_CRI 2000;
BA_REL_ "GenSigTimeoutTime" BU_SG_REL_ NightVision SG_ 2600468585 NM_RearView_CAB 2000;
BA_REL_ "GenSigTimeoutTime" BU_SG_REL_ NightVision SG_ 2600468522 NM_SCR_SNI 2000;
BA_REL_ "GenSigTimeoutTime" BU_SG_REL_ NightVision SG_ 2600468522 NM_SCR_CBV_CRI 2000;
BA_REL_ "GenSigTimeoutTime" BU_SG_REL_ NightVision SG_ 2600468522 NM_SCR_CAB 2000;
BA_REL_ "GenSigTimeoutTime" BU_SG_REL_ NightVision SG_ 2600468586 NM_STH_SNI 2000;
BA_REL_ "GenSigTimeoutTime" BU_SG_REL_ NightVision SG_ 2600468586 NM_STH_CBV_CRI 2000;
BA_REL_ "GenSigTimeoutTime" BU_SG_REL_ NightVision SG_ 2600468586 NM_STH_CAB 2000;
BA_REL_ "GenSigTimeoutTime" BU_SG_REL_ NightVision SG_ 2600468558 NM_SWA_SNI 2000;
BA_REL_ "GenSigTimeoutTime" BU_SG_REL_ NightVision SG_ 2600468558 NM_SWA_CBV_CRI 2000;
BA_REL_ "GenSigTimeoutTime" BU_SG_REL_ NightVision SG_ 2600468558 NM_SWA_CAB 2000;
BA_REL_ "GenSigTimeoutTime" BU_SG_REL_ NightVision SG_ 2600468618 NM_SWA_Slave_SNI 2000;
BA_REL_ "GenSigTimeoutTime" BU_SG_REL_ NightVision SG_ 2600468618 NM_SWA_Slave_CBV_CRI 2000;
BA_REL_ "GenSigTimeoutTime" BU_SG_REL_ NightVision SG_ 2600468618 NM_SWA_Slave_CAB 2000;
BA_REL_ "GenSigTimeoutTime" BU_SG_REL_ NightVision SG_ 2527679498 Perso_Kontonummer 5000;
BA_REL_ "GenSigTimeoutTime" BU_SG_REL_ NightVision SG_ 2527679498 Perso_Steuerung 5000;
BA_REL_ "GenSigTimeoutTime" BU_SG_REL_ NightVision SG_ 2527679498 Perso_Steuerungsparameter 5000;
BA_REL_ "GenSigTimeoutTime" BU_SG_REL_ NightVision SG_ 2527679498 Perso_Status 5000;
BA_REL_ "GenSigTimeoutTime" BU_SG_REL_ NightVision SG_ 319 SC_PreSense_FCWP 2000;
BA_REL_ "GenSigTimeoutTime" BU_SG_REL_ NightVision SG_ 319 SC_PreCrash_Warnung 2000;
BA_REL_ "GenSigTimeoutTime" BU_SG_REL_ NightVision SG_ 1122 PSD_Segment_ID 1500;
BA_REL_ "GenSigTimeoutTime" BU_SG_REL_ NightVision SG_ 1122 PSD_Vorgaenger_Segment_ID 1500;
BA_REL_ "GenSigTimeoutTime" BU_SG_REL_ NightVision SG_ 1122 PSD_Segmentlaenge 1500;
BA_REL_ "GenSigTimeoutTime" BU_SG_REL_ NightVision SG_ 1122 PSD_Strassenkategorie 1500;
BA_REL_ "GenSigTimeoutTime" BU_SG_REL_ NightVision SG_ 1122 PSD_Endkruemmung 1500;
BA_REL_ "GenSigTimeoutTime" BU_SG_REL_ NightVision SG_ 1122 PSD_Endkruemmung_Vorz 1500;
BA_REL_ "GenSigTimeoutTime" BU_SG_REL_ NightVision SG_ 1122 PSD_Idenditaets_ID 1500;
BA_REL_ "GenSigTimeoutTime" BU_SG_REL_ NightVision SG_ 1122 PSD_ADAS_Qualitaet 1500;
BA_REL_ "GenSigTimeoutTime" BU_SG_REL_ NightVision SG_ 1122 PSD_wahrscheinlichster_Pfad 1500;
BA_REL_ "GenSigTimeoutTime" BU_SG_REL_ NightVision SG_ 1122 PSD_Geradester_Pfad 1500;
BA_REL_ "GenSigTimeoutTime" BU_SG_REL_ NightVision SG_ 1122 PSD_Fahrspuren_Anzahl 1500;
BA_REL_ "GenSigTimeoutTime" BU_SG_REL_ NightVision SG_ 1122 PSD_Bebauung 1500;
BA_REL_ "GenSigTimeoutTime" BU_SG_REL_ NightVision SG_ 1122 PSD_Segment_Komplett 1500;
BA_REL_ "GenSigTimeoutTime" BU_SG_REL_ NightVision SG_ 1122 PSD_Rampe 1500;
BA_REL_ "GenSigTimeoutTime" BU_SG_REL_ NightVision SG_ 1122 PSD_Anfangskruemmung 1500;
BA_REL_ "GenSigTimeoutTime" BU_SG_REL_ NightVision SG_ 1122 PSD_Anfangskruemmung_Vorz 1500;
BA_REL_ "GenSigTimeoutTime" BU_SG_REL_ NightVision SG_ 1122 PSD_Abzweigerichtung 1500;
BA_REL_ "GenSigTimeoutTime" BU_SG_REL_ NightVision SG_ 1122 PSD_Abzweigewinkel 1500;
BA_REL_ "GenSigTimeoutTime" BU_SG_REL_ NightVision SG_ 1123 PSD_Pos_Segment_ID 1500;
BA_REL_ "GenSigTimeoutTime" BU_SG_REL_ NightVision SG_ 1123 PSD_Pos_Segmentlaenge 1500;
BA_REL_ "GenSigTimeoutTime" BU_SG_REL_ NightVision SG_ 1123 PSD_Pos_Inhibitzeit 1500;
BA_REL_ "GenSigTimeoutTime" BU_SG_REL_ NightVision SG_ 1123 PSD_Pos_Standort_Eindeutig 1500;
BA_REL_ "GenSigTimeoutTime" BU_SG_REL_ NightVision SG_ 1123 PSD_Pos_Fehler_Laengsrichtung 1500;
BA_REL_ "GenSigTimeoutTime" BU_SG_REL_ NightVision SG_ 1123 PSD_Pos_Fahrspur 1500;
BA_REL_ "GenSigTimeoutTime" BU_SG_REL_ NightVision SG_ 1123 PSD_Attribut_Segment_ID_05 1500;
BA_REL_ "GenSigTimeoutTime" BU_SG_REL_ NightVision SG_ 1123 PSD_Attribut_1_ID 1500;
BA_REL_ "GenSigTimeoutTime" BU_SG_REL_ NightVision SG_ 1123 PSD_Attribut_1_Wert 1500;
BA_REL_ "GenSigTimeoutTime" BU_SG_REL_ NightVision SG_ 1123 PSD_Attribut_1_Offset 1500;
BA_REL_ "GenSigTimeoutTime" BU_SG_REL_ NightVision SG_ 1123 PSD_Attribut_2_ID 1500;
BA_REL_ "GenSigTimeoutTime" BU_SG_REL_ NightVision SG_ 1123 PSD_Attribut_2_Wert 1500;
BA_REL_ "GenSigTimeoutTime" BU_SG_REL_ NightVision SG_ 1123 PSD_Attribut_2_Offset 1500;
BA_REL_ "GenSigTimeoutTime" BU_SG_REL_ NightVision SG_ 1123 PSD_Attribute_Komplett_05 1500;
BA_REL_ "GenSigTimeoutTime" BU_SG_REL_ NightVision SG_ 1124 PSD_06_Mux 1500;
BA_REL_ "GenSigTimeoutTime" BU_SG_REL_ NightVision SG_ 1124 PSD_Sys_Segment_ID 1500;
BA_REL_ "GenSigTimeoutTime" BU_SG_REL_ NightVision SG_ 1124 PSD_Attribut_Segment_ID 1500;
BA_REL_ "GenSigTimeoutTime" BU_SG_REL_ NightVision SG_ 1124 PSD_Ges_Segment_ID 1500;
BA_REL_ "GenSigTimeoutTime" BU_SG_REL_ NightVision SG_ 1124 PSD_Baum_Laenge_VZ 1500;
BA_REL_ "GenSigTimeoutTime" BU_SG_REL_ NightVision SG_ 1124 PSD_Steigung_1_Segment_ID 1500;
BA_REL_ "GenSigTimeoutTime" BU_SG_REL_ NightVision SG_ 1124 PSD_Baum_Laenge 1500;
BA_REL_ "GenSigTimeoutTime" BU_SG_REL_ NightVision SG_ 1124 PSD_Sys_Laendercode 1500;
BA_REL_ "GenSigTimeoutTime" BU_SG_REL_ NightVision SG_ 1124 PSD_Attribut_3_ID 1500;
BA_REL_ "GenSigTimeoutTime" BU_SG_REL_ NightVision SG_ 1124 PSD_Ges_Offset 1500;
BA_REL_ "GenSigTimeoutTime" BU_SG_REL_ NightVision SG_ 1124 PSD_Steigung_1_A_Steigung 1500;
BA_REL_ "GenSigTimeoutTime" BU_SG_REL_ NightVision SG_ 1124 PSD_Attribut_3_Offset 1500;
BA_REL_ "GenSigTimeoutTime" BU_SG_REL_ NightVision SG_ 1124 PSD_Ges_Geschwindigkeit 1500;
BA_REL_ "GenSigTimeoutTime" BU_SG_REL_ NightVision SG_ 1124 PSD_Steigung_1_A_Vorz 1500;
BA_REL_ "GenSigTimeoutTime" BU_SG_REL_ NightVision SG_ 1124 PSD_Sys_Geschwindigkeit_Einheit 1500;
BA_REL_ "GenSigTimeoutTime" BU_SG_REL_ NightVision SG_ 1124 PSD_Steigung_1_A_Offset 1500;
BA_REL_ "GenSigTimeoutTime" BU_SG_REL_ NightVision SG_ 1124 PSD_Sys_Verkehrsrichtung 1500;
BA_REL_ "GenSigTimeoutTime" BU_SG_REL_ NightVision SG_ 1124 PSD_Sys_Geometrieguete 1500;
BA_REL_ "GenSigTimeoutTime" BU_SG_REL_ NightVision SG_ 1124 PSD_Sys_Mapmatchingguete 1500;
BA_REL_ "GenSigTimeoutTime" BU_SG_REL_ NightVision SG_ 1124 PSD_Attribut_3_Wert 1500;
BA_REL_ "GenSigTimeoutTime" BU_SG_REL_ NightVision SG_ 1124 PSD_Ges_Typ 1500;
BA_REL_ "GenSigTimeoutTime" BU_SG_REL_ NightVision SG_ 1124 PSD_Sys_Alter_Karte 1500;
BA_REL_ "GenSigTimeoutTime" BU_SG_REL_ NightVision SG_ 1124 PSD_Ges_Spur_Geschw_Begrenzung 1500;
BA_REL_ "GenSigTimeoutTime" BU_SG_REL_ NightVision SG_ 1124 PSD_Steigung_1_B_Steigung 1500;
BA_REL_ "GenSigTimeoutTime" BU_SG_REL_ NightVision SG_ 1124 PSD_Attribut_4_ID 1500;
BA_REL_ "GenSigTimeoutTime" BU_SG_REL_ NightVision SG_ 1124 PSD_Sys_Zielfuehrung 1500;
BA_REL_ "GenSigTimeoutTime" BU_SG_REL_ NightVision SG_ 1124 PSD_Sys_US_State 1500;
BA_REL_ "GenSigTimeoutTime" BU_SG_REL_ NightVision SG_ 1124 PSD_Ges_Geschwindigkeit_Gespann 1500;
BA_REL_ "GenSigTimeoutTime" BU_SG_REL_ NightVision SG_ 1124 PSD_Baum_Breite_VZ 1500;
BA_REL_ "GenSigTimeoutTime" BU_SG_REL_ NightVision SG_ 1124 PSD_Attribut_4_Wert 1500;
BA_REL_ "GenSigTimeoutTime" BU_SG_REL_ NightVision SG_ 1124 PSD_Baum_Breite 1500;
BA_REL_ "GenSigTimeoutTime" BU_SG_REL_ NightVision SG_ 1124 PSD_Ges_Geschwindigkeit_Witter 1500;
BA_REL_ "GenSigTimeoutTime" BU_SG_REL_ NightVision SG_ 1124 PSD_Steigung_1_B_Vorz 1500;
BA_REL_ "GenSigTimeoutTime" BU_SG_REL_ NightVision SG_ 1124 PSD_Steigung_1_B_Offset 1500;
BA_REL_ "GenSigTimeoutTime" BU_SG_REL_ NightVision SG_ 1124 PSD_Sys_Quali_Geometrien 1500;
BA_REL_ "GenSigTimeoutTime" BU_SG_REL_ NightVision SG_ 1124 PSD_Ges_Geschwindigkeit_Tag_Anf 1500;
BA_REL_ "GenSigTimeoutTime" BU_SG_REL_ NightVision SG_ 1124 PSD_Attribut_4_Offset 1500;
BA_REL_ "GenSigTimeoutTime" BU_SG_REL_ NightVision SG_ 1124 PSD_Sys_Quali_Ortsinfo 1500;
BA_REL_ "GenSigTimeoutTime" BU_SG_REL_ NightVision SG_ 1124 PSD_Ges_Geschwindigkeit_Tag_Ende 1500;
BA_REL_ "GenSigTimeoutTime" BU_SG_REL_ NightVision SG_ 1124 PSD_Sys_Quali_verfuegbar 1500;
BA_REL_ "GenSigTimeoutTime" BU_SG_REL_ NightVision SG_ 1124 PSD_Sys_Zielfuehrung_geaendert 1500;
BA_REL_ "GenSigTimeoutTime" BU_SG_REL_ NightVision SG_ 1124 PSD_Ges_Geschwindigkeit_Std_Anf 1500;
BA_REL_ "GenSigTimeoutTime" BU_SG_REL_ NightVision SG_ 1124 PSD_Steigung_1_Attribute_kompl 1500;
BA_REL_ "GenSigTimeoutTime" BU_SG_REL_ NightVision SG_ 1124 PSD_Sys_Geometrieguete_erweitert 1500;
BA_REL_ "GenSigTimeoutTime" BU_SG_REL_ NightVision SG_ 1124 PSD_Steigung_2_Segment_ID 1500;
BA_REL_ "GenSigTimeoutTime" BU_SG_REL_ NightVision SG_ 1124 PSD_Attribut_5_ID 1500;
BA_REL_ "GenSigTimeoutTime" BU_SG_REL_ NightVision SG_ 1124 PSD_Ges_Geschwindigkeit_Std_Ende 1500;
BA_REL_ "GenSigTimeoutTime" BU_SG_REL_ NightVision SG_ 1124 PSD_Attribut_5_Offset 1500;
BA_REL_ "GenSigTimeoutTime" BU_SG_REL_ NightVision SG_ 1124 PSD_Steigung_2_Steigung 1500;
BA_REL_ "GenSigTimeoutTime" BU_SG_REL_ NightVision SG_ 1124 PSD_Sys_Quali_sonstige_Attribute 1500;
BA_REL_ "GenSigTimeoutTime" BU_SG_REL_ NightVision SG_ 1124 PSD_Ges_Ueberholverbot 1500;
BA_REL_ "GenSigTimeoutTime" BU_SG_REL_ NightVision SG_ 1124 PSD_Sys_Quali_Steigungen 1500;
BA_REL_ "GenSigTimeoutTime" BU_SG_REL_ NightVision SG_ 1124 PSD_Ges_Wechselverkehrszeichen 1500;
BA_REL_ "GenSigTimeoutTime" BU_SG_REL_ NightVision SG_ 1124 PSD_Attribut_5_Wert 1500;
BA_REL_ "GenSigTimeoutTime" BU_SG_REL_ NightVision SG_ 1124 PSD_Steigung_2_Vorz 1500;
BA_REL_ "GenSigTimeoutTime" BU_SG_REL_ NightVision SG_ 1124 PSD_Sys_Quali_Strassenkennz 1500;
BA_REL_ "GenSigTimeoutTime" BU_SG_REL_ NightVision SG_ 1124 PSD_Wechselverkehrszeichen_Typ 1500;
BA_REL_ "GenSigTimeoutTime" BU_SG_REL_ NightVision SG_ 1124 PSD_Baum_Ausrichtung 1500;
BA_REL_ "GenSigTimeoutTime" BU_SG_REL_ NightVision SG_ 1124 PSD_Steigung_2_Offset 1500;
BA_REL_ "GenSigTimeoutTime" BU_SG_REL_ NightVision SG_ 1124 PSD_Ges_Gesetzlich_Kategorie 1500;
BA_REL_ "GenSigTimeoutTime" BU_SG_REL_ NightVision SG_ 1124 PSD_Sys_Quali_Tempolimits 1500;
BA_REL_ "GenSigTimeoutTime" BU_SG_REL_ NightVision SG_ 1124 PSD_Attribute_Komplett_06 1500;
BA_REL_ "GenSigTimeoutTime" BU_SG_REL_ NightVision SG_ 1124 PSD_Ges_Gesetzlich_Zusatz 1500;
BA_REL_ "GenSigTimeoutTime" BU_SG_REL_ NightVision SG_ 1124 PSD_Sys_Quali_Vorfahrtsregelung 1500;
BA_REL_ "GenSigTimeoutTime" BU_SG_REL_ NightVision SG_ 1124 PSD_Ges_Verkehrszeichen_Quelle 1500;
BA_REL_ "GenSigTimeoutTime" BU_SG_REL_ NightVision SG_ 1124 PSD_Steigung_2_Attribute_kompl 1500;
BA_REL_ "GenSigTimeoutTime" BU_SG_REL_ NightVision SG_ 1124 PSD_Ges_Attribute_Komplett 1500;
BA_REL_ "GenSigTimeoutTime" BU_SG_REL_ RDK SG_ 2600468585 NM_Rearview_SNI 2000;
BA_REL_ "GenSigTimeoutTime" BU_SG_REL_ RDK SG_ 2600468585 NM_Rearview_CBV_CRI 2000;
BA_REL_ "GenSigTimeoutTime" BU_SG_REL_ RDK SG_ 2600468585 NM_RearView_CAB 2000;
BA_REL_ "GenSigTimeoutTime" BU_SG_REL_ RDK SG_ 2600468522 NM_SCR_SNI 2000;
BA_REL_ "GenSigTimeoutTime" BU_SG_REL_ RDK SG_ 2600468522 NM_SCR_CBV_CRI 2000;
BA_REL_ "GenSigTimeoutTime" BU_SG_REL_ RDK SG_ 2600468522 NM_SCR_CAB 2000;
BA_REL_ "GenSigTimeoutTime" BU_SG_REL_ RDK SG_ 2600468586 NM_STH_SNI 2000;
BA_REL_ "GenSigTimeoutTime" BU_SG_REL_ RDK SG_ 2600468586 NM_STH_CBV_CRI 2000;
BA_REL_ "GenSigTimeoutTime" BU_SG_REL_ RDK SG_ 2600468586 NM_STH_CAB 2000;
BA_REL_ "GenSigTimeoutTime" BU_SG_REL_ RDK SG_ 2600468558 NM_SWA_SNI 2000;
BA_REL_ "GenSigTimeoutTime" BU_SG_REL_ RDK SG_ 2600468558 NM_SWA_CBV_CRI 2000;
BA_REL_ "GenSigTimeoutTime" BU_SG_REL_ RDK SG_ 2600468558 NM_SWA_CAB 2000;
BA_REL_ "GenSigTimeoutTime" BU_SG_REL_ RDK SG_ 2600468618 NM_SWA_Slave_SNI 2000;
BA_REL_ "GenSigTimeoutTime" BU_SG_REL_ RDK SG_ 2600468618 NM_SWA_Slave_CBV_CRI 2000;
BA_REL_ "GenSigTimeoutTime" BU_SG_REL_ RDK SG_ 2600468618 NM_SWA_Slave_CAB 2000;
BA_REL_ "GenSigTimeoutTime" BU_SG_REL_ RDK SG_ 2589283656 ORU_Status 5000;
BA_REL_ "GenSigTimeoutTime" BU_SG_REL_ SCR SG_ 2600468585 NM_Rearview_SNI 2000;
BA_REL_ "GenSigTimeoutTime" BU_SG_REL_ SCR SG_ 2600468585 NM_Rearview_CBV_CRI 2000;
BA_REL_ "GenSigTimeoutTime" BU_SG_REL_ SCR SG_ 2600468585 NM_RearView_CAB 2000;
BA_REL_ "GenSigTimeoutTime" BU_SG_REL_ SCR SG_ 2600468586 NM_STH_SNI 2000;
BA_REL_ "GenSigTimeoutTime" BU_SG_REL_ SCR SG_ 2600468586 NM_STH_CBV_CRI 2000;
BA_REL_ "GenSigTimeoutTime" BU_SG_REL_ SCR SG_ 2600468586 NM_STH_CAB 2000;
BA_REL_ "GenSigTimeoutTime" BU_SG_REL_ SCR SG_ 2600468558 NM_SWA_SNI 2000;
BA_REL_ "GenSigTimeoutTime" BU_SG_REL_ SCR SG_ 2600468558 NM_SWA_CBV_CRI 2000;
BA_REL_ "GenSigTimeoutTime" BU_SG_REL_ SCR SG_ 2600468558 NM_SWA_CAB 2000;
BA_REL_ "GenSigTimeoutTime" BU_SG_REL_ SCR SG_ 2600468618 NM_SWA_Slave_SNI 2000;
BA_REL_ "GenSigTimeoutTime" BU_SG_REL_ SCR SG_ 2600468618 NM_SWA_Slave_CBV_CRI 2000;
BA_REL_ "GenSigTimeoutTime" BU_SG_REL_ SCR SG_ 2600468618 NM_SWA_Slave_CAB 2000;
BA_REL_ "GenSigTimeoutTime" BU_SG_REL_ SCR SG_ 913 OBD_Calc_Load_Val 2000;
BA_REL_ "GenSigTimeoutTime" BU_SG_REL_ SCR SG_ 913 OBD_Eng_Cool_Temp 2000;
BA_REL_ "GenSigTimeoutTime" BU_SG_REL_ SCR SG_ 913 OBD_Abs_Throttle_Pos 2000;
BA_REL_ "GenSigTimeoutTime" BU_SG_REL_ SCR SG_ 913 OBD_Abs_Load_Val 2000;
BA_REL_ "GenSigTimeoutTime" BU_SG_REL_ SCR SG_ 913 OBD_Abs_Pedal_Pos 2000;
BA_REL_ "GenSigTimeoutTime" BU_SG_REL_ SCR SG_ 913 MO_QBit_Aussen_Temp 2000;
BA_REL_ "GenSigTimeoutTime" BU_SG_REL_ SCR SG_ 913 OBD_Sperrung_IUMPR 2000;
BA_REL_ "GenSigTimeoutTime" BU_SG_REL_ SCR SG_ 913 OBD_Kaltstart_Denominator 2000;
BA_REL_ "GenSigTimeoutTime" BU_SG_REL_ SCR SG_ 913 OBD_Minimum_Trip 2000;
BA_REL_ "GenSigTimeoutTime" BU_SG_REL_ SCR SG_ 913 OBD_Driving_Cycle 2000;
BA_REL_ "GenSigTimeoutTime" BU_SG_REL_ SCR SG_ 913 OBD_Warm_Up_Cycle 2000;
BA_REL_ "GenSigTimeoutTime" BU_SG_REL_ SCR SG_ 913 OBD_Normed_Trip 2000;
BA_REL_ "GenSigTimeoutTime" BU_SG_REL_ SCR SG_ 2589283478 OBD_Aussen_Temp_gef 3200;
BA_REL_ "GenSigTimeoutTime" BU_SG_REL_ STH_MLBevo SG_ 1635 BEM_02_Abschaltstufen 1000;
BA_REL_ "GenSigTimeoutTime" BU_SG_REL_ STH_MLBevo SG_ 1635 BEM_STH_Einschaltverbot 1000;
BA_REL_ "GenSigTimeoutTime" BU_SG_REL_ STH_MLBevo SG_ 1635 BEM_HL_Regelung_Status 1000;
BA_REL_ "GenSigTimeoutTime" BU_SG_REL_ STH_MLBevo SG_ 2600468585 NM_Rearview_SNI 2000;
BA_REL_ "GenSigTimeoutTime" BU_SG_REL_ STH_MLBevo SG_ 2600468585 NM_Rearview_CBV_CRI 2000;
BA_REL_ "GenSigTimeoutTime" BU_SG_REL_ STH_MLBevo SG_ 2600468585 NM_RearView_CAB 2000;
BA_REL_ "GenSigTimeoutTime" BU_SG_REL_ STH_MLBevo SG_ 2600468522 NM_SCR_SNI 2000;
BA_REL_ "GenSigTimeoutTime" BU_SG_REL_ STH_MLBevo SG_ 2600468522 NM_SCR_CBV_CRI 2000;
BA_REL_ "GenSigTimeoutTime" BU_SG_REL_ STH_MLBevo SG_ 2600468522 NM_SCR_CAB 2000;
BA_REL_ "GenSigTimeoutTime" BU_SG_REL_ STH_MLBevo SG_ 2600468558 NM_SWA_SNI 2000;
BA_REL_ "GenSigTimeoutTime" BU_SG_REL_ STH_MLBevo SG_ 2600468558 NM_SWA_CBV_CRI 2000;
BA_REL_ "GenSigTimeoutTime" BU_SG_REL_ STH_MLBevo SG_ 2600468558 NM_SWA_CAB 2000;
BA_REL_ "GenSigTimeoutTime" BU_SG_REL_ STH_MLBevo SG_ 2600468618 NM_SWA_Slave_SNI 2000;
BA_REL_ "GenSigTimeoutTime" BU_SG_REL_ STH_MLBevo SG_ 2600468618 NM_SWA_Slave_CBV_CRI 2000;
BA_REL_ "GenSigTimeoutTime" BU_SG_REL_ STH_MLBevo SG_ 2600468618 NM_SWA_Slave_CAB 2000;
BA_REL_ "GenSigTimeoutTime" BU_SG_REL_ TopView SG_ 2600468522 NM_SCR_SNI 2000;
BA_REL_ "GenSigTimeoutTime" BU_SG_REL_ TopView SG_ 2600468522 NM_SCR_CBV_CRI 2000;
BA_REL_ "GenSigTimeoutTime" BU_SG_REL_ TopView SG_ 2600468522 NM_SCR_CAB 2000;
BA_REL_ "GenSigTimeoutTime" BU_SG_REL_ TopView SG_ 2600468586 NM_STH_SNI 2000;
BA_REL_ "GenSigTimeoutTime" BU_SG_REL_ TopView SG_ 2600468586 NM_STH_CBV_CRI 2000;
BA_REL_ "GenSigTimeoutTime" BU_SG_REL_ TopView SG_ 2600468586 NM_STH_CAB 2000;
BA_REL_ "GenSigTimeoutTime" BU_SG_REL_ TopView SG_ 2600468558 NM_SWA_SNI 2000;
BA_REL_ "GenSigTimeoutTime" BU_SG_REL_ TopView SG_ 2600468558 NM_SWA_CBV_CRI 2000;
BA_REL_ "GenSigTimeoutTime" BU_SG_REL_ TopView SG_ 2600468558 NM_SWA_CAB 2000;
BA_REL_ "GenSigTimeoutTime" BU_SG_REL_ TopView SG_ 2600468618 NM_SWA_Slave_SNI 2000;
BA_REL_ "GenSigTimeoutTime" BU_SG_REL_ TopView SG_ 2600468618 NM_SWA_Slave_CBV_CRI 2000;
BA_REL_ "GenSigTimeoutTime" BU_SG_REL_ TopView SG_ 2600468618 NM_SWA_Slave_CAB 2000;
BA_REL_ "GenSigTimeoutTime" BU_SG_REL_ TopView SG_ 1175 PH_Visualisierung 1000;
BA_REL_ "GenSigTimeoutTime" BU_SG_REL_ TopView SG_ 1175 PLA_Anf_Aufschaltung_RVC 1000;
BA_REL_ "GenSigTimeoutTime" BU_SG_REL_ TopView SG_ 1175 PH_Taster 1000;
BA_REL_ "GenSigTimeoutTime" BU_SG_REL_ TopView SG_ 1175 PH_Systemzustand 1000;
BA_REL_ "GenSigTimeoutTime" BU_SG_REL_ TopView SG_ 1353 PL_Luecke_P0_x 1000;
BA_REL_ "GenSigTimeoutTime" BU_SG_REL_ TopView SG_ 1353 PL_Luecke_P0_y 1000;
BA_REL_ "GenSigTimeoutTime" BU_SG_REL_ TopView SG_ 1353 PL_Luecke_P2_x 1000;
BA_REL_ "GenSigTimeoutTime" BU_SG_REL_ TopView SG_ 1353 PL_Luecke_P2_y 1000;
BA_REL_ "GenSigTimeoutTime" BU_SG_REL_ TopView SG_ 1354 PL_Luecke_P1_x 1000;
BA_REL_ "GenSigTimeoutTime" BU_SG_REL_ TopView SG_ 1354 PL_Luecke_P1_y 1000;
BA_REL_ "GenSigTimeoutTime" BU_SG_REL_ TopView SG_ 1354 PL_Luecke_P3_x 1000;
BA_REL_ "GenSigTimeoutTime" BU_SG_REL_ TopView SG_ 1354 PL_Luecke_P3_y 1000;
BA_REL_ "GenSigTimeoutTime" BU_SG_REL_ TopView SG_ 1355 PH_Aufschaltursache 5000;
VAL_ 2600468585 NM_Rearview_SNI 105 "Rearview" ;
VAL_ 2600468585 NM_Rearview_CBV_AWB 0 "Passiver_WakeUp" 1 "Aktiver_WakeUp" ;
VAL_ 2600468585 NM_Rearview_CBV_CRI 0 "NM_ohne_Clusteranforderungen" 1 "NM_mit_Clusteranforderungen" ;
VAL_ 2600468585 NM_Rearview_NM_State 0 "Init" 1 "NM_RM_aus_BSM" 2 "NM_RM_aus_PBSM" 4 "NM_NO_aus_RM" 8 "NM_NO_aus_RS" 16 "reserved" 32 "reserved" ;
VAL_ 2600468585 NM_Rearview_Car_Wakeup 0 "Inaktiv" 1 "Car_Wakeup" ;
VAL_ 2600468585 NM_Rearview_UDS_CC 0 "Inaktiv" 1 "CC_aktiv" ;
VAL_ 2600468585 NM_Rearview_NM_aktiv_KL15 0 "Inaktiv" 1 "KL15_EIN" ;
VAL_ 2600468585 NM_Rearview_NM_aktiv_Diagnose 0 "Init" 1 "Diagnose_aktiv" ;
VAL_ 2600468585 NM_Rearview_NM_aktiv_Tmin 0 "Inaktiv" 1 "Mindestaktivzeit" ;
VAL_ 2600468585 NM_RearView_CAB 0 "inaktiv" 1 "CAB_01__Tueren" 2 "CAB_02__Anhaenger_KCAN" 4 "CAB_03__Nightvision" 8 "CAB_04__Sitzverstellung" 16 "CAB_05__Klappen" 32 "CAB_06__Infotainment" 64 "CAB_07__Sub_Infotainment" 128 "CAB_08__Anzeige" 256 "CAB_09__Laden_HCAN" 512 "CAB_10__Klima" 1024 "CAB_11__FlexRay" 262144 "CAB_19__VLAN_RemoteFC" 524288 "CAB_20__VLAN_Komfort" 1048576 "CAB_21__VLAN_Internet" 2097152 "CAB_22__VLAN_Connect" 4194304 "CAB_23__VLAN_Infotainment" 8388608 "CAB_24__VLAN_FAS" ;
VAL_ 2600468522 NM_SCR_SNI 42 "SCR" ;
VAL_ 2600468522 NM_SCR_CBV_AWB 0 "Passiver_WakeUp" 1 "Aktiver_WakeUp" ;
VAL_ 2600468522 NM_SCR_CBV_CRI 0 "NM_ohne_Clusteranforderungen" 1 "NM_mit_Clusteranforderungen" ;
VAL_ 2600468522 NM_SCR_NM_State 0 "Init" 1 "NM_RM_aus_BSM" 2 "NM_RM_aus_PBSM" 4 "NM_NO_aus_RM" 8 "NM_NO_aus_RS" 16 "reserved" 32 "reserved" ;
VAL_ 2600468522 NM_SCR_Car_Wakeup 0 "Inaktiv" 1 "Car_Wakeup" ;
VAL_ 2600468522 NM_SCR_UDS_CC 0 "Inaktiv" 1 "CC_aktiv" ;
VAL_ 2600468522 NM_SCR_NM_aktiv_KL15 0 "Inaktiv" 1 "KL15_EIN" ;
VAL_ 2600468522 NM_SCR_NM_aktiv_Diagnose 0 "Init" 1 "Diagnose_aktiv" ;
VAL_ 2600468522 NM_SCR_NM_aktiv_Tmin 0 "Inaktiv" 1 "Mindestaktivzeit" ;
VAL_ 2600468522 NM_SCR_NM_aktiv_Evakuierung_Sys 1 "Evakuierung_System_aktiv" ;
VAL_ 2600468522 NM_SCR_CAB 0 "inaktiv" 1 "CAB_01__Tueren" 2 "CAB_02__Anhaenger_KCAN" 4 "CAB_03__Nightvision" 8 "CAB_04__Sitzverstellung" 16 "CAB_05__Klappen" 32 "CAB_06__Infotainment" 64 "CAB_07__Sub_Infotainment" 128 "CAB_08__Anzeige" 256 "CAB_09__Laden_HCAN" 512 "CAB_10__Klima" 1024 "CAB_11__FlexRay" 262144 "CAB_19__VLAN_RemoteFC" 524288 "CAB_20__VLAN_Komfort" 1048576 "CAB_21__VLAN_Internet" 2097152 "CAB_22__VLAN_Connect" 4194304 "CAB_23__VLAN_Infotainment" 8388608 "CAB_24__VLAN_FAS" ;
VAL_ 2600468586 NM_STH_SNI 106 "STH" ;
VAL_ 2600468586 NM_STH_CBV_AWB 0 "Passiver_WakeUp" 1 "Aktiver_WakeUp" ;
VAL_ 2600468586 NM_STH_CBV_CRI 0 "NM_ohne_Clusteranforderungen" 1 "NM_mit_Clusteranforderungen" ;
VAL_ 2600468586 NM_STH_NM_State 0 "Init" 1 "NM_RM_aus_BSM" 2 "NM_RM_aus_PBSM" 4 "NM_NO_aus_RM" 8 "NM_NO_aus_RS" 16 "reserved" 32 "reserved" ;
VAL_ 2600468586 NM_STH_Car_Wakeup 0 "Inaktiv" 1 "Car_Wakeup" ;
VAL_ 2600468586 NM_STH_UDS_CC 0 "Inaktiv" 1 "CC_aktiv" ;
VAL_ 2600468586 NM_STH_NM_aktiv_KL15 0 "Inaktiv" 1 "KL15_EIN" ;
VAL_ 2600468586 NM_STH_NM_aktiv_Diagnose 0 "Init" 1 "Diagnose_aktiv" ;
VAL_ 2600468586 NM_STH_NM_aktiv_Tmin 0 "Inaktiv" 1 "Mindestaktivzeit" ;
VAL_ 2600468586 NM_STH_NM_aktiv_EKP_Anf 1 "EKP_Anf_aktiv" ;
VAL_ 2600468586 NM_STH_NM_aktiv_WaPu_Anf 1 "WaPu_Anf_aktiv" ;
VAL_ 2600468586 NM_STH_NM_aktiv_EIN_AUS_Funk 1 "EIN_AUS_Funk_aktiv" ;
VAL_ 2600468586 NM_STH_CAB 0 "inaktiv" 1 "CAB_01__Tueren" 2 "CAB_02__Anhaenger_KCAN" 4 "CAB_03__Nightvision" 8 "CAB_04__Sitzverstellung" 16 "CAB_05__Klappen" 32 "CAB_06__Infotainment" 64 "CAB_07__Sub_Infotainment" 128 "CAB_08__Anzeige" 256 "CAB_09__Laden_HCAN" 512 "CAB_10__Klima" 1024 "CAB_11__FlexRay" 262144 "CAB_19__VLAN_RemoteFC" 524288 "CAB_20__VLAN_Komfort" 1048576 "CAB_21__VLAN_Internet" 2097152 "CAB_22__VLAN_Connect" 4194304 "CAB_23__VLAN_Infotainment" 8388608 "CAB_24__VLAN_FAS" ;
VAL_ 2600468558 NM_SWA_SNI 78 "SWA" ;
VAL_ 2600468558 NM_SWA_CBV_AWB 0 "Passiver_WakeUp" 1 "Aktiver_WakeUp" ;
VAL_ 2600468558 NM_SWA_CBV_CRI 0 "Standard_Layout" 1 "TNB_Layout" ;
VAL_ 2600468558 NM_SWA_NM_State 1 "NM_RM_aus_BSM" 2 "NM_RM_aus_PBSM" 4 "NM_NO_aus_RM" 8 "NM_NO_aus_RS" 16 "NM_RM_aus_RS" 32 "NM_RM_aus_NO" ;
VAL_ 2600468558 NM_SWA_Car_Wakeup 0 "Inaktiv" 1 "Car_Wakeup" ;
VAL_ 2600468558 NM_SWA_UDS_CC 0 "Init" 1 "CC_aktiv" ;
VAL_ 2600468558 NM_SWA_NM_aktiv_KL15 0 "Inaktiv" 1 "KL15_EIN" ;
VAL_ 2600468558 NM_SWA_NM_aktiv_Diagnose 0 "Init" 1 "Diagnose_aktiv" ;
VAL_ 2600468558 NM_SWA_NM_aktiv_Tmin 0 "Inaktiv" 1 "Mindestaktivzeit" ;
VAL_ 2600468558 NM_SWA_NM_aktiv_ASW_aktiv 0 "ASW_nicht_aktiv" 1 "ASW_aktiv" ;
VAL_ 2600468558 NM_SWA_CAB 0 "inaktiv" 1 "CAB_01__Tueren" 2 "CAB_02__Anhaenger_KCAN" 4 "CAB_03__Nightvision" 8 "CAB_04__Sitzverstellung" 16 "CAB_05__Klappen" 32 "CAB_06__Infotainment" 64 "CAB_07__Sub_Infotainment" 128 "CAB_08__Anzeige" 256 "CAB_09__Laden_HCAN" 512 "CAB_10__Klima" 1024 "CAB_11__FlexRay" 262144 "CAB_19__VLAN_RemoteFC" 524288 "CAB_20__VLAN_Komfort" 1048576 "CAB_21__VLAN_Internet" 2097152 "CAB_22__VLAN_Connect" 4194304 "CAB_23__VLAN_Infotainment" 8388608 "CAB_24__VLAN_FAS" ;
VAL_ 2600468618 NM_SWA_Slave_SNI 138 "SWA_Slave" ;
VAL_ 2600468618 NM_SWA_Slave_CBV_AWB 0 "Passiver_WakeUp" 1 "Aktiver_WakeUp" ;
VAL_ 2600468618 NM_SWA_Slave_CBV_CRI 0 "Standard_Layout" 1 "TNB_Layout" ;
VAL_ 2600468618 NM_SWA_Slave_NM_State 1 "NM_RM_aus_BSM" 2 "NM_RM_aus_PBSM" 4 "NM_NO_aus_RM" 8 "NM_NO_aus_RS" 16 "NM_RM_aus_RS" 32 "NM_RM_aus_NO" ;
VAL_ 2600468618 NM_SWA_Slave_Car_Wakeup 0 "Inaktiv" 1 "Car_Wakeup" ;
VAL_ 2600468618 NM_SWA_Slave_UDS_CC 0 "Init" 1 "CC_aktiv" ;
VAL_ 2600468618 NM_SWA_Slave_NM_aktiv_KL15 0 "Inaktiv" 1 "KL15_EIN" ;
VAL_ 2600468618 NM_SWA_Slave_NM_aktiv_Diagnose 0 "Init" 1 "Diagnose_aktiv" ;
VAL_ 2600468618 NM_SWA_Slave_NM_aktiv_Tmin 0 "Inaktiv" 1 "Mindestaktivzeit" ;
VAL_ 2600468618 NM_SWA_Slave_NM_aktiv_ASW_aktiv 0 "ASW_nicht_aktiv" 1 "ASW_aktiv" ;
VAL_ 2600468618 NM_SWA_Slave_CAB 0 "inaktiv" 1 "CAB_01__Tueren" 2 "CAB_02__Anhaenger_KCAN" 4 "CAB_03__Nightvision" 8 "CAB_04__Sitzverstellung" 16 "CAB_05__Klappen" 32 "CAB_06__Infotainment" 64 "CAB_07__Sub_Infotainment" 128 "CAB_08__Anzeige" 256 "CAB_09__Laden_HCAN" 512 "CAB_10__Klima" 1024 "CAB_11__FlexRay" 262144 "CAB_19__VLAN_RemoteFC" 524288 "CAB_20__VLAN_Komfort" 1048576 "CAB_21__VLAN_Internet" 2097152 "CAB_22__VLAN_Connect" 4194304 "CAB_23__VLAN_Infotainment" 8388608 "CAB_24__VLAN_FAS" ;
VAL_ 1377 NV_Obj_01_InvTTCBildebStdA 127 "Init" ;
VAL_ 1377 NV_Obj_Warnung_Fussgaenger 0 "inaktiv" 1 "aktiv" ;
VAL_ 1377 NV_Obj_Rechts 0 "nicht_erkannt" 1 "erkannt" ;
VAL_ 1377 NV_Obj_Links 0 "nicht_erkannt" 1 "erkannt" ;
VAL_ 1377 NV_Obj_01_Klasse 0 "unbekannt" 1 "ueberfahrbar" 2 "unterfahrbar" 3 "Fussgaenger" 4 "Fussgaengergruppe" 5 "Fahrrad" 6 "Motorrad" 7 "PKW" 8 "Van" 9 "LKW" 10 "Randbebauung" 11 "Tier" 12 "Retroreflektor" 15 "Init" ;
VAL_ 1377 NV_MessZeitpunkt 8191 "Init" ;
VAL_ 1377 NV_Sensor_PositionY 2047 "Init" ;
VAL_ 1377 NV_Sensor_PositionX 4095 "Init" ;
VAL_ 1377 NV_Sensor_PositionZ 2047 "Init" ;
VAL_ 1377 NV_NichtVerfuegbar 0 "NV_verfuegbar" 1 "NV_nicht_verfuegbar" ;
VAL_ 597 NV_Obj_01_RadialDistanz 4095 "Init" ;
VAL_ 597 NV_Obj_01_WnklHoehe 15 "Init" ;
VAL_ 597 NV_Obj_01_InvTTCBildeb 1023 "Init" ;
VAL_ 597 NV_Obj_01_WnklBreite 63 "Init" ;
VAL_ 597 NV_Obj_01_RadialDistanzStdA 127 "Init" ;
VAL_ 597 NV_Obj_01_WnklBreiteStdA 7 "Init" ;
VAL_ 597 NV_Obj_01_WnklHorMitte 63 "Init" ;
VAL_ 597 NV_Obj_01_ID 0 "kein_Objekt_enthalten" 1 "ObjektID_1" 2 "ObjektID_2" 3 "ObjektID_3" 4 "ObjektID_4" 5 "ObjektID_5" 6 "ObjektID_6" 7 "ObjektID_7" 8 "ObjektID_8" 9 "ObjektID_9" 10 "ObjektID_10" 11 "ObjektID_11" 12 "ObjektID_12" 13 "ObjektID_13" 14 "ObjektID_14" 15 "Init" ;
VAL_ 597 NV_Obj_01_Gemessen 0 "Objekt_praediziert" 1 "Objekt_gemessen" 2 "Objekt_per_Feature_Tracking" 3 "Naheinscherer_oder_Ueberholer" ;
VAL_ 597 NV_Obj_01_WnklHorMitteStdA 7 "Init" ;
VAL_ 597 NV_Obj_01_WnklVertMitte 15 "Init" ;
VAL_ 598 NV_Obj_02_RadialDistanzRed 255 "Init" ;
VAL_ 598 NV_Obj_02_RadialDistanzRedStdA 15 "Init" ;
VAL_ 598 NV_Obj_02_WnklHoehe 15 "Init" ;
VAL_ 598 NV_Obj_02_WnklBreite 63 "Init" ;
VAL_ 598 NV_Obj_02_WnklHorMitte 63 "Init" ;
VAL_ 598 NV_Obj_02_Klasse 0 "unbekannt" 1 "ueberfahrbar" 2 "unterfahrbar" 3 "Fussgaenger" 4 "Fussgaengergruppe" 5 "Fahrrad" 6 "Motorrad" 7 "PKW" 8 "Van" 9 "LKW" 10 "Randbebauung" 11 "Tier" 12 "Retroreflektor" 15 "Init" ;
VAL_ 598 NV_Obj_02_WnklVertMitte 15 "Init" ;
VAL_ 598 NV_Obj_02_ID 0 "kein_Objekt_enthalten" 1 "ObjektID_1" 2 "ObjektID_2" 3 "ObjektID_3" 4 "ObjektID_4" 5 "ObjektID_5" 6 "ObjektID_6" 7 "ObjektID_7" 8 "ObjektID_8" 9 "ObjektID_9" 10 "ObjektID_10" 11 "ObjektID_11" 12 "ObjektID_12" 13 "ObjektID_13" 14 "ObjektID_14" 15 "Init" ;
VAL_ 598 NV_Obj_02_Gemessen 0 "Objekt_praediziert" 1 "Objekt_gemessen" 2 "Objekt_per_Feature_Tracking" 3 "Naheinscherer_oder_Ueberholer" ;
VAL_ 598 NV_Obj_03_WnklVertMitte 15 "Init" ;
VAL_ 598 NV_Obj_03_WnklHoehe 15 "Init" ;
VAL_ 598 NV_Obj_03_RadialDistanzRedStdA 15 "Init" ;
VAL_ 598 NV_Obj_03_RadialDistanzRed 255 "Init" ;
VAL_ 601 NV_Obj_03_WnklHorMitte 63 "Init" ;
VAL_ 601 NV_Obj_03_Gemessen 0 "Objekt_praediziert" 1 "Objekt_gemessen" 2 "Objekt_per_Feature_Tracking" 3 "Naheinscherer_oder_Ueberholer" ;
VAL_ 601 NV_Obj_03_ID 0 "kein_Objekt_enthalten" 1 "ObjektID_1" 2 "ObjektID_2" 3 "ObjektID_3" 4 "ObjektID_4" 5 "ObjektID_5" 6 "ObjektID_6" 7 "ObjektID_7" 8 "ObjektID_8" 9 "ObjektID_9" 10 "ObjektID_10" 11 "ObjektID_11" 12 "ObjektID_12" 13 "ObjektID_13" 14 "ObjektID_14" 15 "Init" ;
VAL_ 601 NV_Obj_03_Klasse 0 "unbekannt" 1 "ueberfahrbar" 2 "unterfahrbar" 3 "Fussgaenger" 4 "Fussgaengergruppe" 5 "Fahrrad" 6 "Motorrad" 7 "PKW" 8 "Van" 9 "LKW" 10 "Randbebauung" 11 "Tier" 12 "Retroreflektor" 15 "Init" ;
VAL_ 601 NV_Obj_03_WnklBreite 63 "Init" ;
VAL_ 601 NV_Obj_04_Gemessen 0 "Objekt_praediziert" 1 "Objekt_gemessen" 2 "Objekt_per_Feature_Tracking" 3 "Naheinscherer_oder_Ueberholer" ;
VAL_ 601 NV_Obj_04_ID 0 "kein_Objekt_enthalten" 1 "ObjektID_1" 2 "ObjektID_2" 3 "ObjektID_3" 4 "ObjektID_4" 5 "ObjektID_5" 6 "ObjektID_6" 7 "ObjektID_7" 8 "ObjektID_8" 9 "ObjektID_9" 10 "ObjektID_10" 11 "ObjektID_11" 12 "ObjektID_12" 13 "ObjektID_13" 14 "ObjektID_14" 15 "Init" ;
VAL_ 601 NV_Obj_04_Klasse 0 "unbekannt" 1 "ueberfahrbar" 2 "unterfahrbar" 3 "Fussgaenger" 4 "Fussgaengergruppe" 5 "Fahrrad" 6 "Motorrad" 7 "PKW" 8 "Van" 9 "LKW" 10 "Randbebauung" 11 "Tier" 12 "Retroreflektor" 15 "Init" ;
VAL_ 601 NV_Obj_04_RadialDistanzRed 255 "Init" ;
VAL_ 601 NV_Obj_04_WnklHoehe 15 "Init" ;
VAL_ 601 NV_Obj_04_WnklVertMitte 15 "Init" ;
VAL_ 601 NV_Obj_04_WnklBreite 63 "Init" ;
VAL_ 601 NV_Obj_04_RadialDistanzRedStdA 15 "Init" ;
VAL_ 601 NV_Obj_04_WnklHorMitte 63 "Init" ;
VAL_ 1635 BEM_02_Abschaltstufen 0 "Stufe 0 (keine Einschraenkungen)" 1 "Stufe 1" 2 "Stufe 2" 3 "Stufe 3" 4 "Transportmodus" 7 "Ruhestrommessmodus" ;
VAL_ 1635 BEM_STH_Zielzeit 14 "Init" 15 "Fehler" ;
VAL_ 1635 BEM_MMI_Vorwarnung 0 "keine Anzeige" 1 "Anzeige MMI-Vorwarnung" ;
VAL_ 1635 NVEM_Anf_SD_schalten 0 "Anf_SD_Nachlauf_nicht_aktiv" 1 "Anf_SD_Nachlauf_aktiv" ;
VAL_ 1635 BEM_Generatordiagnose 0 "keine Anzeige" 1 "Ladekontrollanzeige ein (Vorhalt)" 2 "rotes Batteriesymbol und Text (Generator defekt)" 3 "Hybrid_DCDC_Wandler_defekt" ;
VAL_ 1635 BEM_Red_Innengeblaese 0 "keine Reduzierung" 1 "Reduzierung Stufe 1" 2 "Reduzierung Stufe 2" 3 "Reduzierung Stufe 2 und Abschaltung Kompressor" ;
VAL_ 1635 BEM_STH_Einschaltverbot 0 "volle Verfuegbarkeit Standheizung/-lueftung" 1 "Standheizung/-lueftung nicht aktivierbar" ;
VAL_ 1635 BEM_HL_Regelung_Status 0 "HL_Regelung_inaktiv_(vor_und_waehrend_Motorstart)" 1 "HL_Regelung_Stufe_1" 2 "HL_Regelung_Stufe_2" 3 "HL_Regelung_Stufe_3" 4 "Verbrauchernotabschaltung_(VNA)" 5 "HL_Regelung_Stufe_5" 7 "Default" ;
VAL_ 1635 BEM_Ladezustand 14 "Init" 15 "Fehler" ;
VAL_ 1635 BEM_Batteriediagnose 0 "keine_Anzeige" 1 "nicht_belegt" 2 "Anzeige_aberkannte_Batterie" 3 "Anzeige_schwache_Batterie" 4 "Anzeige_Batterie_OK" 5 "Anzeige_Batterie_Laden" 6 "Anzeige_Batterie_Pruefen" 7 "Fehler" ;
VAL_ 1635 MIB_Stromsparmodus 0 "inaktiv" 1 "aktiv" ;
VAL_ 1635 BEM_REK_aktiv 0 "keine_Rekuperationsfreigabe" 1 "Rekuperationsfreigabe" ;
VAL_ 1635 NVEM_Last_Anf 0 "keine Anforderung" 1 "Verbraucher_Anforderung_Stufe_1" 2 "Verbraucher_Anforderung_Stufe_2" 3 "Verbraucher_Anforderung_Stufe_3" ;
VAL_ 1635 BEM_UBDM 0 "Init" 255 "Fehler" ;
VAL_ 1635 BEM_Anf_KL15_schalten 0 "Keine_Einschraenkung_Kl15" 1 "Empfehlung_auto_Abschaltung_Kl15" 2 "Veto_auto_Abschaltung_Kl15" 3 "Veto_auto_Abschaltung_Fahrtbetrieb" ;
VAL_ 1635 NVEM_Batterie_Service 0 "kein_Service" 1 "Service_Information1" 2 "Service_Information2" 3 "Service_Information3" ;
VAL_ 1635 NVEM_Freigabe_OnlineUpdate 0 "keine_Freigabe" 1 "Freigabe" ;
VAL_ 1635 NVEM_Freigabe_ORU4 0 "Init" 1 "keine_Freigabe" 2 "Freigabe_erteilt" 3 "Veto_Freigabe" ;
VAL_ 913 MO_Servicemodus 0 "nicht_aktiv" 1 "Service_Mode_1" 2 "Service_Mode_2" 3 "Service_Mode_3" 4 "Service_Mode_4" 5 "Service_Mode_5" 6 "Service_Mode_6" 7 "Service_Mode_7" 8 "Service_Mode_8" 9 "Service_Mode_9" 10 "Service_Mode_10" 11 "Service_Mode_11" 12 "Service_Mode_12" 13 "Service_Mode_13" 14 "Service_Mode_14" 15 "Service_Mode_15" ;
VAL_ 913 OBD_ClearMem_Inhibit 0 "FSP_Loeschen_zulaessig" 1 "FSP_Loeschen_nicht_zulaessig" ;
VAL_ 913 OBD_Sperrung_Kaltstart_Denom 0 "EVAP_Berechnung_freigegeben" 1 "EVAP_Berechnung_gesperrt" ;
VAL_ 913 MO_QBit_Aussen_Temp 0 "gueltiger_Wert" 1 "Ersatz_Init_oder_Fehlerwert" ;
VAL_ 913 OBD_Sperrung_IUMPR 0 "IUMPR_Berechnung_freigegeben" 1 "IUMPR_Berechnung_gesperrt" ;
VAL_ 913 OBD_Kaltstart_Denominator 0 "Denominator_nicht_hochzaehlen" 1 "Bedingungen_zum_Inkr_des_Kaltstart_Denom_erf" ;
VAL_ 913 OBD_Minimum_Trip 0 "kein_Min_Normed_Trip" 1 "Min_Normed_Trip" ;
VAL_ 913 OBD_Driving_Cycle 0 "kein_Driving_Cycle_erkannt" 1 "Driving_Cycle_erkannt" ;
VAL_ 913 OBD_Warm_Up_Cycle 0 "kein_Warm_Up_Cycle_erkannt" 1 "Warm_Up_Cycle_erkannt" ;
VAL_ 913 OBD_Normed_Trip 0 "kein_Normed_Trip" 1 "Normed_Trip" ;
VAL_ 2589283478 OBD_Aussen_Temp_gef 254 "Initwert" 255 "Fehler" ;
VAL_ 2589283656 ORU_Warnung 0 "keine_Anzeige" 1 "Update_unvollstaendig_Prio1" 2 "Update_fehlgeschlagen_Prio1" 3 "reserviert" ;
VAL_ 2589283656 ORU_Status 0 "IDLE" 1 "PENDING" 2 "PREPARATION" 3 "PREPARATION_HV" 4 "RUNNING" 5 "RUNNING_HV" 6 "PENDING_NOTREADY" 7 "FAILURE_POWERTRAIN_DISABLED" ;
VAL_ 1175 PH_Visualisierung 0 "Aus" 1 "Angefragt" 2 "InAnzeige" 3 "Abgefordert" 6 "Init" 7 "Fehler" ;
VAL_ 1175 PDC_Tonausgabe_Front 0 "kein_Ton" 1 "Intervallton_1" 2 "Intervallton_2" 3 "Intervallton_3" 4 "Intervallton_4" 5 "Intervallton_5" 6 "Dauerton" 7 "Fehlerton" 8 "RCTATon" ;
VAL_ 1175 PDC_Tonausgabe_Heck 0 "kein_Ton" 1 "Intervallton_1" 2 "Intervallton_2" 3 "Intervallton_3" 4 "Intervallton_4" 5 "Intervallton_5" 6 "Dauerton" 7 "Fehlerton" 8 "Erstwarnton_hinten" 9 "RCTATon" ;
VAL_ 1175 PH_nachtr_Stopp_Anf 0 "nicht_angefordert" 1 "angefordert" ;
VAL_ 1175 PH_Abschaltursache 0 "keine, bzw. System aktiv" 1 "Abschaltung durch Herausnahme R-Gang" 2 "Abschaltung ueber Geschwindigkeit" 3 "Abschaltung ueber PDC-Taster" 4 "Abschaltung wegen PLA" 5 "Abschaltung durch KL 15 Bit = 0" 6 "tbd." 7 "Fehler-/gestört Zustand, System noch aktiv" ;
VAL_ 1175 PH_Opt_Anzeige_V_ein 0 "optische Anzeige vorne nicht aktiv" 1 "optische Anzeige vorne aktiviert" ;
VAL_ 1175 PH_Opt_Anzeige_H_ein 0 "Optische Anzeige aus" 1 "optische Anzeige hinten aktiviert" ;
VAL_ 1175 PH_Opt_Anz_V_Hindernis 0 "optische Anzeige vorne meldet kein Hindernis" 1 "optische Anzeige vorne meldet Hindernis im Warnbereich" ;
VAL_ 1175 PH_Opt_Anz_H_Hindernis 0 "optische Anzeige hinten meldet kein Hindernis" 1 "optische Anzeige hinten meldet Hindernis im Warnbereich" ;
VAL_ 1175 PH_Tongeber_V_aktiv 0 "Tongeber vorne nicht aktiv" 1 "Tongeber vorne  aktiv" ;
VAL_ 1175 PH_Tongeber_H_aktiv 0 "Tongeber hinten nicht aktiv" 1 "Tongeber hinten aktiv" ;
VAL_ 1175 PH_Tongeber_mute 0 "Tongeber nicht stummgeschaltet" 1 "Tongeber stummgeschaltet" ;
VAL_ 1175 PH_Anf_Audioabsenkung 0 "Keine_Audioabsenkung" 1 "Anforderung_Audioabsenkung" ;
VAL_ 1175 PH_Tongeber_H_verfuegbar 0 "nicht verfügbar" 1 "verfügbar" ;
VAL_ 1175 PLA_Anf_Aufschaltung_RVC 0 "Keine_RVC_Aufschalteanf" 1 "RVC_Aufschalteanforderung" ;
VAL_ 1175 PH_Taster 0 "Taster_nicht_gedrueckt" 1 "Taster_gedrueckt" 2 "reserviert" 3 "Fehler" ;
VAL_ 1175 PH_Anf_Verdeck 0 "Verdeckbetrieb_freigegeben" 1 "Verdeckbetrieb_sperren" 2 "reserviert" 3 "reserviert" ;
VAL_ 1175 PH_StartStopp_Info 0 "Motorlauf_nicht_notwendig_(Stoppfreigabe)" 1 "Motoranlauf_nicht_zwingend_notwendig_(Stoppverbot,keine_Startanforderung)" 2 "Motoranlauf_zwingend_notwendig_(Startanforderung)" 3 "Systemfehler" ;
VAL_ 1175 PH_Stoermeldung 0 "keine_Anzeige_kein_Gong" 1 "Textmeldung_PDC_hinten_gestoert_mit_Gong" 2 "Textmeldung_PDC_hinten_gestoert_ohne_Gong" 3 "Textmeldung_PDC_vorn_gestoert_mit_Gong" 4 "Textmeldung_PDC_vorn_gestoert_ohne_Gong" 5 "Textmeldung_PDC_gestoert_mit_Gong" 6 "Textmeldung_PDC_gestoert_ohne_Gong" 7 "Textmeldung_PDC_seitlich_gestoert_mit_Gong" 8 "Textmeldung_PDC_seitlich_gestoert_ohne_Gong" ;
VAL_ 1175 PH_defekt 0 "PH aktiv" 1 "PH wurde aufgrund eines Defektes deaktiviert" ;
VAL_ 1175 PH_gestoert 0 "PH aktiv" 1 "PH wurde auf Grund einer Stoerung tempraer deaktiviert" ;
VAL_ 1175 PH_Systemzustand 0 "Anlage aus" 1 "Anlage durch einlegen R-Gang aktiviert" 2 "Anlage manuell durch Taster aktiviert" 3 "Anlage automatisch aktiviert" 4 "Anlage durch ARA aktiviert" 6 "Init - Initialisierungsphase nach Kl. 15 ein / Reset" 7 "Fehler-/gestört Zustand, System noch aktiv" ;
VAL_ 1175 PH_Display_Kundenwunsch 0 "Anzeige aus" 1 "Grafik" 2 "Rear View" 3 "automatisch" ;
VAL_ 1355 PH_Verschmutzungsmeldung 0 "keine_Anzeige_kein_Gong" 1 "Textmeldung_PDC_hinten_verschmutzt_mit_Gong" 2 "Textmeldung_PDC_hinten_verschmutzt_ohne_Gong" 3 "Textmeldung_PDC_vorn_verschmutzt_mit_Gong" 4 "Textmeldung_PDC_vorn_verschmutzt_ohne_Gong" 5 "Textmeldung_PDC_verschmutzt_mit_Gong" 6 "Textmeldung_PDC_verschmutzt_ohne_Gong" 7 "Textmeldung_PDC_seitlich_verschmutzt_mit_Gong" 8 "Textmeldung_PDC_seitlich_verschmutzt_ohne_Gong" ;
VAL_ 1355 PH_Aufschaltursache 0 "Anlage aus" 1 "Anlage durch einlegen R-Gang aktiviert" 2 "Anlage manuell durch Taster aktiviert" 3 "Anlage automatisch aktiviert" 4 "Anlage durch ARA aktiviert" 5 "Rueckwaertsrollen" 6 "Anlage_durch_PLA_aktiviert" 7 "Anlage_durch_IPA_aktiviert" 8 "Anlage_durch_FA_aktiviert" 9 "Anlage_durch_RBF_oder_MA_aktiviert" 10 "Anlage_durch_Smartphone_aktiviert" 11 "Anlage_durch_Jokertaste_aktiviert" 12 "Anlage_durch_Favoritentasten_aktiviert" 13 "Anlage_durch_SideViewTaster_aktiviert" 14 "Anlage_durch_RCTA_aktiviert" 15 "Anlage_durch_KAS_aktiviert" 16 "Anlage_durch_AWC_aktiviert" 30 "Init_Initialisierungsphase_nach_Kl_15_ein_oder_Reset" 31 "Fehler_gestoerter_Zustand_System_noch_aktiv" ;
VAL_ 1355 PH_Ton_Ausgabe 0 "Init" 1 "Intervallton_vorne" 2 "Intervallton_hinten" 3 "Dauerton_vorne" 4 "Dauerton_hinten" 5 "Quittierungston" 6 "Reserviert" 7 "Fehler" ;
VAL_ 1355 PH_Ton_Pausenlaenge 0 "Init" 1 "Pause_5ms" 2 "Pause_10ms" 3 "Pause_15ms" 100 "Pause_500ms" 101 "Reserviert" 126 "Reserviert" 127 "Fehler" ;
VAL_ 1355 PH_Ton_Richtung 0 "vorne" 1 "vorne_rechts" 2 "rechts" 3 "rechts_hinten" 4 "hinten" 5 "hinten_links" 6 "links" 7 "vorne_links" ;
VAL_ 1355 PH_Ton_Lautstaerke 0 "Minimallautstaerke" 1 "Lautstaerke_1" 2 "Lautstaerke_2" 3 "Lautstaerke_3" 4 "Lautstaerke_4" 5 "Lautstaerke_5" 6 "Lautstaerke_6" 7 "Maximallautstaerke" ;
VAL_ 1355 BCM_WAH_Meldung 0 "Init" 1 "Fehlermeldung_bei_Nichtverfuegbarkeit_mit_Gong" 2 "Fehlermeldung_bei_Nichtverfuegbarkeit_ohne_Gong" 3 "Anzeige_dass_Fahrzeug_erkannt_wurde_und_Funktion_aktiv_ist" 4 "Wiederanfahrhinweis_mit_Gong" 5 "Wiederanfahrhinweis_ohne_Gong" ;
VAL_ 1355 PDC_Charisma_Status 0 "Init" 1 "verfuegbar" 2 "nicht_verfuegbar" 3 "asynchron_durch_Fahrerwunsch" ;
VAL_ 1355 PDC_Charisma_FahrPr 0 "keine_Funktion" 1 "Programm_1" 2 "Programm_2" 3 "Programm_3" 4 "Programm_4" 5 "Programm_5" 6 "Programm_6" 7 "Programm_7" 8 "Programm_8" 9 "Programm_9" 10 "Programm_10" 11 "Programm_11" 12 "Programm_12" 13 "Programm_13" 14 "Programm_14" 15 "Programm_15" ;
VAL_ 2527679498 Perso_Kontonummer 0 "kein_Benutzerkonto" 1 "Benutzerkonto_1" 2 "Benutzerkonto_2" 3 "Benutzerkonto_3" 4 "Benutzerkonto_4" 5 "Benutzerkonto_5" 6 "Benutzerkonto_6" 7 "Benutzerkonto_7" ;
VAL_ 2527679498 Perso_Steuerung 0 "keine_Steuerung" 1 "Reset_alle_Konten" 2 "Reset_aktives_Konto" 3 "Kopiere_aktives_Konto_nach" 4 "Wiederherstellen_aktives_Konto" 5 "Aktivieren_aktives_Konto" 6 "Reset_Konto" 7 "Reset_alle_Fahrer" 8 "Reset_aktiver_Fahrer" 9 "Reset_Fahrer" ;
VAL_ 2527679498 Perso_Steuerungsparameter 0 "kein_Parameter" 1 "Benutzerkonto_1" 2 "Benutzerkonto_2" 3 "Benutzerkonto_3" 4 "Benutzerkonto_4" 5 "Benutzerkonto_5" 6 "Benutzerkonto_6" 7 "Benutzerkonto_7" ;
VAL_ 2527679498 Perso_Status 0 "deaktiviert" 1 "PSO_1x_aktiviert" 2 "PSO_2x_aktiviert" ;
VAL_ 2527679498 Perso_Bedienstelle 0 "Init" 1 "Kombiinstrument" 2 "ABT" ;
VAL_ 2527679498 Perso_Freigabe_Verstellung 0 "Init" 1 "freigegeben" ;
VAL_ 2527679498 Perso_Aktiv 0 "deaktiviert" 1 "aktiviert" ;
VAL_ 2527679498 IAA_PSO_wake_up 0 "wake_up_inactive" 1 "wake_up_active" ;
VAL_ 2527679498 Perso_Fahrernummer 0 "kein_Fahrer" 1 "Fahrer_1" 2 "Fahrer_2" 3 "Fahrer_3" 4 "Fahrer_4" 5 "Fahrer_5" 6 "Fahrer_6" 7 "Fahrer_7" ;
VAL_ 2527679498 Perso_Schreibschutz 0 "Schreibschutz_deaktiviert" 1 "Schreibschutz_aktiviert" ;
VAL_ 319 PreCrash_Charisma_FahrPr 0 "keine_Funktion" 1 "Programm_1" 2 "Programm_2" 3 "Programm_3" 4 "Programm_4" 5 "Programm_5" 6 "Programm_6" 7 "Programm_7" 8 "Programm_8" 9 "Programm_9" 10 "Programm_10" 11 "Programm_11" 12 "Programm_12" 13 "Programm_13" 14 "Programm_14" 15 "Programm_15" ;
VAL_ 319 PreCrash_Charisma_Status 0 "Init" 1 "verfuegbar" 2 "nicht_verfuegbar" 3 "asynchron_durch_Fahrerwunsch" ;
VAL_ 319 PreCrash_Schiebedach_schliessen 0 "keine_Schliessung" 1 "Schliessung_angefordert" ;
VAL_ 319 PreCrash_Fenster_schliessen 0 "keine_Schliessung" 1 "Schliessung_angefordert" ;
VAL_ 319 PreCrash_Blinken 0 "keine_Blinkanforderung" 1 "Warnblinken" 2 "RECAS_Blinken" 3 "Notbremsblinken" ;
VAL_ 319 SC_PreSense_FCWP 0 "Warnung_gilt_fuer_Objekte" 1 "Warnung_gitl_fuer_Fussgaenger" ;
VAL_ 319 PreCrash_Tueren_Verriegeln 0 "keine_Anforderung" 1 "Tueren_Verriegeln" ;
VAL_ 319 PreCrash_Anforderung_AFR 0 "keine_Anforderung" 1 "linke_Seite" 2 "rechte_Seite" 3 "Vorderachse" 4 "Hinterachse" 5 "Vorwarnung" 7 "Init" ;
VAL_ 319 SC_PreCrash_LED 0 "keine_Anzeige" 1 "Stufe_1_glimmen" 2 "Stufe_2_leuchten" 3 "Stufe_3_blinken" ;
VAL_ 319 PreCrash_FS_Pneumatik_ansteuern 0 "keine_Anforderung" 1 "Pneumatik_ansteuern" ;
VAL_ 319 PreCrash_BFS_Pneumatik_ansteuern 0 "keine_Anforderung" 1 "Pneumatik_ansteuern" ;
VAL_ 319 PreCrash_Fo_Pneumatik_ansteuern 0 "keine_Anforderung" 1 "Pneumatik_ansteuern" ;
VAL_ 319 PreCrash_FS_Sitzlehne_verfahren 0 "keine_Anforderung" 1 "reserviert" 2 "reserviert" 3 "Sitzlehnenkopf_in_pos_xRichtung_verfahrenvor" 4 "Sitzlehnenkopf_in_neg_xRichtung_verfahrenzurueck" 6 "reserviert" 7 "Lehnenkopfverstellung_ansteuern" ;
VAL_ 319 PreCrash_BFS_Sitzlehne_verfahren 0 "keine_Anforderung" 1 "reserviert" 2 "reserviert" 3 "Sitzlehnenkopf_in_pos_xRichtung_verfahrenvor" 4 "Sitzlehnenkopf_in_neg_xRichtung_verfahrenzurueck" 6 "reserviert" 7 "Lehnenkopfverstellung_ansteuern" ;
VAL_ 319 PreCrash_Fo_Sitzlehne_verfahren 0 "keine_Anforderung" 1 "reserviert" 2 "reserviert" 3 "Sitzlehnenkopf_in_pos_xRichtung_verfahrenvor" 4 "Sitzlehnenkopf_in_neg_xRichtung_verfahrenzurueck" ;
VAL_ 319 PreCrash_FS_KSV_verfahren 0 "keine_Anforderung" 1 "in_pos_xRichtung_verfahren" 2 "in_neg_xRichung_verfahren" 3 "in_pos_zRichtung_verfahren" 4 "in_neg_zRichtung_verfahren" 5 "in_pos_xRichtung_und_neg_zRichtung_verfahren" 6 "in_pos_x_Richtung_und_pos_zRichtung_verfahren" 7 "in_neg_xRichtung_und_neg_zRichtung_verfahren" 8 "in_neg_xRichtung_und_pos_zRichtung_verfahren" 9 "Kopfstuetze_ansteuern" ;
VAL_ 319 PreCrash_BFS_KSV_verfahren 0 "keine_Anforderung" 1 "in_pos_xRichtung_verfahren" 2 "in_neg_xRichung_verfahren" 3 "in_pos_zRichtung_verfahren" 4 "in_neg_zRichtung_verfahren" 5 "in_pos_xRichtung_und_neg_zRichtung_verfahren" 6 "in_pos_x_Richtung_und_pos_zRichtung_verfahren" 7 "in_neg_xRichtung_und_neg_zRichtung_verfahren" 8 "in_neg_xRichtung_und_pos_zRichtung_verfahren" 9 "Kopfstuetze_ansteuern" ;
VAL_ 319 PreCrash_Fo_KSV_verfahren 0 "keine_Anforderung" 1 "in_pos_xRichtung_verfahren" 2 "in_neg_xRichung_verfahren" 3 "in_pos_zRichtung_verfahren" 4 "in_neg_zRichtung_verfahren" 5 "in_pos_xRichtung_und_neg_zRichtung_verfahren" 6 "in_pos_x_Richtung_und_pos_zRichtung_verfahren" 7 "in_neg_xRichtung_und_neg_zRichtung_verfahren" 8 "in_neg_xRichtung_und_pos_zRichtung_verfahren" ;
VAL_ 319 SC_PreCrash_Warnung 0 "keine_Anzeige" 1 "latente_Vorwarnung" 2 "Vorwarnung" 3 "Akutwarnung" 4 "Eingriff" 5 "Fahreruebernahmeaufforderung" 6 "Abbiegewarnung" 7 "Basiseingriff" 8 "Heckeingriff" ;
VAL_ 319 SC_PreCrash_Texte 0 "keine_Anzeige" 1 "Systemstoerung" 2 "keine_Sensorsicht" 3 "Demomodus" 4 "System_aus" 5 "Anhaengerbetrieb" 6 "ESC_aus" 7 "zurzeit_eingeschraenkt" 8 "zurzeit_eingeschraenkt_ESP_Aus" 9 "Initialisierung" ;
VAL_ 1122 PSD_Segment_ID 0 "keine Segmentinformationen vorhanden" 1 "Fehlerwert" ;
VAL_ 1122 PSD_Vorgaenger_Segment_ID 0 "keine Segmentinformation vorhanden" 1 "Fehlerwert" ;
VAL_ 1122 PSD_Strassenkategorie 0 "Rest_Feldweg_Schotterweg_Privatweg" 1 "Ortsstraße" 2 "Kreisstraße" 3 "Landstraße" 4 "Bundesstraße" 5 "Autobahn" 7 "Init" ;
VAL_ 1122 PSD_Endkruemmung 255 "Gerade" ;
VAL_ 1122 PSD_Endkruemmung_Vorz 0 "Kruemmung_positiv" 1 "Kruemmung_negativ" ;
VAL_ 1122 PSD_Idenditaets_ID 0 "keine_Segment_Informationen_vorhanden" 1 "Fehler" ;
VAL_ 1122 PSD_ADAS_Qualitaet 0 "keine_ADAS_Qualitaet" 1 "ADAS_Qualitaet" ;
VAL_ 1122 PSD_wahrscheinlichster_Pfad 0 "Pfad_mit_geringer_Wahrscheinlichkeit" 1 "wahrscheinlichster_Pfad" ;
VAL_ 1122 PSD_Geradester_Pfad 0 "nicht_geradester_PFad" 1 "geradester_Pfad" ;
VAL_ 1122 PSD_Fahrspuren_Anzahl 0 "Einbahnstrasse_in_falsche_Richtung" 1 "eine_Fahrspur" 2 "zwei_Fahrspuren" 3 "drei_Fahrspuren" 4 "vier_Fahrspuren" 5 "fuenf_Fahrspuren" 6 "sechs_Fahrspuren" 7 "mehr_als_sechs_Fahrspuren" ;
VAL_ 1122 PSD_Bebauung 0 "ausserhalb_bebauten_Gebietes" 1 "innerhalb_bebauten_Gebietes" ;
VAL_ 1122 PSD_Segment_Komplett 0 "Segment_Attribute_nicht_komplett" 1 "Segment_Attribute_komplett" ;
VAL_ 1122 PSD_Rampe 0 "Strasse_mit_Gegenverkehr" 1 "Auffahrt_Einbahnstr" 2 "Abfahrt_Einbahnstr" 3 "Einbahnstrasse" ;
VAL_ 1122 PSD_Anfangskruemmung 255 "Gerade" ;
VAL_ 1122 PSD_Anfangskruemmung_Vorz 0 "positiv" 1 "negativ" ;
VAL_ 1122 PSD_Abzweigerichtung 0 "rects_abzweigende_Strasse" 1 "links_abzweigende_Strasse" ;
VAL_ 1123 PSD_Pos_Segment_ID 0 "keine Position gegeben" 1 "Fehlerwert" ;
VAL_ 1123 PSD_Pos_Standort_Eindeutig 0 "mehrdeutiger_Standort" 1 "eindeutiger_Standort" ;
VAL_ 1123 PSD_Pos_Fehler_Laengsrichtung 0 "Init" 1 "< 2m" 2 "< 5m" 3 "< 10m" 4 "< 20m" 5 "< 50m" 6 "> 50m" 7 "Off-Road" ;
VAL_ 1123 PSD_Pos_Fahrspur 0 "unbekannt" 1 "Erste_Spur_von_rechts" 2 "Zweite_Spur_von_rechts" 3 "Dritte_Spur_von_rechts" 4 "Vierte_Spur_von_rechts" 5 "Fuenfte_Spur_von_rechts" 6 "Sechte_Spur_von_rechts" 7 "Siebte_oder_weitere_Spur_von_rechts" ;
VAL_ 1123 PSD_Attribut_Segment_ID_05 0 "keine_Segment_Information" 1 "Fehler" ;
VAL_ 1123 PSD_Attribut_1_ID 0 "keine_Information" ;
VAL_ 1123 PSD_Attribut_2_ID 0 "keine_Information" ;
VAL_ 1123 PSD_Attribute_Komplett_05 0 "Attribute_nicht_komplett" 1 "Attribute_komplett" ;
VAL_ 1124 PSD_06_Mux 0 "Init" ;
VAL_ 1124 PSD_Sys_Segment_ID 0 "keine Segmentinformationen vorhanden" 1 "nicht zulaessig" ;
VAL_ 1124 PSD_Attribut_Segment_ID 0 "keine_Segment_Information_vorhanden" 1 "Fehler" ;
VAL_ 1124 PSD_Ges_Segment_ID 0 "keine Segmentinformationen vorhanden" 1 "nicht zulaessig" ;
VAL_ 1124 PSD_Baum_Laenge_VZ 0 "Ost" 1 "West" ;
VAL_ 1124 PSD_Steigung_1_Segment_ID 0 "keine_Segment_Information_vorhanden" 1 "Fehler" ;
VAL_ 1124 PSD_Baum_Laenge 33554431 "keine_GPS_Information" ;
VAL_ 1124 PSD_Attribut_3_ID 0 "keine_Information" ;
VAL_ 1124 PSD_Steigung_1_A_Steigung 126 "mehr_als_15_Prozent" 127 "Steigung_unbekannt" ;
VAL_ 1124 PSD_Ges_Geschwindigkeit 0 "Kein Geschwindigkeitsgebot" 1 "0 km/h < v_max <  5 km/h" 2 "5 km/h < v_max < 10km/h" 3 "10 km/h < v_max < 15 km/h" 4 "15 km/h < v_max < 20 km/h" 5 "20 km/h < v_max < 25 km/h" 6 "25 km/h < v_max < 30 km/h" 7 "30 km/h < v_max < 35 km/h" 8 "35 km/h < v_max < 40 km/h" 9 "40 km/h < v_max < 45 km/h" 10 "45 km/h < v_max < 50 km/h" 11 "50 km/h < v_max < 60 km/h" 12 "60 km/h < v_max < 70 km/h" 13 "70 km/h < v_max < 80 km/h" 14 "80 km/h < v_max < 90 km/h" 15 "90 km/h < v_max < 100 km/h" 16 "100 km/h < v_max < 110 km/h" 17 "110 km/h < v_max < 120 km/h" 18 " 120 km/h < v_max < 130 km/h" 19 "130 km/h < v_max < 140 km/h" 20 "140 km/h < v_max < 150 km/h" 21 "150 km/h < v_max < 160 km/h" 22 "160 km/h < v_max" 23 "Geschwindigkeitsgebot aufgehoben" 24 "..0x1F ungültig" ;
VAL_ 1124 PSD_Steigung_1_A_Vorz 0 "Gefaelle" 1 "Steigung" ;
VAL_ 1124 PSD_Sys_Geschwindigkeit_Einheit 0 "km/h" 1 "mph" ;
VAL_ 1124 PSD_Sys_Verkehrsrichtung 0 "Rechtsverkehr" 1 "Linksverkehr" ;
VAL_ 1124 PSD_Sys_Geometrieguete 0 "Geringe_Guete" 1 "tbd" 2 "tbd" 3 "Hohe_Guete" ;
VAL_ 1124 PSD_Sys_Mapmatchingguete 0 "geringe_Guete" 1 "res" 2 "res" 3 "hohe_Guete" ;
VAL_ 1124 PSD_Ges_Typ 0 "Geschw_Klasse_des_Kartendatensuppliers" 1 "Explizit_abgeleiteten_Begrenzung" 2 "Durch_Gesetzg_vorgeg_allgem_Gebot_fuer_uebertr_Rahmenbed" 3 "Init" ;
VAL_ 1124 PSD_Sys_Alter_Karte 0 "kleiner_1_Jahr" 1 "1_Jahr" 2 "2_Jahre" 3 "3_Jahre" 4 "4_Jahre" 5 "5_Jahre" 6 "6_Jahre" 7 "groesser_7_Jahre" ;
VAL_ 1124 PSD_Ges_Spur_Geschw_Begrenzung 0 "Gebot_fuer_alle_spuren_gueltig" ;
VAL_ 1124 PSD_Steigung_1_B_Steigung 126 "mehr_als_15_Prozent" 127 "Steigung_unbekannt" ;
VAL_ 1124 PSD_Attribut_4_ID 0 "keine_Information" ;
VAL_ 1124 PSD_Sys_Zielfuehrung 0 "Zielfuehrung nicht aktiv" 1 "Zielfuehrung aktiv" ;
VAL_ 1124 PSD_Sys_US_State 0 "kein_US_State" 1 "Alabama" 2 "Alaska" 3 "Arkansas" 4 "Arizona" 5 "California" 6 "Colorado" 7 "Conneticut" 8 "District_of_Columbia" 9 "Delaware" 10 "Florida" 11 "Georgia" 12 "Hawaii" 13 "Idaho" 14 "Illinois" 15 "Iowa" 16 "Indiana" 17 "Kansas" 18 "Kentucky" 19 "Louisiana" 20 "Massachusetts" 21 "Maryland" 22 "Maine" 23 "Michigan" 24 "Minnesota" 25 "Missouri" 26 "Mississippi" 27 "Montana" 28 "North_Carolina" 29 "North_Dakota" 30 "Nebraska" 31 "Nevada" 32 "New_Hampshire" 33 "New_Jersey" 34 "New_Mexico" 35 "New_York" 36 "Ohio" 37 "Oklahoma" 38 "Oregon" 39 "Pennsylvania" 40 "Puerto_Rico" 41 "Rhode_Island" 42 "South_Carolina" 43 "South_Dakota" 44 "Tennessee" 45 "Texas" 46 "Utah" 47 "Virginia" 48 "Virgin_Islands" 49 "Vermont" 50 "Washington" 51 "Wisconsin" 52 "West_Virginia" 53 "Wyoming" ;
VAL_ 1124 PSD_Ges_Geschwindigkeit_Gespann 0 "alle Fahrzeuge" 1 "PKW mit Gespann" 2 "LKW, Busse, etc." ;
VAL_ 1124 PSD_Baum_Breite_VZ 0 "Nord" 1 "Sued" ;
VAL_ 1124 PSD_Ges_Geschwindigkeit_Witter 0 "Witterungsunabhängig" 1 "Nässe, Regen, Niederschlag" 2 "Glätte" 3 "Nebel" ;
VAL_ 1124 PSD_Steigung_1_B_Vorz 0 "Gefaelle" 1 "Steigung" ;
VAL_ 1124 PSD_Ges_Geschwindigkeit_Tag_Anf 0 "kein Beginn definiert" 1 "Montag" 2 "Dienstag" 3 "Mittwoch" 4 "Donnerstag" 5 "Freitag" 6 "Samstag" 7 "Sonntag" ;
VAL_ 1124 PSD_Ges_Geschwindigkeit_Tag_Ende 0 "kein Ende definiert" 1 "Montag" 2 "Dienstag" 3 "Mittwoch" 4 "Donnerstag" 5 "Freitag" 6 "Samstag" 7 "Sonntag" ;
VAL_ 1124 PSD_Sys_Quali_verfuegbar 0 "Qualitaetskriterien_nicht_verfuegbar" 1 "Qualitaetskriterien_verfuegbar" ;
VAL_ 1124 PSD_Sys_Zielfuehrung_geaendert 0 "Zielfuehrung_nicht_geaendert" 1 "Zielfuehrung_geaendert" ;
VAL_ 1124 PSD_Ges_Geschwindigkeit_Std_Anf 25 "kein Beginn für stundenweise Einschränkungen" ;
VAL_ 1124 PSD_Steigung_1_Attribute_kompl 0 "Steigungen_nicht_komplett" 1 "Steigungen_komplett" ;
VAL_ 1124 PSD_Sys_Geometrieguete_erweitert 0 "Init" ;
VAL_ 1124 PSD_Steigung_2_Segment_ID 0 "keine_Segment_Information_vorhanden" 1 "Fehler" ;
VAL_ 1124 PSD_Attribut_5_ID 0 "keine_Information" ;
VAL_ 1124 PSD_Ges_Geschwindigkeit_Std_Ende 25 "kein Ende für stundenweise Einschränkungen" ;
VAL_ 1124 PSD_Steigung_2_Steigung 126 "mehr_als_15_Prozent" 127 "Steigung_unbekannt" ;
VAL_ 1124 PSD_Ges_Ueberholverbot 0 "kein Überholverbot" 1 "alle Fahrzeuge" 2 "Überholverbot für PKW mit Gespann" 3 "Überholverbot für LKW, Busse, etc." ;
VAL_ 1124 PSD_Ges_Wechselverkehrszeichen 0 "Kein Wechselverkehrszeichen" 1 "Wechselverkehrszeichen links" 2 "Wechselverkehrszeichen rechts" 3 "Wechselverkehrszeichen links und rechts" 4 "Wechselverkerhszeichen über der Fahrbahn" ;
VAL_ 1124 PSD_Steigung_2_Vorz 0 "Gefaelle" 1 "Steigung" ;
VAL_ 1124 PSD_Wechselverkehrszeichen_Typ 0 "kein_Wechselverkehrszeichen" 1 "LED_Wechselverkehrszeichen" 2 "nicht_LED_Wechselverkehrszeichen" ;
VAL_ 1124 PSD_Ges_Gesetzlich_Kategorie 0 "kein_legales_Verbot" 1 "innerorts" 2 "ausserorts" 3 "Autobahn" ;
VAL_ 1124 PSD_Attribute_Komplett_06 0 "Attribute_nicht_komplett" 1 "Attribute_komplett" ;
VAL_ 1124 PSD_Ges_Gesetzlich_Zusatz 0 "kein_Zusatz_zu_legalem_Gebot" 1 "Anhaenger_Klasse_1" 2 "Anhaenger_Klasse_2" ;
VAL_ 1124 PSD_Ges_Verkehrszeichen_Quelle 0 "VZA_kein_Onlinedienst" 1 "nur_VZA" 2 "nur_VZO" 3 "VZA_und_VZO" ;
VAL_ 1124 PSD_Steigung_2_Attribute_kompl 0 "Steigungen_nicht_komplett" 1 "Steigungen_komplett" ;
VAL_ 1124 PSD_Ges_Attribute_Komplett 0 "Attribute_nicht_komplett" 1 "Attribute_komplett" ;
